VERSION ""

NS_ :

BS_:

BU_: AIL CAB C_ECU C_ECU_GW

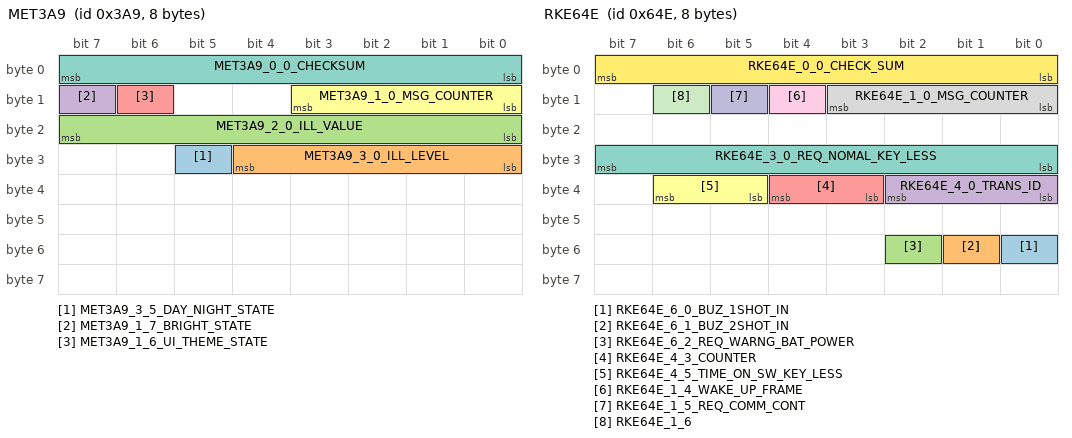
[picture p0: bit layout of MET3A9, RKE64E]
BO_ 937 MET3A9: 8 C_ECU_GW
 SG_ MET3A9_3_5_DAY_NIGHT_STATE : 29|1@1+ (1,0) [0|1] ""  AIL,CAB
 SG_ MET3A9_3_0_ILL_LEVEL : 24|5@1+ (1,0) [0|21] ""  AIL
 SG_ MET3A9_2_0_ILL_VALUE : 16|8@1+ (0.4,0) [0|100] "%"  AIL,CAB
 SG_ MET3A9_1_7_BRIGHT_STATE : 15|1@1+ (1,0) [0|1] ""  AIL,CAB
 SG_ MET3A9_1_6_UI_THEME_STATE : 14|1@1+ (1,0) [0|1] "" Vector__XXX
 SG_ MET3A9_1_0_MSG_COUNTER : 8|4@1+ (1,0) [0|15] ""  AIL,CAB
 SG_ MET3A9_0_0_CHECKSUM : 0|8@1+ (1,0) [0|255] ""  AIL,CAB

BO_ 1614 RKE64E: 8 C_ECU_GW
 SG_ RKE64E_6_0_BUZ_1SHOT_IN : 48|1@1+ (1,0) [0|1] "" Vector__XXX
 SG_ RKE64E_6_1_BUZ_2SHOT_IN : 49|1@1+ (1,0) [0|1] "" Vector__XXX
 SG_ RKE64E_6_2_REQ_WARNG_BAT_POWER : 50|1@1+ (1,0) [0|1] ""  AIL
 SG_ RKE64E_4_0_TRANS_ID : 32|3@1+ (1,0) [0|4] "" Vector__XXX
 SG_ RKE64E_4_3_COUNTER : 35|2@1+ (1,0) [0|3] "" Vector__XXX
 SG_ RKE64E_4_5_TIME_ON_SW_KEY_LESS : 37|2@1+ (1,0) [0|3] "" Vector__XXX
 SG_ RKE64E_3_0_REQ_NOMAL_KEY_LESS : 24|8@1+ (1,0) [0|8] "" Vector__XXX
 SG_ RKE64E_1_0_MSG_COUNTER : 8|4@1+ (1,0) [0|15] ""  AIL
 SG_ RKE64E_1_4_WAKE_UP_FRAME : 12|1@1+ (1,0) [0|1] "" Vector__XXX
 SG_ RKE64E_1_5_REQ_COMM_CONT : 13|1@1+ (1,0) [0|1] "" Vector__XXX
 SG_ RKE64E_1_6 : 14|1@1+ (1,0) [0|1] "" Vector__XXX
 SG_ RKE64E_0_0_CHECK_SUM : 0|8@1+ (1,0) [0|255] ""  AIL

BO_ 826 ABG33A: 8 C_ECU_GW
 SG_ ABG33A_7_0_VELOCITYCHANGE_VX_MAX : 56|8@1+ (1,0) [-101|101] "km/h" Vector__XXX
 SG_ ABG33A_6_0_VELOCITYCHANGE_VX_MAX : 48|8@1+ (1,0) [-101|101] "km/h" Vector__XXX
 SG_ ABG33A_5_0_P_SIDE_ABG_DEPLOY : 40|1@1+ (1,0) [0|1] "" Vector__XXX
 SG_ ABG33A_5_1_D_SIDE_ABG_DEPLOY : 41|1@1+ (1,0) [0|1] "" Vector__XXX
 SG_ ABG33A_5_2_FRONT_FAR_ABG_DEPLOY : 42|1@1+ (1,0) [0|1] "" Vector__XXX
 SG_ ABG33A_5_3_REAR_FAR_ABG_DEPLOY : 43|1@1+ (1,0) [0|1] "" Vector__XXX
 SG_ ABG33A_5_4_REAR_RH_ABG_DEPLOY : 44|1@1+ (1,0) [0|1] "" Vector__XXX
 SG_ ABG33A_5_5_REAR_LH_ABG_DEPLOY : 45|1@1+ (1,0) [0|1] "" Vector__XXX
 SG_ ABG33A_5_6_P_CURTAIN_ABG_DEPLOY : 46|1@1+ (1,0) [0|1] "" Vector__XXX
 SG_ ABG33A_5_7_D_CURTAIN_ABG_DEPLOY : 47|1@1+ (1,0) [0|1] "" Vector__XXX
 SG_ ABG33A_4_0_D_FRONT_ABG_DEPLOY : 32|1@1+ (1,0) [0|1] "" Vector__XXX
 SG_ ABG33A_4_1_P_FRONT_ABG_DEPLOY : 33|1@1+ (1,0) [0|1] "" Vector__XXX
 SG_ ABG33A_4_2_P_ABG_DEPLOY : 34|1@1+ (1,0) [0|1] "" Vector__XXX
 SG_ ABG33A_4_3_D_ABG_DEPLOY : 35|1@1+ (1,0) [0|1] "" Vector__XXX
 SG_ ABG33A_4_4_P_BELT_PRETENTION : 36|1@1+ (1,0) [0|1] "" Vector__XXX
 SG_ ABG33A_4_5_D_BELT_PRETENTION : 37|1@1+ (1,0) [0|1] "" Vector__XXX
 SG_ ABG33A_4_6_D_KNEE_ABG_DEPLOY : 38|1@1+ (1,0) [0|1] "" Vector__XXX
 SG_ ABG33A_4_7_P_KNEE_ABG_DEPLOY : 39|1@1+ (1,0) [0|1] "" Vector__XXX
 SG_ ABG33A_3_0_BELT_WRNING_PASS : 24|2@1+ (1,0) [0|3] "" Vector__XXX
 SG_ ABG33A_3_2_BUCKLESW_DRVR : 26|2@1+ (1,0) [0|3] "" Vector__XXX
 SG_ ABG33A_3_4_OCCUPATION_PASS : 28|2@1+ (1,0) [0|3] ""  CAB
 SG_ ABG33A_3_6_IND_ACT_ABG_PASS : 30|2@1+ (1,0) [0|3] "" Vector__XXX
 SG_ ABG33A_2_0_IND_WARN_ABG : 16|2@1+ (1,0) [0|3] "" Vector__XXX
 SG_ ABG33A_2_2_DETECT_CRUSH : 18|3@1+ (1,0) [0|7] "" Vector__XXX
 SG_ ABG33A_2_5_STATUS_CRUSH_ECALL : 21|3@1+ (1,0) [0|7] "" Vector__XXX
 SG_ ABG33A_1_0_MSG_COUNTER : 8|4@1+ (1,0) [0|15] ""  CAB
 SG_ ABG33A_1_4_FLG_ABGIND_CTRL : 12|1@1+ (1,0) [0|1] "" Vector__XXX
 SG_ ABG33A_1_5_REQ_COMM_CONT : 13|1@1+ (1,0) [0|1] "" Vector__XXX
 SG_ ABG33A_1_6_COLLISION_COUNTER : 14|2@1+ (1,0) [0|3] "" Vector__XXX
 SG_ ABG33A_0_0_CHECK_SUM : 0|8@1+ (1,0) [0|255] ""  CAB

BO_ 961 DMS3C1: 8 C_ECU_GW
 SG_ DMS3C1_7_4_SHORT_DIST_DETECT : 60|1@1+ (1,0) [0|1] "" Vector__XXX
 SG_ DMS3C1_7_5_PRESENCE_DETECT : 61|1@1+ (1,0) [0|1] ""  CAB
 SG_ DMS3C1_7_6_RADER_EQUIP : 62|1@1+ (1,0) [0|1] "" Vector__XXX
 SG_ DMS3C1_7_7_LOSING_POSTURE_DETECT : 63|1@1+ (1,0) [0|1] "" Vector__XXX
 SG_ DMS3C1_6_0_ID_RECOG_CANCEL : 48|1@1+ (1,0) [0|1] "" Vector__XXX
 SG_ DMS3C1_6_1_ID_ENABLE_FLAG : 49|1@1+ (1,0) [0|1] "" Vector__XXX
 SG_ DMS3C1_6_2_PERMIT_AVN_FLAG : 50|1@1+ (1,0) [0|1] "" Vector__XXX
 SG_ DMS3C1_6_4_DISTRACTION_STATUS : 52|1@1+ (1,0) [0|1] ""  AIL,CAB
 SG_ DMS3C1_6_5_DROWSINESS_STATUS : 53|1@1+ (1,0) [0|1] "" Vector__XXX
 SG_ DMS3C1_6_6_DROWSINESS_LV2_STATUS : 54|1@1+ (1,0) [0|1] "" Vector__XXX
 SG_ DMS3C1_6_7_NOT_DETECTED_STATUS : 55|1@1+ (1,0) [0|1] "" Vector__XXX
 SG_ DMS3C1_5_0_ID_LIST : 40|5@1+ (1,0) [0|31] "" Vector__XXX
 SG_ DMS3C1_5_5_ID_EDIT_FLAG : 45|3@1+ (1,0) [0|6] "" Vector__XXX
 SG_ DMS3C1_4_0_DMS_IND_REQ_FLAG : 32|3@1+ (1,0) [0|7] "" Vector__XXX
 SG_ DMS3C1_4_3_DMS_RECOG_STATUS : 35|1@1+ (1,0) [0|1] "" Vector__XXX
 SG_ DMS3C1_4_4_DRIVER_STATUS : 36|4@1+ (1,0) [0|3] "" Vector__XXX
 SG_ DMS3C1_3_0_DRIVER_REGIST_ID : 24|4@1+ (1,0) [0|15] ""  AIL,CAB
 SG_ DMS3C1_3_4_CUST_EDIT_FLAG : 28|2@1+ (1,0) [0|3] "" Vector__XXX
 SG_ DMS3C1_3_6_ID_RECOG_FLAG : 30|1@1+ (1,0) [0|1] "" Vector__XXX
 SG_ DMS3C1_2_0_LEVEL_DROWS : 16|3@1+ (1,0) [0|2] "" Vector__XXX
 SG_ DMS3C1_2_3_DROWS_DETECT_FLAG : 19|1@1+ (1,0) [0|1] "" Vector__XXX
 SG_ DMS3C1_2_7_DIST_DETECT_FLAG : 23|1@1+ (1,0) [0|1] ""  AIL,CAB
 SG_ DMS3C1_1_0_MSG_COUNTER : 8|4@1+ (1,0) [0|15] ""  AIL
 SG_ DMS3C1_1_4_WAKE_UP_FRAME : 12|1@1+ (1,0) [0|1] "" Vector__XXX
 SG_ DMS3C1_1_5_REQ_COMM_CONT : 13|1@1+ (1,0) [0|1] "" Vector__XXX
 SG_ DMS3C1_1_7_EYE_DIST_FLAG : 15|1@1+ (1,0) [0|1] "" Vector__XXX
 SG_ DMS3C1_0_0_CHKSUM : 0|8@1+ (1,0) [0|255] ""  AIL

BO_ 1651 ACN673: 8 C_ECU_GW
 SG_ ACN673_7_2_REQ_STRG_H : 58|2@1+ (1,0) [0|3] "" Vector__XXX
 SG_ ACN673_7_1_SEAT_H_L_AUTOIND : 57|1@1+ (1,0) [0|1] "" Vector__XXX
 SG_ ACN673_7_0_SEAT_H_R_AUTOIND : 56|1@1+ (1,0) [0|1] "" Vector__XXX
 SG_ ACN673_6_0_RR_FAN_SYMBOL : 48|1@1+ (1,0) [0|1] "" Vector__XXX
 SG_ ACN673_6_2_SEAT_H_R : 50|3@1+ (1,0) [0|7] "" Vector__XXX
 SG_ ACN673_6_5_SEAT_H_L : 53|3@1+ (1,0) [0|7] "" Vector__XXX
 SG_ ACN673_5_0_DR_ONLY : 40|2@1+ (1,0) [0|3] "" Vector__XXX
 SG_ ACN673_5_2_STRG_H : 42|2@1+ (1,0) [0|3] "" Vector__XXX
 SG_ ACN673_5_4_AC_SI_DS_SET : 44|2@1+ (1,0) [0|3] "" Vector__XXX
 SG_ ACN673_5_6_STRG_H_AUTOIND : 46|1@1+ (1,0) [0|1] "" Vector__XXX
 SG_ ACN673_5_7_AC_SI_DS_FLG : 47|1@1+ (1,0) [0|1] "" Vector__XXX
 SG_ ACN673_4_0_SEAT_HEATER_DR : 32|2@1+ (1,0) [0|3] ""  CAB
 SG_ ACN673_4_2_SEAT_HEATER_PA : 34|2@1+ (1,0) [0|3] ""  CAB
 SG_ ACN673_4_4_SEAT_HEATER : 36|1@1+ (1,0) [0|1] ""  CAB
 SG_ ACN673_4_5_TEMP_SET_TYPE : 37|2@1+ (1,0) [0|3] "" Vector__XXX
 SG_ ACN673_4_7_VENTI_SEAT_EX_HI : 39|1@1+ (1,0) [0|1] "" Vector__XXX
 SG_ ACN673_1_0_MSG_COUNTER : 8|4@1+ (1,0) [0|15] ""  CAB
 SG_ ACN673_1_6_SYNC_RR : 14|1@1+ (1,0) [0|1] "" Vector__XXX
 SG_ ACN673_1_7_RR_LOCK : 15|1@1+ (1,0) [0|1] "" Vector__XXX
 SG_ ACN673_0_0_CHECK_SUM : 0|8@1+ (1,0) [0|255] ""  CAB

BO_ 1650 ACN672: 8 C_ECU_GW
 SG_ ACN672_7_0_INFO_AUTO3MODE : 56|2@1+ (1,0) [0|3] "" Vector__XXX
 SG_ ACN672_7_2_INFO_REAR_TEMP : 58|6@1+ (1,0) [0|44] "" Vector__XXX
 SG_ ACN672_6_0_DEF : 48|1@1+ (1,0) [0|1] "" Vector__XXX
 SG_ ACN672_6_1_FAN_SYMBOL : 49|1@1+ (1,0) [0|1] "" Vector__XXX
 SG_ ACN672_6_2_REAR_MODE : 50|2@1+ (1,0) [0|3] "" Vector__XXX
 SG_ ACN672_6_4_UNIT_TEMP : 52|1@1+ (1,0) [0|1] "" Vector__XXX
 SG_ ACN672_6_5_SPEC_AC_UNIT : 53|2@1+ (1,0) [0|3] "" Vector__XXX
 SG_ ACN672_6_7_REAR_AC : 55|1@1+ (1,0) [0|1] "" Vector__XXX
 SG_ ACN672_5_0_AC_VR_MODE : 40|2@1+ (1,0) [0|3] "" Vector__XXX
 SG_ ACN672_5_2_INFO_TEMP_PASS : 42|6@1+ (1,0) [0|63] ""  AIL
 SG_ ACN672_4_0_AC_INTERRUPT_DISPLAY : 32|1@1+ (1,0) [0|1] "" Vector__XXX
 SG_ ACN672_4_1_AC_VR_ACTION : 33|1@1+ (1,0) [0|1] "" Vector__XXX
 SG_ ACN672_4_2_INFO_TEMP_DRVR : 34|6@1+ (1,0) [0|63] ""  AIL
 SG_ ACN672_3_0_MAX_AC : 24|1@1+ (1,0) [0|1] ""  CAB
 SG_ ACN672_3_1_INFO_SYNC_OR_SING : 25|1@1+ (1,0) [0|1] "" Vector__XXX
 SG_ ACN672_3_2_INFO_FULL_OR_AUTO : 26|2@1+ (1,0) [0|3] ""  CAB
 SG_ ACN672_3_4_INFO_AC_ON : 28|1@1+ (1,0) [0|1] ""  CAB
 SG_ ACN672_3_5_INFO_RDEF : 29|1@1+ (1,0) [0|1] "" Vector__XXX
 SG_ ACN672_3_6_INFO_CIRCULATION : 30|2@1+ (1,0) [0|3] "" Vector__XXX
 SG_ ACN672_2_0_INFO_MODE_VENT : 16|4@1+ (1,0) [0|15] "" Vector__XXX
 SG_ ACN672_2_4_INFO_FANONLY : 20|1@1+ (1,0) [0|1] "" Vector__XXX
 SG_ ACN672_2_5_INFO_LEV_BLOWERFAN : 21|3@1+ (1,0) [0|7] "" Vector__XXX
 SG_ ACN672_1_0_MSG_COUNTER : 8|4@1+ (1,0) [0|15] ""  AIL,CAB
 SG_ ACN672_1_4_LVL_BLOWERFAN_RR : 12|3@1+ (1,0) [0|7] "" Vector__XXX
 SG_ ACN672_1_7_REAR_AUTO : 15|1@1+ (1,0) [0|1] "" Vector__XXX
 SG_ ACN672_0_0_CHECK_SUM : 0|8@1+ (1,0) [0|255] ""  AIL,CAB

BO_ 722 ACN2D2: 8 C_ECU_GW
 SG_ ACN2D2_7_0_PD_PRESSURE : 56|8@1+ (0.0146866,0) [0|3.74509] "Mpa" Vector__XXX
 SG_ ACN2D2_6_0_TRQ_COMP_ESTM : 48|8@1+ (0.3921568627451,0) [0|100] "Nm" Vector__XXX
 SG_ ACN2D2_5_0_REQ_ENG_RPM : 40|3@1+ (1,0) [0|6] "" Vector__XXX
 SG_ ACN2D2_5_3_REQ_IDLE_COMP_RPM : 43|5@1+ (25,650) [650|1425] "rpm" Vector__XXX
 SG_ ACN2D2_4_0_LVL_PTC : 32|2@1+ (1,0) [0|3] "" Vector__XXX
 SG_ ACN2D2_4_2_MARGIN_OF_AC : 34|3@1+ (1,0) [0|7] "" Vector__XXX
 SG_ ACN2D2_4_5_LVL_BLOWER_FAN : 37|3@1+ (1,0) [0|7] "" Vector__XXX
 SG_ ACN2D2_3_0_PERMIT_ISS : 24|2@1+ (1,0) [0|3] "" Vector__XXX
 SG_ ACN2D2_3_2_TRQ_PAT_COMP_ESTM : 26|3@1+ (1,0) [0|6] "" Vector__XXX
 SG_ ACN2D2_3_5_IND_ROOM_TEMP : 29|3@1+ (1,0) [0|4] "" Vector__XXX
 SG_ ACN2D2_2_0_FAIL_TRQ_COMP_ESTM : 16|1@1+ (1,0) [0|1] "" Vector__XXX
 SG_ ACN2D2_2_1_FAIL_AC : 17|1@1+ (1,0) [0|1] "" Vector__XXX
 SG_ ACN2D2_2_2_REQ_INHIBIT_LOCKUP : 18|1@1+ (1,0) [0|1] "" Vector__XXX
 SG_ ACN2D2_2_3_AC_ON : 19|1@1+ (1,0) [0|1] "" Vector__XXX
 SG_ ACN2D2_2_4_RDEFOGSW : 20|1@1+ (1,0) [0|1] "" Vector__XXX
 SG_ ACN2D2_2_5_WARM_UP : 21|1@1+ (1,0) [0|1] "" Vector__XXX
 SG_ ACN2D2_2_6_AC_AUTO_MANUAL : 22|1@1+ (1,0) [0|1] "" Vector__XXX
 SG_ ACN2D2_2_7_COMP_TYPE : 23|1@1+ (1,0) [0|1] "" Vector__XXX
 SG_ ACN2D2_1_0_MSG_COUNTER : 8|4@1+ (1,0) [0|15] "" Vector__XXX
 SG_ ACN2D2_1_4 : 12|1@1+ (1,0) [0|1] "" Vector__XXX
 SG_ ACN2D2_1_5 : 13|1@1+ (1,0) [0|1] "" Vector__XXX
 SG_ ACN2D2_1_6 : 14|1@1+ (1,0) [0|1] "" Vector__XXX
 SG_ ACN2D2_1_7_WARM_POWER_CONT : 15|1@1+ (1,0) [0|1] "" Vector__XXX
 SG_ ACN2D2_0_0_CHECK_SUM : 0|8@1+ (1,0) [0|255] "" Vector__XXX

BO_ 1722 AVN6BA: 8 C_ECU_GW
 SG_ AVN6BA_7_0_GUIDE_LINE_REAR : 56|1@1+ (1,0) [0|1] "" Vector__XXX
 SG_ AVN6BA_7_1_GUIDE_LINE_SIDE : 57|1@1+ (1,0) [0|1] "" Vector__XXX
 SG_ AVN6BA_7_2_GUIDE_LINE_FRONT : 58|1@1+ (1,0) [0|1] "" Vector__XXX
 SG_ AVN6BA_7_3_STEER_ANGLE_INTERLOCK : 59|1@1+ (1,0) [0|1] "" Vector__XXX
 SG_ AVN6BA_7_4_BACK_CAMERA_DELAY : 60|1@1+ (1,0) [0|1] "" Vector__XXX
 SG_ AVN6BA_7_5_REQ_STOP_CAMERA_OUT : 61|1@1+ (1,0) [0|1] "" Vector__XXX
 SG_ AVN6BA_7_6_VIEW_CHANGE_SW : 62|2@1+ (1,0) [0|3] "" Vector__XXX
 SG_ AVN6BA_6_0_CLIMAITE_PA_TEMP : 48|6@1- (0.5,13) [1|44] "℃/?" Vector__XXX
 SG_ AVN6BA_6_6_CLIMATE_SYNC : 54|1@1+ (1,0) [0|1] "" Vector__XXX
 SG_ AVN6BA_6_7_CLIMATE_F_DEF : 55|1@1+ (1,0) [0|1] "" Vector__XXX
 SG_ AVN6BA_5_0_CLIMAITE_DR_TEMP : 40|6@1- (0.5,13) [1|44] "℃/?" Vector__XXX
 SG_ AVN6BA_5_6_CLIMAITE_AUTO : 46|1@1+ (1,0) [0|1] "" Vector__XXX
 SG_ AVN6BA_5_7_CLIMAITE_MAX_AC : 47|1@1+ (1,0) [0|1] "" Vector__XXX
 SG_ AVN6BA_4_0_CLIMAITE_VR : 32|3@1+ (1,0) [0|4] "" Vector__XXX
 SG_ AVN6BA_4_3_CLIMATE_AC : 35|1@1+ (1,0) [0|1] "" Vector__XXX
 SG_ AVN6BA_4_4_CLIMAITE_FAN : 36|4@1+ (1,0) [0|15] "" Vector__XXX
 SG_ AVN6BA_3_0_PERSONAL_IC_SH : 24|3@1+ (1,0) [0|7] "" Vector__XXX
 SG_ AVN6BA_3_4_CSTM_SONNER : 28|1@1+ (1,0) [0|1] "" Vector__XXX
 SG_ AVN6BA_3_5_CSTM_RAB : 29|1@1+ (1,0) [0|1] "" Vector__XXX
 SG_ AVN6BA_3_6_REQ_CHG_CSTM_RAB : 30|1@1+ (1,0) [0|1] "" Vector__XXX
 SG_ AVN6BA_3_7_CLIMATE_R_DEF : 31|1@1+ (1,0) [0|1] "" Vector__XXX
 SG_ AVN6BA_2_0_CLIMATE_PTC : 16|1@1+ (1,0) [0|1] "" Vector__XXX
 SG_ AVN6BA_2_1_CLIMATE_MODE : 17|1@1+ (1,0) [0|1] "" Vector__XXX
 SG_ AVN6BA_2_2_CLIMATE_SEAT_C_L : 18|1@1+ (1,0) [0|1] "" Vector__XXX
 SG_ AVN6BA_2_3_CLIMATE_SEAT_C_R : 19|1@1+ (1,0) [0|1] "" Vector__XXX
 SG_ AVN6BA_2_4_CLIMATE_SEAT_H_L : 20|1@1+ (1,0) [0|1] "" Vector__XXX
 SG_ AVN6BA_2_5_CLIMATE_SEAT_H_R : 21|1@1+ (1,0) [0|1] "" Vector__XXX
 SG_ AVN6BA_2_6_CLIMATE_INNER_AIR : 22|1@1+ (1,0) [0|1] "" Vector__XXX
 SG_ AVN6BA_2_7_CLIMATE_ON_OFF : 23|1@1+ (1,0) [0|1] "" Vector__XXX
 SG_ AVN6BA_1_0_MSG_COUNTER : 8|4@1+ (1,0) [0|15] "" Vector__XXX
 SG_ AVN6BA_1_4_CLIMAITE_STATUS : 12|3@1+ (1,0) [0|7] ""  CAB
 SG_ AVN6BA_1_7_CLIMAITE_ON_OFF : 15|1@1+ (1,0) [0|1] "" Vector__XXX
 SG_ AVN6BA_0_0_CHECK_SUM : 0|8@1+ (1,0) [0|255] "" Vector__XXX

BO_ 1019 AVN3FB: 8 C_ECU_GW
 SG_ AVN3FB_7_0_SMT_TIM_RESET_REQ : 56|1@1+ (1,0) [0|1] "" Vector__XXX
 SG_ AVN3FB_7_1_SMT_EG_CSTM_REQ : 57|1@1+ (1,0) [0|1] "" Vector__XXX
 SG_ AVN3FB_7_2_EYE_YEILD_CSTM : 58|1@1+ (1,0) [0|1] "" Vector__XXX
 SG_ AVN3FB_7_3_EYE_STOP_CSTM : 59|1@1+ (1,0) [0|1] "" Vector__XXX
 SG_ AVN3FB_7_4_EYE_NO_ENTRY_CSTM : 60|1@1+ (1,0) [0|1] "" Vector__XXX
 SG_ AVN3FB_7_5_MVS_CAMERA_SELECT_SW : 61|1@1+ (1,0) [0|1] "" Vector__XXX
 SG_ AVN3FB_7_7_ACPANEL_DR_ONLY : 63|1@1+ (1,0) [0|1] "" Vector__XXX
 SG_ AVN3FB_6_0_ACPANEL_PA_TEMP : 48|6@1+ (0.5,13) [1|44] "℃/?"  AIL,CAB
 SG_ AVN3FB_6_6_ACPANEL_MODE_DOWN : 54|1@1+ (1,0) [0|1] "" Vector__XXX
 SG_ AVN3FB_6_7_ACPANEL_MODE_UP : 55|1@1+ (1,0) [0|1] "" Vector__XXX
 SG_ AVN3FB_5_0_ACPANEL_DR_TEMP : 40|6@1+ (0.5,13) [1|44] "℃/?"  AIL,CAB
 SG_ AVN3FB_5_6_ACPANEL_FAN_DOWN : 46|1@1+ (1,0) [0|1] "" Vector__XXX
 SG_ AVN3FB_5_7_ACPANEL_FAN_UP : 47|1@1+ (1,0) [0|1] "" Vector__XXX
 SG_ AVN3FB_4_0_ACPANEL_FAN_LEVEL : 32|4@1+ (1,0) [0|15] "" Vector__XXX
 SG_ AVN3FB_4_4_ACPANEL_MODE_VENT : 36|4@1+ (1,0) [0|15] "" Vector__XXX
 SG_ AVN3FB_3_0_ACPANEL_PA_TEMP_DOWN : 24|1@1+ (1,0) [0|1] ""  AIL,CAB
 SG_ AVN3FB_3_1_ACPANEL_PA_TEMP_UP : 25|1@1+ (1,0) [0|1] ""  AIL,CAB
 SG_ AVN3FB_3_2_ACPANEL_DR_TEMP_DOWN : 26|1@1+ (1,0) [0|1] ""  AIL,CAB
 SG_ AVN3FB_3_3_ACPANEL_DR_TEMP_UP : 27|1@1+ (1,0) [0|1] ""  AIL,CAB
 SG_ AVN3FB_3_4_ACPANEL_SYNC : 28|1@1+ (1,0) [0|1] "" Vector__XXX
 SG_ AVN3FB_3_5_ACPANEL_AC : 29|1@1+ (1,0) [0|1] "" Vector__XXX
 SG_ AVN3FB_3_6_F_DEF_SW : 30|1@1+ (1,0) [0|1] "" Vector__XXX
 SG_ AVN3FB_3_7_R_DEF_SW : 31|1@1+ (1,0) [0|1] "" Vector__XXX
 SG_ AVN3FB_2_0_ACPANEL_AUTO : 16|1@1+ (1,0) [0|1] "" Vector__XXX
 SG_ AVN3FB_2_1_ACPANEL_MAX_AC : 17|1@1+ (1,0) [0|1] "" Vector__XXX
 SG_ AVN3FB_2_2_ACPANEL_SEAT_C_P : 18|1@1+ (1,0) [0|1] "" Vector__XXX
 SG_ AVN3FB_2_3_ACPANEL_SEAT_C_D : 19|1@1+ (1,0) [0|1] "" Vector__XXX
 SG_ AVN3FB_2_4_ACPANEL_SEAT_H_P : 20|1@1+ (1,0) [0|1] "" Vector__XXX
 SG_ AVN3FB_2_5_ACPANEL_SEAT_H_D : 21|1@1+ (1,0) [0|1] "" Vector__XXX
 SG_ AVN3FB_2_6_ACPANEL_INNER_AIR : 22|1@1+ (1,0) [0|1] "" Vector__XXX
 SG_ AVN3FB_2_7_ACPANEL_AC_ON_OFF : 23|1@1+ (1,0) [0|1] "" Vector__XXX
 SG_ AVN3FB_1_0_MSG_COUNTER : 8|4@1+ (1,0) [0|15] ""  AIL
 SG_ AVN3FB_1_4_EYE_CSTM_REQ_3FB : 12|1@1+ (1,0) [0|1] "" Vector__XXX
 SG_ AVN3FB_1_5_DDAW_WARNING_CSTM : 13|1@1+ (1,0) [0|1] "" Vector__XXX
 SG_ AVN3FB_1_6_SIGN_SWITCH_SND : 14|1@1+ (1,0) [0|1] "" Vector__XXX
 SG_ AVN3FB_1_7_SLWF_CSTM : 15|1@1+ (1,0) [0|1] "" Vector__XXX
 SG_ AVN3FB_0_0_CHECK_SUM : 0|8@1+ (1,0) [0|255] ""  AIL

BO_ 1366 CAB556: 8 CAB
 SG_ CAB556_0_0_NETWORK_STATUS : 0|64@1+ (1,0) [0|0] ""  C_ECU

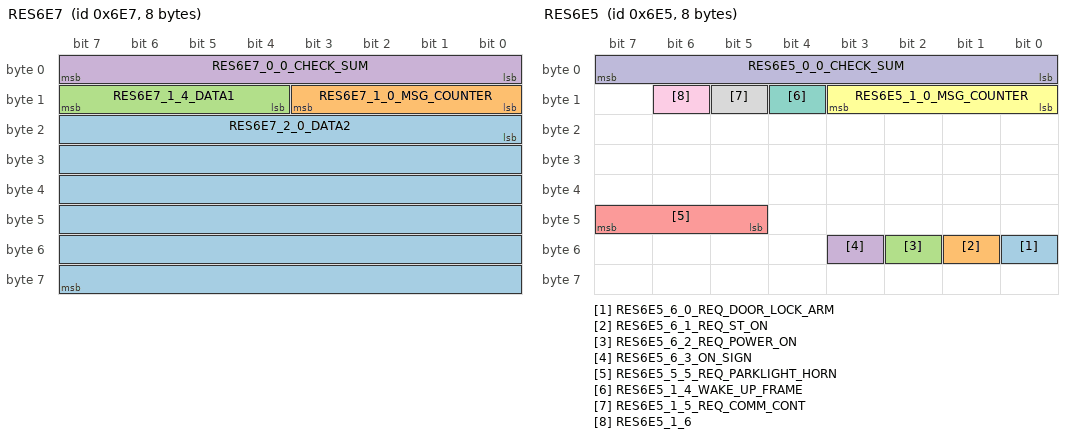
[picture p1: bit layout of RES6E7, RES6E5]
BO_ 1767 RES6E7: 8 Vector__XXX
 SG_ RES6E7_2_0_DATA2 : 16|48@1+ (1,0) [0|281474976700000] ""  C_ECU_GW
 SG_ RES6E7_1_0_MSG_COUNTER : 8|4@1+ (1,0) [0|15] ""  C_ECU_GW
 SG_ RES6E7_1_4_DATA1 : 12|4@1+ (1,0) [0|15] ""  C_ECU_GW
 SG_ RES6E7_0_0_CHECK_SUM : 0|8@1+ (1,0) [0|255] ""  C_ECU_GW

BO_ 1765 RES6E5: 8 Vector__XXX
 SG_ RES6E5_6_0_REQ_DOOR_LOCK_ARM : 48|1@1+ (1,0) [0|1] ""  C_ECU_GW
 SG_ RES6E5_6_1_REQ_ST_ON : 49|1@1+ (1,0) [0|1] ""  C_ECU_GW
 SG_ RES6E5_6_2_REQ_POWER_ON : 50|1@1+ (1,0) [0|1] ""  C_ECU_GW
 SG_ RES6E5_6_3_ON_SIGN : 51|1@1+ (1,0) [0|1] ""  C_ECU_GW
 SG_ RES6E5_5_5_REQ_PARKLIGHT_HORN : 45|3@1+ (1,0) [0|4] ""  C_ECU_GW
 SG_ RES6E5_1_0_MSG_COUNTER : 8|4@1+ (1,0) [0|15] ""  C_ECU_GW
 SG_ RES6E5_1_4_WAKE_UP_FRAME : 12|1@1+ (1,0) [0|1] ""  C_ECU_GW
 SG_ RES6E5_1_5_REQ_COMM_CONT : 13|1@1+ (1,0) [0|1] ""  C_ECU_GW
 SG_ RES6E5_1_6 : 14|1@1+ (1,0) [0|1] ""  C_ECU_GW
 SG_ RES6E5_0_0_CHECK_SUM : 0|8@1+ (1,0) [0|255] ""  C_ECU_GW

BO_ 1696 AIL6A0: 8 AIL
 SG_ AIL6A0_7_0_AIL_RENDER_STA : 56|3@1+ (1,0) [0|7] ""  C_ECU_GW
 SG_ AIL6A0_7_3_AIL_RENDER_PAT_A_DIS : 59|1@1+ (1,0) [0|1] ""  C_ECU_GW
 SG_ AIL6A0_7_4_AIL_RENDER_PAT_B_DIS : 60|1@1+ (1,0) [0|1] ""  C_ECU_GW
 SG_ AIL6A0_7_5_AIL_RENDER_PAT_C_DIS : 61|1@1+ (1,0) [0|1] ""  C_ECU_GW
 SG_ AIL6A0_7_6_AIL_RENDER_PAT_D_DIS : 62|1@1+ (1,0) [0|1] ""  C_ECU_GW
 SG_ AIL6A0_7_7_AIL_RENDER_DR_MD_DIS : 63|1@1+ (1,0) [0|1] ""  C_ECU_GW
 SG_ AIL6A0_6_0_AIL_FIRST_BRIGHT_STA : 48|4@1+ (1,0) [0|9] ""  C_ECU_GW
 SG_ AIL6A0_6_4_AIL_SECOND_BRIGHT_STA : 52|4@1+ (1,0) [0|15] ""  C_ECU_GW
 SG_ AIL6A0_5_0_AIL_SECOND_COLOR_STA : 40|6@1+ (1,0) [0|63] ""  C_ECU_GW
 SG_ AIL6A0_5_6_AIL_CSTM_PRS_DIS_REQ : 46|1@1+ (1,0) [0|1] ""  C_ECU_GW
 SG_ AIL6A0_5_7_AIL_RENDER_CSTM_DIS : 47|1@1+ (1,0) [0|1] ""  C_ECU_GW
 SG_ AIL6A0_4_0_AIL_FIRST_COLOR_STA : 32|6@1+ (1,0) [0|63] ""  C_ECU_GW
 SG_ AIL6A0_4_6_AIL_SECOND_COLOR_DIS : 38|1@1+ (1,0) [0|1] ""  C_ECU_GW
 SG_ AIL6A0_4_7_AIL_SECOND_BRIGHT_DIS : 39|1@1+ (1,0) [0|1] ""  C_ECU_GW
 SG_ AIL6A0_3_0_AIL_ADAS_VEH_DIS_STA : 24|1@1+ (1,0) [0|1] ""  C_ECU_GW
 SG_ AIL6A0_3_1_AIL_ADAS_VEH_DIS__DIS : 25|1@1+ (1,0) [0|1] ""  C_ECU_GW
 SG_ AIL6A0_3_2_AIL_ADAS_LANE_DEV_STA : 26|1@1+ (1,0) [0|1] ""  C_ECU_GW
 SG_ AIL6A0_3_3_AIL_ADAS_LANE_DEV_DIS : 27|1@1+ (1,0) [0|1] ""  C_ECU_GW
 SG_ AIL6A0_3_4_AIL_ADAS_FT_CROSS_STA : 28|1@1+ (1,0) [0|1] ""  C_ECU_GW
 SG_ AIL6A0_3_5_AIL_ADAS_FT_CROSS_DIS : 29|1@1+ (1,0) [0|1] ""  C_ECU_GW
 SG_ AIL6A0_3_6_AIL_ADAS_HANDS_FR_STA : 30|1@1+ (1,0) [0|1] ""  C_ECU_GW
 SG_ AIL6A0_3_7_AIL_ADAS_HANDS_FR_DIS : 31|1@1+ (1,0) [0|1] ""  C_ECU_GW
 SG_ AIL6A0_2_0_AIL_ADAS_EXP_STA : 16|1@1+ (1,0) [0|1] ""  C_ECU_GW
 SG_ AIL6A0_2_1_AIL_ADAS_EXP_DIS : 17|1@1+ (1,0) [0|1] ""  C_ECU_GW
 SG_ AIL6A0_2_2_AIL_NOTIFI_EXP_STA : 18|1@1+ (1,0) [0|1] ""  C_ECU_GW
 SG_ AIL6A0_2_3_AIL_NOTIFI_EXP_DIS : 19|1@1+ (1,0) [0|1] ""  C_ECU_GW
 SG_ AIL6A0_2_4_AIL_AIR_CON_EXP_STA : 20|1@1+ (1,0) [0|1] ""  C_ECU_GW
 SG_ AIL6A0_2_5_AIL_AIR_CON_EXP_DIS : 21|1@1+ (1,0) [0|1] ""  C_ECU_GW
 SG_ AIL6A0_1_0_MSG_COUNTER : 8|4@1+ (1,0) [0|15] ""  C_ECU_GW
 SG_ AIL6A0_1_4_AIL_ON_OFF_STA : 12|1@1+ (1,0) [0|1] ""  C_ECU_GW
 SG_ AIL6A0_1_6_AIL_WEL_FOL_STA : 14|1@1+ (1,0) [0|1] ""  C_ECU_GW
 SG_ AIL6A0_1_7_AIL_WEL_FOL_DIS : 15|1@1+ (1,0) [0|1] ""  C_ECU_GW
 SG_ AIL6A0_0_0_CHECK_SUM : 0|8@1+ (1,0) [0|255] ""  C_ECU_GW

BO_ 1314 AIL522: 8 AIL
 SG_ AIL522_1_4_ActiveWakeUpBit : 12|1@1+ (1,0) [0|1] ""  C_ECU
 SG_ AIL522_0_0_SourceNodeID : 0|8@1+ (1,0) [0|255] ""  C_ECU

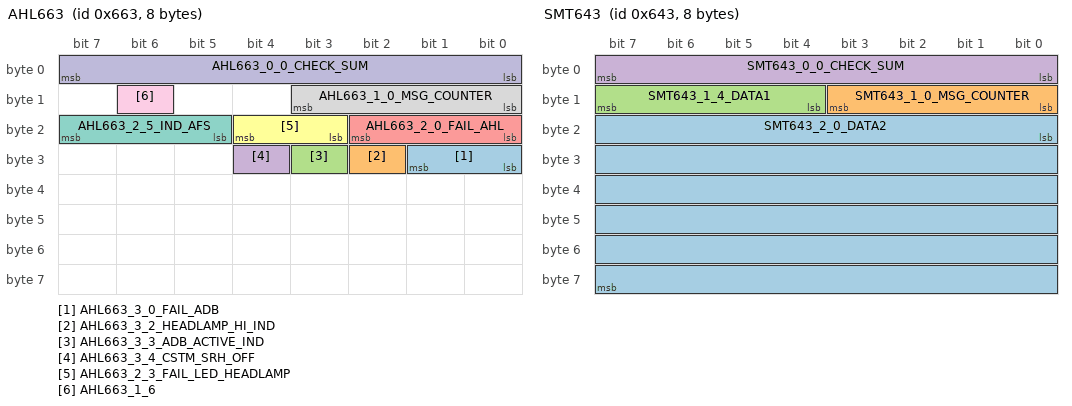
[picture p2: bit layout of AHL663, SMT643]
BO_ 1635 AHL663: 8 C_ECU_GW
 SG_ AHL663_3_0_FAIL_ADB : 24|2@1+ (1,0) [0|3] "" Vector__XXX
 SG_ AHL663_3_2_HEADLAMP_HI_IND : 26|1@1+ (1,0) [0|1] ""  CAB
 SG_ AHL663_3_3_ADB_ACTIVE_IND : 27|1@1+ (1,0) [0|1] "" Vector__XXX
 SG_ AHL663_3_4_CSTM_SRH_OFF : 28|1@1+ (1,0) [0|1] "" Vector__XXX
 SG_ AHL663_2_0_FAIL_AHL : 16|3@1+ (1,0) [0|7] "" Vector__XXX
 SG_ AHL663_2_3_FAIL_LED_HEADLAMP : 19|2@1+ (1,0) [0|3] "" Vector__XXX
 SG_ AHL663_2_5_IND_AFS : 21|3@1+ (1,0) [0|7] "" Vector__XXX
 SG_ AHL663_1_0_MSG_COUNTER : 8|4@1+ (1,0) [0|15] ""  CAB
 SG_ AHL663_1_6 : 14|1@1+ (1,0) [0|1] "" Vector__XXX
 SG_ AHL663_0_0_CHECK_SUM : 0|8@1+ (1,0) [0|255] ""  CAB

BO_ 818 PMN332: 8 C_ECU_GW
 SG_ PMN332_7_0_RES_CONTROL_STATUS : 56|2@1+ (1,0) [0|3] "" Vector__XXX
 SG_ PMN332_7_2_REQ_RES_P_LOCK : 58|1@1+ (1,0) [0|1] "" Vector__XXX
 SG_ PMN332_7_5_IGB_RELAY_REQ : 61|1@1+ (1,0) [0|1] "" Vector__XXX
 SG_ PMN332_7_6_IGA_RELAY_REQ : 62|1@1+ (1,0) [0|1] "" Vector__XXX
 SG_ PMN332_7_7_REQ_STOP_RES : 63|1@1+ (1,0) [0|1] "" Vector__XXX
 SG_ PMN332_6_0_RES_IDLE_TIME : 48|7@1+ (10,0) [0|1270] "sec" Vector__XXX
 SG_ PMN332_6_7_CUST : 55|1@1+ (1,0) [0|1] "" Vector__XXX
 SG_ PMN332_5_0_PUSHSTART_SW : 40|1@1+ (1,0) [0|1] "" Vector__XXX
 SG_ PMN332_5_1_SIG_KEY_PUSHSTART : 41|1@1+ (1,0) [0|1] "" Vector__XXX
 SG_ PMN332_5_2_STATE_MODE_POWER : 42|2@1+ (1,0) [0|2] "" Vector__XXX
 SG_ PMN332_5_4_BUZ_2SHOT_IN : 44|1@1+ (1,0) [0|1] "" Vector__XXX
 SG_ PMN332_5_5_BUZ_INTERMIT1_IN : 45|1@1+ (1,0) [0|1] "" Vector__XXX
 SG_ PMN332_5_6_BUZ_INTERMIT2_IN : 46|1@1+ (1,0) [0|1] "" Vector__XXX
 SG_ PMN332_5_7_BUZ_CONTINUE_IN : 47|1@1+ (1,0) [0|1] "" Vector__XXX
 SG_ PMN332_2_0_WARN_SSP_SIG1 : 16|1@1+ (1,0) [0|1] "" Vector__XXX
 SG_ PMN332_2_1_WARN_SSP_SIG2 : 17|3@1+ (1,0) [0|4] "" Vector__XXX
 SG_ PMN332_2_4_SMT_PWR_SIG : 20|2@1+ (1,0) [0|2] "" Vector__XXX
 SG_ PMN332_2_7_BUZ_1SHOT_IN : 23|1@1+ (1,0) [0|1] "" Vector__XXX
 SG_ PMN332_1_0_MSG_COUNTER : 8|4@1+ (1,0) [0|15] "" Vector__XXX
 SG_ PMN332_0_0_CHECK_SUM : 0|8@1+ (1,0) [0|255] "" Vector__XXX

BO_ 1603 SMT643: 8 C_ECU_GW
 SG_ SMT643_2_0_DATA2 : 16|48@1+ (1,0) [0|281474976700000] "" Vector__XXX
 SG_ SMT643_1_0_MSG_COUNTER : 8|4@1+ (1,0) [0|15] "" Vector__XXX
 SG_ SMT643_1_4_DATA1 : 12|4@1+ (1,0) [0|15] "" Vector__XXX
 SG_ SMT643_0_0_CHECK_SUM : 0|8@1+ (1,0) [0|255] "" Vector__XXX

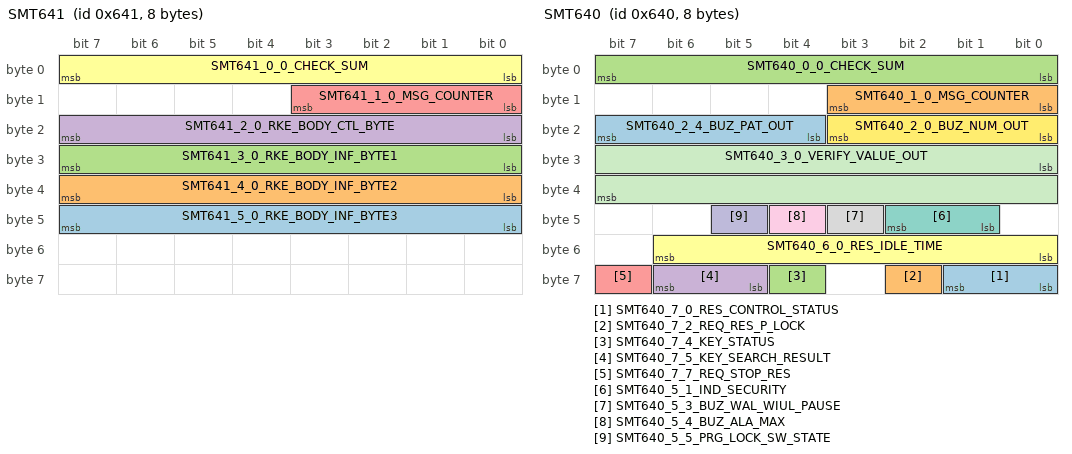
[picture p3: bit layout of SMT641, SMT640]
BO_ 1601 SMT641: 8 C_ECU_GW
 SG_ SMT641_5_0_RKE_BODY_INF_BYTE3 : 40|8@1+ (1,0) [0|255] ""  AIL
 SG_ SMT641_4_0_RKE_BODY_INF_BYTE2 : 32|8@1+ (1,0) [0|255] ""  AIL
 SG_ SMT641_3_0_RKE_BODY_INF_BYTE1 : 24|8@1+ (1,0) [0|255] ""  AIL
 SG_ SMT641_2_0_RKE_BODY_CTL_BYTE : 16|8@1+ (1,0) [0|255] ""  AIL
 SG_ SMT641_1_0_MSG_COUNTER : 8|4@1+ (1,0) [0|15] ""  AIL
 SG_ SMT641_0_0_CHECK_SUM : 0|8@1+ (1,0) [0|255] ""  AIL

BO_ 1600 SMT640: 8 C_ECU_GW
 SG_ SMT640_7_0_RES_CONTROL_STATUS : 56|2@1+ (1,0) [0|3] "" Vector__XXX
 SG_ SMT640_7_2_REQ_RES_P_LOCK : 58|1@1+ (1,0) [0|1] "" Vector__XXX
 SG_ SMT640_7_4_KEY_STATUS : 60|1@1+ (1,0) [0|1] "" Vector__XXX
 SG_ SMT640_7_5_KEY_SEARCH_RESULT : 61|2@1+ (1,0) [0|3] "" Vector__XXX
 SG_ SMT640_7_7_REQ_STOP_RES : 63|1@1+ (1,0) [0|1] "" Vector__XXX
 SG_ SMT640_6_0_RES_IDLE_TIME : 48|7@1+ (1,0) [0|1200] "sec" Vector__XXX
 SG_ SMT640_5_1_IND_SECURITY : 41|2@1+ (1,0) [0|3] "" Vector__XXX
 SG_ SMT640_5_3_BUZ_WAL_WIUL_PAUSE : 43|1@1+ (1,0) [0|1] "" Vector__XXX
 SG_ SMT640_5_4_BUZ_ALA_MAX : 44|1@1+ (1,0) [0|1] "" Vector__XXX
 SG_ SMT640_5_5_PRG_LOCK_SW_STATE : 45|1@1+ (1,0) [0|1] "" Vector__XXX
 SG_ SMT640_3_0_VERIFY_VALUE_OUT : 24|16@1+ (1,0) [0|65535] ""  AIL,CAB
 SG_ SMT640_2_0_BUZ_NUM_OUT : 16|4@1+ (1,0) [0|15] "" Vector__XXX
 SG_ SMT640_2_4_BUZ_PAT_OUT : 20|4@1+ (1,0) [0|15] "" Vector__XXX
 SG_ SMT640_1_0_MSG_COUNTER : 8|4@1+ (1,0) [0|15] ""  AIL
 SG_ SMT640_0_0_CHECK_SUM : 0|8@1+ (1,0) [0|255] ""  AIL

BO_ 816 SMT330: 8 C_ECU_GW
 SG_ SMT330_7_0 : 56|1@1+ (1,0) [0|1] "" Vector__XXX
 SG_ SMT330_7_1 : 57|1@1+ (1,0) [0|1] "" Vector__XXX
 SG_ SMT330_7_3_HF_CAPA_ERR_ST : 59|1@1+ (1,0) [0|1] "" Vector__XXX
 SG_ SMT330_7_6_HF_RESP_ERR_ST : 62|1@1+ (1,0) [0|1] "" Vector__XXX
 SG_ SMT330_6_0_REQ_MESS_PUSHSTART : 48|4@1+ (1,0) [0|8] "" Vector__XXX
 SG_ SMT330_6_4_WARN_SSP_SIG1 : 52|4@1+ (1,0) [0|14] "" Vector__XXX
 SG_ SMT330_5_1_WIUL_CUST : 41|1@1+ (1,0) [0|1] "" Vector__XXX
 SG_ SMT330_5_2_WAL_CUST : 42|1@1+ (1,0) [0|1] "" Vector__XXX
 SG_ SMT330_5_3_WARN_SSP_SIG2 : 43|2@1+ (1,0) [0|2] "" Vector__XXX
 SG_ SMT330_5_5_WARN_SSP_SIG3 : 45|3@1+ (1,0) [0|4] "" Vector__XXX
 SG_ SMT330_4_0_PUSHSTART_SW : 32|1@1+ (1,0) [0|1] "" Vector__XXX
 SG_ SMT330_4_1_SIG_KEY_PUSHSTART : 33|1@1+ (1,0) [0|1] "" Vector__XXX
 SG_ SMT330_4_2_HF_TOUCH_STATUS : 34|3@1+ (1,0) [0|7] "" Vector__XXX
 SG_ SMT330_4_5_HF_KICK_STATUS : 37|2@1+ (1,0) [0|17] "" Vector__XXX
 SG_ SMT330_3_0_BUZ_1SHOT_IN : 24|1@1+ (1,0) [0|1] "" Vector__XXX
 SG_ SMT330_3_1_BUZ_2SHOT_IN : 25|1@1+ (1,0) [0|1] "" Vector__XXX
 SG_ SMT330_3_2_BUZ_INTERMIT1_IN : 26|1@1+ (1,0) [0|1] "" Vector__XXX
 SG_ SMT330_3_3_BUZ_INTERMIT2_IN : 27|1@1+ (1,0) [0|1] "" Vector__XXX
 SG_ SMT330_3_4_BUZ_CONTINUE_IN : 28|1@1+ (1,0) [0|1] "" Vector__XXX
 SG_ SMT330_3_5_BUZ_TRPON_OK_IN : 29|1@1+ (1,0) [0|1] "" Vector__XXX
 SG_ SMT330_3_6_STATE_MODE_POWER : 30|2@1+ (1,0) [0|2] "" Vector__XXX
 SG_ SMT330_1_0_MSG_COUNTER : 8|4@1+ (1,0) [0|15] "" Vector__XXX
 SG_ SMT330_1_4_WAKE_UP_FRAME : 12|1@1+ (1,0) [0|1] "" Vector__XXX
 SG_ SMT330_1_5_REQ_COMM_CONT : 13|1@1+ (1,0) [0|1] "" Vector__XXX
 SG_ SMT330_1_6 : 14|1@1+ (1,0) [0|1] "" Vector__XXX
 SG_ SMT330_0_0_CHECK_SUM : 0|8@1+ (1,0) [0|255] "" Vector__XXX

BO_ 1622 BIU656: 8 C_ECU_GW
 SG_ BIU656_6_0_KICK_OPEN_REQ_PRG : 48|1@1+ (1,0) [0|1] "" Vector__XXX
 SG_ BIU656_6_1_KICK_CLOSE_REQ_PRG : 49|1@1+ (1,0) [0|1] "" Vector__XXX
 SG_ BIU656_6_6_CARGO_LAMP_OUT : 54|1@1+ (1,0) [0|1] "" Vector__XXX
 SG_ BIU656_6_7_PERMITT_KEY_RG_UNL : 55|1@1+ (1,0) [0|1] "" Vector__XXX
 SG_ BIU656_5_0_PRG_DRVR_OPENERSW : 40|1@1+ (1,0) [0|1] "" Vector__XXX
 SG_ BIU656_5_1_HF_PRG_OFF_SW : 41|1@1+ (1,0) [0|1] "" Vector__XXX
 SG_ BIU656_5_2_PERMIT_OPEN_RG : 42|1@1+ (1,0) [0|1] "" Vector__XXX
 SG_ BIU656_5_3_BUZ_ON_OFF : 43|1@1+ (1,0) [0|1] "" Vector__XXX
 SG_ BIU656_5_4_PRG_DRVR_SW_PERMIT : 44|1@1+ (1,0) [0|1] "" Vector__XXX
 SG_ BIU656_5_5_CSTM_HF_PRG_LOCK : 45|1@1+ (1,0) [0|1] "" Vector__XXX
 SG_ BIU656_5_6_CSTM_KICK_SENSOR : 46|1@1+ (1,0) [0|1] "" Vector__XXX
 SG_ BIU656_5_7_KICK_REQ_PRG : 47|1@1+ (1,0) [0|1] "" Vector__XXX
 SG_ BIU656_4_0_NOT_SMT_KEY_RG_SW : 32|2@1+ (1,0) [0|3] "" Vector__XXX
 SG_ BIU656_4_2_SMT_KEY_RG_SW : 34|2@1+ (1,0) [0|3] "" Vector__XXX
 SG_ BIU656_4_4_OPEN_RG_OPENER_SW : 36|2@1+ (1,0) [0|3] "" Vector__XXX
 SG_ BIU656_3_4_CHECKED_KEYNO : 28|3@1+ (1,0) [0|7] "" Vector__XXX
 SG_ BIU656_3_7_LOCKSTATUS_DRVR : 31|1@1+ (1,0) [0|1] ""  CAB
 SG_ BIU656_2_0_TRIG_LOCK_UNLOCK : 16|12@1+ (1,0) [0|4095] "" Vector__XXX
 SG_ BIU656_1_0_MSG_COUNTER : 8|4@1+ (1,0) [0|15] "" Vector__XXX
 SG_ BIU656_0_0_CHECK_SUM : 0|8@1+ (1,0) [0|255] "" Vector__XXX

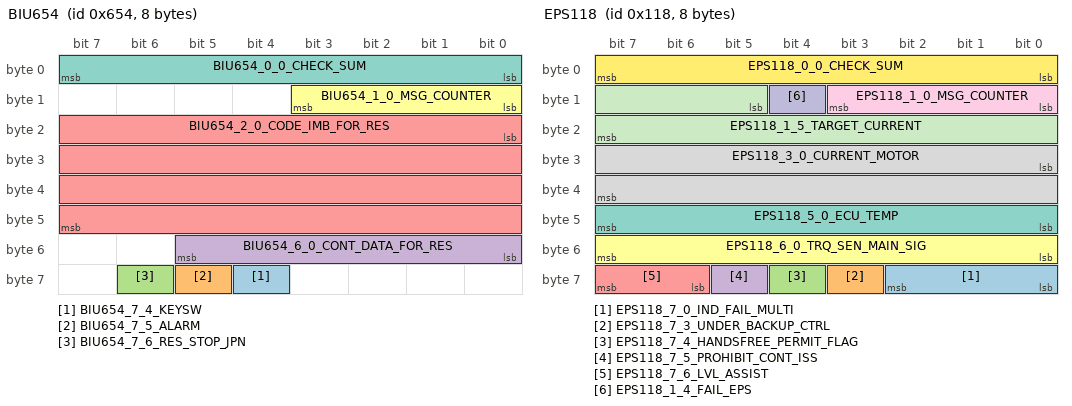
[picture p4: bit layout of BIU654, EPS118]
BO_ 1620 BIU654: 8 C_ECU_GW
 SG_ BIU654_7_4_KEYSW : 60|1@1+ (1,0) [0|1] "" Vector__XXX
 SG_ BIU654_7_5_ALARM : 61|1@1+ (1,0) [0|1] ""  AIL,CAB
 SG_ BIU654_7_6_RES_STOP_JPN : 62|1@1+ (1,0) [0|1] "" Vector__XXX
 SG_ BIU654_6_0_CONT_DATA_FOR_RES : 48|6@1+ (1,0) [0|63] "" Vector__XXX
 SG_ BIU654_2_0_CODE_IMB_FOR_RES : 16|32@1+ (1,0) [0|4294967295] "" Vector__XXX
 SG_ BIU654_1_0_MSG_COUNTER : 8|4@1+ (1,0) [0|15] ""  AIL
 SG_ BIU654_0_0_CHECK_SUM : 0|8@1+ (1,0) [0|255] ""  AIL

BO_ 1618 BIU652: 8 C_ECU_GW
 SG_ BIU652_7_0_IND_SECURITY_IMB : 56|8@1+ (1,0) [0|240] ""  AIL
 SG_ BIU652_6_0_OCCUPATION_3RDRH : 48|1@1+ (1,0) [0|1] ""  CAB
 SG_ BIU652_6_1_OCCUPATION_3RDCTR : 49|1@1+ (1,0) [0|1] ""  CAB
 SG_ BIU652_6_2_OCCUPATION_3RDLH : 50|1@1+ (1,0) [0|1] ""  CAB
 SG_ BIU652_6_3_OCCUPATION_RRRH : 51|1@1+ (1,0) [0|1] ""  CAB
 SG_ BIU652_6_4_OCCUPATION_RRCTR : 52|1@1+ (1,0) [0|1] ""  CAB
 SG_ BIU652_6_5_OCCUPATION_RRLH : 53|1@1+ (1,0) [0|1] ""  CAB
 SG_ BIU652_6_6_HORNHAZARD_RES_SIG : 54|1@1+ (1,0) [0|1] "" Vector__XXX
 SG_ BIU652_6_7_OCCUPATION_DRVR : 55|1@1+ (1,0) [0|1] ""  CAB
 SG_ BIU652_5_0_STATUS_ROOMLAMP : 40|3@1+ (1,0) [0|7] "" Vector__XXX
 SG_ BIU652_5_3_HEADLAMP_SMALL : 43|1@1+ (1,0) [0|1] "" Vector__XXX
 SG_ BIU652_5_4_ALL_UNLOCK_STATE : 44|1@1+ (1,0) [0|1] "" Vector__XXX
 SG_ BIU652_5_5_DRVR_UNLOCK_STATE : 45|1@1+ (1,0) [0|1] "" Vector__XXX
 SG_ BIU652_5_6_ALL_LOCK_STATE : 46|1@1+ (1,0) [0|1] "" Vector__XXX
 SG_ BIU652_4_0_TRIG_LOCK_UNLOCK : 32|8@1+ (1,0) [0|255] "" Vector__XXX
 SG_ BIU652_3_0_DOOR_DRVR : 24|1@1+ (1,0) [0|1] ""  AIL,CAB
 SG_ BIU652_3_1_DOOR_PASS : 25|1@1+ (1,0) [0|1] ""  AIL,CAB
 SG_ BIU652_3_2_DOOR_RRRH : 26|1@1+ (1,0) [0|1] ""  AIL,CAB
 SG_ BIU652_3_3_DOOR_RRLH : 27|1@1+ (1,0) [0|1] ""  AIL,CAB
 SG_ BIU652_3_4_DOOR_RG : 28|1@1+ (1,0) [0|1] ""  AIL,CAB
 SG_ BIU652_3_5_DOOR_TR : 29|1@1+ (1,0) [0|1] "" Vector__XXX
 SG_ BIU652_3_7_OPENSW_RG : 31|1@1+ (1,0) [0|1] "" Vector__XXX
 SG_ BIU652_2_0_LOCKSTATUS_DRVR : 16|1@1+ (1,0) [0|1] ""  AIL,CAB
 SG_ BIU652_2_1_LOCKSTATUS_PASS : 17|1@1+ (1,0) [0|1] ""  AIL,CAB
 SG_ BIU652_2_2_LOCKSTATUS_RRRH : 18|1@1+ (1,0) [0|1] ""  AIL,CAB
 SG_ BIU652_2_3_LOCKSTATUS_RRLH : 19|1@1+ (1,0) [0|1] ""  AIL,CAB
 SG_ BIU652_2_4_LOCKSTATUS_RG : 20|1@1+ (1,0) [0|1] ""  AIL,CAB
 SG_ BIU652_2_6_UNLOCK_DOORKEYSW : 22|1@1+ (1,0) [0|1] "" Vector__XXX
 SG_ BIU652_2_7_LOCK_DOORKEYSW : 23|1@1+ (1,0) [0|1] "" Vector__XXX
 SG_ BIU652_1_0_MSG_COUNTER : 8|4@1+ (1,0) [0|15] ""  AIL
 SG_ BIU652_0_0_CHECK_SUM : 0|8@1+ (1,0) [0|255] "" Vector__XXX

BO_ 1617 BIU651: 8 C_ECU_GW
 SG_ BIU651_7_0_PWPOS_RL : 56|2@1+ (1,0) [0|3] "" Vector__XXX
 SG_ BIU651_7_2_PWPOS_RR : 58|2@1+ (1,0) [0|3] "" Vector__XXX
 SG_ BIU651_7_4_PWPOS_PASS : 60|2@1+ (1,0) [0|3] "" Vector__XXX
 SG_ BIU651_7_6_PWPOS_DRVR : 62|2@1+ (1,0) [0|3] "" Vector__XXX
 SG_ BIU651_6_0_IND_ACTIVE_HBA : 48|2@1+ (1,0) [0|3] "" Vector__XXX
 SG_ BIU651_6_2_ADB_ACTIVE : 50|1@1+ (1,0) [0|1] "" Vector__XXX
 SG_ BIU651_6_3_JUDGE_ILL : 51|1@1+ (1,0) [0|1] "" Vector__XXX
 SG_ BIU651_6_4_TYPE_LO_BEAM : 52|2@1+ (1,0) [0|3] "" Vector__XXX
 SG_ BIU651_6_6_TYPE_HI_BEAM : 54|2@1+ (1,0) [0|3] "" Vector__XXX
 SG_ BIU651_5_0_SRF_ACTIVE : 40|1@1+ (1,0) [0|1] "" Vector__XXX
 SG_ BIU651_5_1_SRF_IND : 41|2@1+ (1,0) [0|3] "" Vector__XXX
 SG_ BIU651_5_3_SRF_LAMP_LIGHT : 43|1@1+ (1,0) [0|1] "" Vector__XXX
 SG_ BIU651_5_4_SRF_LAMP_LEFT : 44|1@1+ (1,0) [0|1] "" Vector__XXX
 SG_ BIU651_5_5_MSG_STATUS_HBA : 45|2@1+ (1,0) [0|3] "" Vector__XXX
 SG_ BIU651_5_7_IND_FAIL_HBA : 47|1@1+ (1,0) [0|1] "" Vector__XXX
 SG_ BIU651_4_0_BUZ_PATTERN : 32|4@1+ (1,0) [0|8] "" Vector__XXX
 SG_ BIU651_4_4_CSTM_OPE_ALARM : 36|2@1+ (1,0) [0|3] "" Vector__XXX
 SG_ BIU651_4_6_CSTM_HBA : 38|2@1+ (1,0) [0|3] "" Vector__XXX
 SG_ BIU651_3_0_HEADLAMP_PASS_SW : 24|1@1+ (1,0) [0|1] "" Vector__XXX
 SG_ BIU651_3_1_HEADLAMP_AUTO_SW : 25|1@1+ (1,0) [0|1] "" Vector__XXX
 SG_ BIU651_3_2_JUDGE_DOOR_LOCK : 26|1@1+ (1,0) [0|1] "" Vector__XXX
 SG_ BIU651_3_3_JUDGE_DOOR_UNLOCK : 27|1@1+ (1,0) [0|1] ""  CAB
 SG_ BIU651_3_4_HEADLAMP_Lo_SW : 28|1@1+ (1,0) [0|1] "" Vector__XXX
 SG_ BIU651_3_5_HEADLAMP_HI_SW : 29|1@1+ (1,0) [0|1] "" Vector__XXX
 SG_ BIU651_3_6_WIPER_AUTO_SW : 30|1@1+ (1,0) [0|1] "" Vector__XXX
 SG_ BIU651_3_7_PRG_LIN_MEMORY_ON_OFF : 31|1@1+ (1,0) [0|1] "" Vector__XXX
 SG_ BIU651_2_0_CSTM_ILLUMI_SSR : 16|1@1+ (1,0) [0|1] "" Vector__XXX
 SG_ BIU651_2_1_HANDLE : 17|1@1+ (1,0) [0|1] "" Vector__XXX
 SG_ BIU651_2_2_CSTM_SMT : 18|1@1+ (1,0) [0|1] "" Vector__XXX
 SG_ BIU651_2_3_AJARDOOR_STATUS : 19|1@1+ (1,0) [0|1] "" Vector__XXX
 SG_ BIU651_2_4_ONETOUCH_LAMP_OUT : 20|1@1+ (1,0) [0|1] "" Vector__XXX
 SG_ BIU651_2_5_PRG_FAIL_FLAG : 21|1@1+ (1,0) [0|1] "" Vector__XXX
 SG_ BIU651_2_6_CSTM_PSMECU : 22|1@1+ (1,0) [0|1] "" Vector__XXX
 SG_ BIU651_2_7_STATE_REGIST_DEL : 23|1@1+ (1,0) [0|1] "" Vector__XXX
 SG_ BIU651_1_0_MSG_COUNTER : 8|4@1+ (1,0) [0|15] "" Vector__XXX
 SG_ BIU651_1_4_SRPOS : 12|3@1+ (1,0) [0|7] "" Vector__XXX
 SG_ BIU651_1_7_WIPER_INT_STATUS : 15|1@1+ (1,0) [0|1] "" Vector__XXX
 SG_ BIU651_0_0_CHECK_SUM : 0|8@1+ (1,0) [0|255] "" Vector__XXX

BO_ 940 BIU3AC: 8 C_ECU_GW
 SG_ BIU3AC_7_0_HEADLAMP_SMALL : 56|1@1+ (1,0) [0|1] ""  CAB
 SG_ BIU3AC_7_1_HEADLAMP_LO_REQ : 57|1@1+ (1,0) [0|1] "" Vector__XXX
 SG_ BIU3AC_7_2_HEADLAMP_HI_REQ : 58|1@1+ (1,0) [0|1] "" Vector__XXX
 SG_ BIU3AC_7_3_FT_FOG_RELAY_REQ : 59|1@1+ (1,0) [0|1] "" Vector__XXX
 SG_ BIU3AC_7_4_FOGLAMP_RR : 60|1@1+ (1,0) [0|1] "" Vector__XXX
 SG_ BIU3AC_7_5_DRL : 61|1@1+ (1,0) [0|1] "" Vector__XXX
 SG_ BIU3AC_7_6_WIPER_FRONT : 62|1@1+ (1,0) [0|1] ""  CAB
 SG_ BIU3AC_7_7_RDEF_RELAY_REQ : 63|1@1+ (1,0) [0|1] "" Vector__XXX
 SG_ BIU3AC_6_0_RDEFOGSW : 48|1@1+ (1,0) [0|1] "" Vector__XXX
 SG_ BIU3AC_6_1_CSTM_PRG : 49|1@1+ (1,0) [0|1] "" Vector__XXX
 SG_ BIU3AC_6_2_FAIL_SHIFTLOCKSOL : 50|1@1+ (1,0) [0|1] "" Vector__XXX
 SG_ BIU3AC_6_3_REQ_CANCEL_ISS : 51|1@1+ (1,0) [0|1] "" Vector__XXX
 SG_ BIU3AC_6_4_REVERSE_MT : 52|1@1+ (1,0) [0|1] ""  AIL,CAB
 SG_ BIU3AC_6_5_HANDBRAKE : 53|1@1+ (1,0) [0|1] ""  AIL,CAB
 SG_ BIU3AC_6_6_BRAKELAMPSW : 54|1@1+ (1,0) [0|1] ""  AIL,CAB
 SG_ BIU3AC_6_7_TOWING_SW : 55|1@1+ (1,0) [0|1] "" Vector__XXX
 SG_ BIU3AC_5_0_LANE_OFF_SW : 40|2@1+ (1,0) [0|3] "" Vector__XXX
 SG_ BIU3AC_5_2_PCR_OFF_SW : 42|2@1+ (1,0) [0|3] "" Vector__XXX
 SG_ BIU3AC_5_4_DIMMER_CANCEL : 44|1@1+ (1,0) [0|1] ""  AIL,CAB
 SG_ BIU3AC_5_5_KEYSW : 45|1@1+ (1,0) [0|1] "" Vector__XXX
 SG_ BIU3AC_5_6_IND_ND_SHIFTLOCK : 46|1@1+ (1,0) [0|1] "" Vector__XXX
 SG_ BIU3AC_4_0_DOOR_DRVR : 32|1@1+ (1,0) [0|1] ""  AIL,CAB
 SG_ BIU3AC_4_1_DOOR_PASS : 33|1@1+ (1,0) [0|1] ""  AIL,CAB
 SG_ BIU3AC_4_2_DOOR_RRRH : 34|1@1+ (1,0) [0|1] ""  AIL,CAB
 SG_ BIU3AC_4_3_DOOR_RRLH : 35|1@1+ (1,0) [0|1] ""  AIL,CAB
 SG_ BIU3AC_4_4_DOOR_RG : 36|1@1+ (1,0) [0|1] ""  AIL,CAB
 SG_ BIU3AC_4_5_DOOR_TR : 37|1@1+ (1,0) [0|1] ""  AIL,CAB
 SG_ BIU3AC_4_6_HOOD_CLOSE : 38|1@1+ (1,0) [0|1] ""  CAB
 SG_ BIU3AC_4_7_HOOD_OPEN : 39|1@1+ (1,0) [0|1] ""  CAB
 SG_ BIU3AC_3_0_GW_STSW_RES : 24|1@1+ (1,0) [0|1] "" Vector__XXX
 SG_ BIU3AC_3_1_GW_POWER_RES : 25|2@1+ (1,0) [0|2] "" Vector__XXX
 SG_ BIU3AC_3_3_ST1 : 27|1@1+ (1,0) [0|1] "" Vector__XXX
 SG_ BIU3AC_3_4_ST2 : 28|1@1+ (1,0) [0|1] "" Vector__XXX
 SG_ BIU3AC_3_5_ACC : 29|1@1+ (1,0) [0|1] ""  CAB
 SG_ BIU3AC_3_6_IGA : 30|1@1+ (1,0) [0|1] ""  AIL,CAB
 SG_ BIU3AC_3_7_BAT_BACKUP : 31|1@1+ (1,0) [0|1] ""  AIL,CAB
 SG_ BIU3AC_2_0_CSTM_AC : 16|1@1+ (1,0) [0|1] "" Vector__XXX
 SG_ BIU3AC_2_1_IMB_SMT : 17|2@1+ (1,0) [0|3] "" Vector__XXX
 SG_ BIU3AC_2_3_CSTM_WGN_SDN : 19|1@1+ (1,0) [0|1] ""  CAB
 SG_ BIU3AC_2_4_VAL_SEAT_BACK_CTSM : 20|1@1+ (1,0) [0|1] "" Vector__XXX
 SG_ BIU3AC_2_5_VAL_MIR_AFOLD_CTSM : 21|1@1+ (1,0) [0|1] "" Vector__XXX
 SG_ BIU3AC_2_6_VAL_MIR_RTILT_CTSM : 22|1@1+ (1,0) [0|1] "" Vector__XXX
 SG_ BIU3AC_2_7_WIPER_REAR : 23|1@1+ (1,0) [0|1] "" Vector__XXX
 SG_ BIU3AC_1_0_MSG_COUNTER : 8|4@1+ (1,0) [0|15] ""  AIL,CAB
 SG_ BIU3AC_1_4_PADDLESHIFT_DOWN_SW : 12|1@1+ (1,0) [0|1] "" Vector__XXX
 SG_ BIU3AC_1_5_PADDLESHIFT_UP_SW : 13|1@1+ (1,0) [0|1] "" Vector__XXX
 SG_ BIU3AC_1_6_MANUALMODE_SW : 14|1@1+ (1,0) [0|1] "" Vector__XXX
 SG_ BIU3AC_0_0_CHECK_SUM : 0|8@1+ (1,0) [0|255] ""  AIL,CAB

BO_ 1616 BIU650: 8 C_ECU_GW
 SG_ BIU650_7_0_Reserved : 56|1@1+ (1,0) [0|1] "" Vector__XXX
 SG_ BIU650_7_1_Reserved : 57|1@1+ (1,0) [0|1] "" Vector__XXX
 SG_ BIU650_7_2_Reserved : 58|1@1+ (1,0) [0|1] "" Vector__XXX
 SG_ BIU650_7_3_DOOR_LINK_SW_STS : 59|1@1+ (1,0) [0|1] "" Vector__XXX
 SG_ BIU650_7_4_Reserved : 60|1@1+ (1,0) [0|1] "" Vector__XXX
 SG_ BIU650_6_0_Reserved : 48|3@1+ (1,0) [0|7] "" Vector__XXX
 SG_ BIU650_6_3_RR_WIPER_STATUS : 51|2@1+ (1,0) [0|3] "" Vector__XXX
 SG_ BIU650_6_5_WIPER_SENSITIVITY_CTM : 53|2@1+ (1,0) [0|3] "" Vector__XXX
 SG_ BIU650_5_0_Reserved : 40|1@1+ (1,0) [0|1] ""  AIL,CAB
 SG_ BIU650_5_1_Reserved : 41|1@1+ (1,0) [0|1] "" Vector__XXX
 SG_ BIU650_5_2_FMH_DOOR_LOCK : 42|2@1+ (1,0) [0|3] ""  AIL,CAB
 SG_ BIU650_5_4_LMH_DOOR_LOCK : 44|2@1+ (1,0) [0|3] "" Vector__XXX
 SG_ BIU650_4_0_REQ_OPE_AUTOLIGHT : 32|2@1+ (1,0) [0|3] "" Vector__XXX
 SG_ BIU650_4_2_STATE_SHINSSR : 34|2@1+ (1,0) [0|3] "" Vector__XXX
 SG_ BIU650_4_4_STATE_RLS_FAIL : 36|2@1+ (1,0) [0|3] "" Vector__XXX
 SG_ BIU650_3_0_REQ_FWASHER_ITLOCK : 24|1@1+ (1,0) [0|1] "" Vector__XXX
 SG_ BIU650_3_1_FWIPER_RTN : 25|1@1+ (1,0) [0|1] "" Vector__XXX
 SG_ BIU650_3_2_TURN_LAMP_STATE_LEFT : 26|1@1+ (1,0) [0|1] "" Vector__XXX
 SG_ BIU650_3_3_TURN_LAMP_STATE_RIGHT : 27|1@1+ (1,0) [0|1] "" Vector__XXX
 SG_ BIU650_3_4_Reserved : 28|1@1+ (1,0) [0|1] "" Vector__XXX
 SG_ BIU650_2_0_HEADLAMP_SMALL_SW : 16|1@1+ (1,0) [0|1] "" Vector__XXX
 SG_ BIU650_2_1_HEADLAMP_LO_SW : 17|1@1+ (1,0) [0|1] "" Vector__XXX
 SG_ BIU650_2_2_HEADLAMP_OFF_SW : 18|1@1+ (1,0) [0|1] "" Vector__XXX
 SG_ BIU650_2_3_HEADLAMP_Hi_SW : 19|1@1+ (1,0) [0|1] "" Vector__XXX
 SG_ BIU650_2_4_HEAD_LAMP_PASS_SW : 20|1@1+ (1,0) [0|1] "" Vector__XXX
 SG_ BIU650_2_5_FFOG_SW : 21|1@1+ (1,0) [0|1] "" Vector__XXX
 SG_ BIU650_2_6_RFOG_SW : 22|1@1+ (1,0) [0|1] "" Vector__XXX
 SG_ BIU650_1_0_MSG_COUNTER : 8|4@1+ (1,0) [0|15] ""  AIL
 SG_ BIU650_0_0_CHECK_SUM : 0|8@1+ (1,0) [0|255] ""  AIL

BO_ 280 EPS118: 8 C_ECU_GW
 SG_ EPS118_7_0_IND_FAIL_MULTI : 56|3@1+ (1,0) [0|6] "" Vector__XXX
 SG_ EPS118_7_3_UNDER_BACKUP_CTRL : 59|1@1+ (1,0) [0|1] "" Vector__XXX
 SG_ EPS118_7_4_HANDSFREE_PERMIT_FLAG : 60|1@1+ (1,0) [0|1] ""  CAB
 SG_ EPS118_7_5_PROHIBIT_CONT_ISS : 61|1@1+ (1,0) [0|1] "" Vector__XXX
 SG_ EPS118_7_6_LVL_ASSIST : 62|2@1+ (1,0) [0|2] "" Vector__XXX
 SG_ EPS118_6_0_TRQ_SEN_MAIN_SIG : 48|8@1- (0.0732,0) [-9.3696|9.2964] "Nm" Vector__XXX
 SG_ EPS118_5_0_ECU_TEMP : 40|8@1+ (1,-40) [-40|215] "℃" Vector__XXX
 SG_ EPS118_3_0_CURRENT_MOTOR : 24|16@1+ (0.1,0) [0|6553.5] "A" Vector__XXX
 SG_ EPS118_1_0_MSG_COUNTER : 8|4@1+ (1,0) [0|15] "" Vector__XXX
 SG_ EPS118_1_4_FAIL_EPS : 12|1@1+ (1,0) [0|1] "" Vector__XXX
 SG_ EPS118_1_5_TARGET_CURRENT : 13|11@1- (0.1,0) [-102.4|102.3] "Arms" Vector__XXX
 SG_ EPS118_0_0_CHECK_SUM : 0|8@1+ (1,0) [0|255] "" Vector__XXX

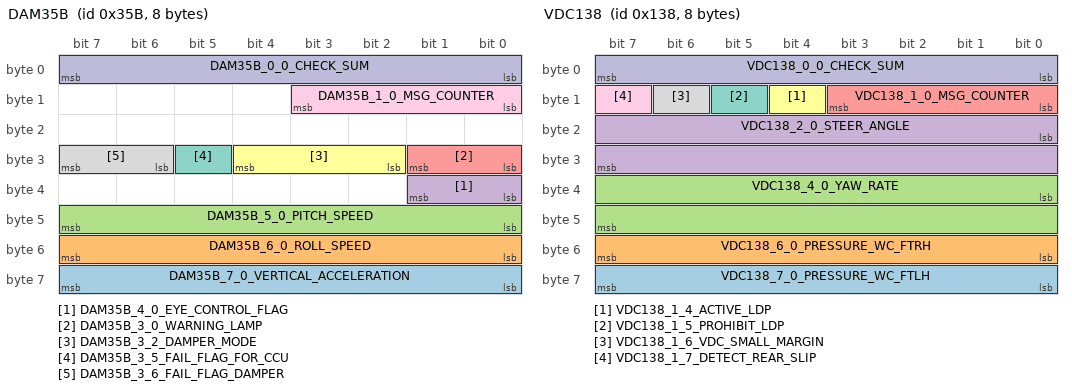
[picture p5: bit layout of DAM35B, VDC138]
BO_ 859 DAM35B: 8 C_ECU_GW
 SG_ DAM35B_7_0_VERTICAL_ACCELERATION : 56|8@1- (0.05,0) [-6.4|6.35] "m/s2" Vector__XXX
 SG_ DAM35B_6_0_ROLL_SPEED : 48|8@1- (0.15,0) [-19.2|19.05] "deg/s" Vector__XXX
 SG_ DAM35B_5_0_PITCH_SPEED : 40|8@1- (0.3,0) [-38.4|38.1] "deg/s" Vector__XXX
 SG_ DAM35B_4_0_EYE_CONTROL_FLAG : 32|2@1+ (1,0) [0|3] "" Vector__XXX
 SG_ DAM35B_3_0_WARNING_LAMP : 24|2@1+ (1,0) [0|3] "" Vector__XXX
 SG_ DAM35B_3_2_DAMPER_MODE : 26|3@1+ (1,0) [0|7] ""  CAB
 SG_ DAM35B_3_5_FAIL_FLAG_FOR_CCU : 29|1@1+ (1,0) [0|1] "" Vector__XXX
 SG_ DAM35B_3_6_FAIL_FLAG_DAMPER : 30|2@1+ (1,0) [0|3] "" Vector__XXX
 SG_ DAM35B_1_0_MSG_COUNTER : 8|4@1+ (1,0) [0|15] "" Vector__XXX
 SG_ DAM35B_0_0_CHECK_SUM : 0|8@1+ (1,0) [0|255] "" Vector__XXX

BO_ 811 EPB32B: 8 C_ECU_GW
 SG_ EPB32B_7_0_AVH_TARGET_PRESS : 56|8@1+ (0.0235,0) [0|255] "MPa" Vector__XXX
 SG_ EPB32B_6_0_VEHICLE_RUN_STOP_FLG : 48|2@1+ (1,0) [0|3] "" Vector__XXX
 SG_ EPB32B_6_2_REQ_HILL_P_CAUTION : 50|1@1+ (1,0) [0|1] "" Vector__XXX
 SG_ EPB32B_5_0_FLG_AVH_OILPRES_EPB : 40|1@1+ (1,0) [0|1] "" Vector__XXX
 SG_ EPB32B_5_1_FLG_AVH : 41|1@1+ (1,0) [0|1] "" Vector__XXX
 SG_ EPB32B_5_2_AVH_INTENSIFY_PRES : 42|1@1+ (1,0) [0|1] "" Vector__XXX
 SG_ EPB32B_5_3_BREAK_IND : 43|2@1+ (1,0) [0|3] "" Vector__XXX
 SG_ EPB32B_5_5_AVH_ON_LAMP : 45|1@1+ (1,0) [0|1] "" Vector__XXX
 SG_ EPB32B_5_6_AVH_FUNC_ON_LUMP : 46|1@1+ (1,0) [0|1] "" Vector__XXX
 SG_ EPB32B_5_7_AVH_ACTIVE : 47|1@1+ (1,0) [0|1] "" Vector__XXX
 SG_ EPB32B_4_0_BUZZER : 32|2@1+ (1,0) [0|3] "" Vector__XXX
 SG_ EPB32B_4_2_HILL_HOLD_ON_LAMP : 34|1@1+ (1,0) [0|1] "" Vector__XXX
 SG_ EPB32B_4_3_CLAMP_LAMP : 35|2@1+ (1,0) [0|3] "" Vector__XXX
 SG_ EPB32B_4_5_WARN_LAMP : 37|2@1+ (1,0) [0|3] "" Vector__XXX
 SG_ EPB32B_4_7_WARN_EPB_MET_LCD : 39|1@1+ (1,0) [0|1] "" Vector__XXX
 SG_ EPB32B_3_0_STATUS_EPB : 24|3@1+ (1,0) [0|7] ""  AIL,CAB
 SG_ EPB32B_3_3_DYNAMIC_PARKING : 27|1@1+ (1,0) [0|1] "" Vector__XXX
 SG_ EPB32B_3_4_HILL_HOLD_RUN_FLG : 28|1@1+ (1,0) [0|1] "" Vector__XXX
 SG_ EPB32B_3_5_INHIBIT_ISS_DELAY : 29|1@1+ (1,0) [0|1] "" Vector__XXX
 SG_ EPB32B_3_6_INHIBIT_ISS : 30|1@1+ (1,0) [0|1] "" Vector__XXX
 SG_ EPB32B_3_7_AVH_PERMIT_CONT_ACC : 31|1@1+ (1,0) [0|1] "" Vector__XXX
 SG_ EPB32B_2_0_ERR_INFO : 16|2@1+ (1,0) [0|3] "" Vector__XXX
 SG_ EPB32B_2_2_EPB_FAIL_FLG1 : 18|1@1+ (1,0) [0|1] "" Vector__XXX
 SG_ EPB32B_2_3_EPB_FAIL_FLG2 : 19|1@1+ (1,0) [0|1] "" Vector__XXX
 SG_ EPB32B_2_4_EPB_FAIL_FLG3 : 20|1@1+ (1,0) [0|1] "" Vector__XXX
 SG_ EPB32B_1_0_MSG_COUNTER : 8|4@1+ (1,0) [0|15] ""  AIL,CAB
 SG_ EPB32B_1_4_WAKE_UP_FRAME : 12|1@1+ (1,0) [0|1] "" Vector__XXX
 SG_ EPB32B_1_5_REQ_COMM_CONT : 13|1@1+ (1,0) [0|1] "" Vector__XXX
 SG_ EPB32B_1_6 : 14|1@1+ (1,0) [0|1] "" Vector__XXX
 SG_ EPB32B_0_0_CHECK_SUM : 0|8@1+ (1,0) [0|255] ""  AIL,CAB

BO_ 313 VDC139: 8 C_ECU_GW
 SG_ VDC139_7_4_FAIL_PRESSURE_SSR : 60|1@1+ (1,0) [0|1] "" Vector__XXX
 SG_ VDC139_7_5_STATUS_EPB : 61|3@1+ (1,0) [0|7] "" Vector__XXX
 SG_ VDC139_6_0_SSR_N_PRESS : 48|12@1+ (1,0) [193|3896] "" Vector__XXX
 SG_ VDC139_5_0_PRESSURE_BRAKE : 40|8@1+ (0.13058823529412,0) [0|25] "MPa"  CAB
 SG_ VDC139_4_0_HDC_STATUS : 32|2@1+ (1,0) [0|3] "" Vector__XXX
 SG_ VDC139_4_2_BRAKELAMPSW : 34|1@1+ (1,0) [0|1] "" Vector__XXX
 SG_ VDC139_4_3_FAIL_BRAKELAMPSW : 35|1@1+ (1,0) [0|1] "" Vector__XXX
 SG_ VDC139_4_4_ACTIVATE_ABS : 36|1@1+ (1,0) [0|1] ""  CAB
 SG_ VDC139_4_5_ACTIVATE_TCS : 37|1@1+ (1,0) [0|1] ""  CAB
 SG_ VDC139_4_6_CONT_OVER_STR : 38|1@1+ (1,0) [0|1] "" Vector__XXX
 SG_ VDC139_4_7_CONT_UNDER_STR : 39|1@1+ (1,0) [0|1] "" Vector__XXX
 SG_ VDC139_3_5_FAIL_VDC_SSR : 29|1@1+ (1,0) [0|1] "" Vector__XXX
 SG_ VDC139_3_6_FAIL_SPD_SSR_FHI : 30|1@1+ (1,0) [0|1] "" Vector__XXX
 SG_ VDC139_3_7_FAIL_ABS_SYS : 31|1@1+ (1,0) [0|1] "" Vector__XXX
 SG_ VDC139_2_0_SPD_WHEEL_AVE : 16|13@1+ (0.05625,0) [0|299.98125] "km/h"  AIL,CAB
 SG_ VDC139_1_0_MSG_COUNTER : 8|4@1+ (1,0) [0|15] ""  AIL,CAB
 SG_ VDC139_1_4_FAIL_HDC_SYS : 12|1@1+ (1,0) [0|1] "" Vector__XXX
 SG_ VDC139_1_5_VEHICLE_HIGHT : 13|2@1+ (1,0) [0|2] "" Vector__XXX
 SG_ VDC139_1_7_REPROGRAMING : 15|1@1+ (1,0) [0|1] ""  CAB
 SG_ VDC139_0_0_CHECK_SUM : 0|8@1+ (1,0) [0|255] ""  AIL,CAB

BO_ 312 VDC138: 8 C_ECU_GW
 SG_ VDC138_7_0_PRESSURE_WC_FTLH : 56|8@1+ (0.08,0) [0|20.4] "MPa" Vector__XXX
 SG_ VDC138_6_0_PRESSURE_WC_FTRH : 48|8@1+ (0.08,0) [0|20.4] "MPa" Vector__XXX
 SG_ VDC138_4_0_YAW_RATE : 32|16@1- (0.0047358121330724,0) [-1.571|1.571] "rad/s"  CAB
 SG_ VDC138_2_0_STEER_ANGLE : 16|16@1- (0.1,0) [-719.9|719.9] "deg"  CAB
 SG_ VDC138_1_0_MSG_COUNTER : 8|4@1+ (1,0) [0|15] ""  CAB
 SG_ VDC138_1_4_ACTIVE_LDP : 12|1@1+ (1,0) [0|1] "" Vector__XXX
 SG_ VDC138_1_5_PROHIBIT_LDP : 13|1@1+ (1,0) [0|1] "" Vector__XXX
 SG_ VDC138_1_6_VDC_SMALL_MARGIN : 14|1@1+ (1,0) [0|1] "" Vector__XXX
 SG_ VDC138_1_7_DETECT_REAR_SLIP : 15|1@1+ (1,0) [0|1] "" Vector__XXX
 SG_ VDC138_0_0_CHECK_SUM : 0|8@1+ (1,0) [0|255] ""  CAB

BO_ 1712 CCU6B0: 8 C_ECU_GW
 SG_ CCU6B0_7_0_AIL_CSTM_PRS_REQ : 56|1@1+ (1,0) [0|1] ""  AIL
 SG_ CCU6B0_7_1_AIL_RENDER_REQ : 57|3@1+ (1,0) [0|5] ""  AIL
 SG_ CCU6B0_6_0_AIL_FIRST_BRIGHT_REQ : 48|4@1+ (1,0) [0|9] ""  AIL
 SG_ CCU6B0_6_4_AIL_SECOND_BRIGHT_REQ : 52|4@1+ (1,0) [0|15] ""  AIL
 SG_ CCU6B0_5_0_AIL_SECOND_COLOR_REQ : 40|6@1+ (1,0) [0|63] ""  AIL
 SG_ CCU6B0_4_0_AIL_FIRST_COLOR_REQ : 32|6@1+ (1,0) [0|63] ""  AIL
 SG_ CCU6B0_3_0_AIL_ADAS_VEH_DIS_REQ : 24|1@1+ (1,0) [0|1] ""  AIL
 SG_ CCU6B0_3_1_AIL_ADAS_LANE_DEV_REQ : 25|1@1+ (1,0) [0|1] ""  AIL
 SG_ CCU6B0_3_2_AIL_ADAS_FT_CROSS_REQ : 26|1@1+ (1,0) [0|1] ""  AIL
 SG_ CCU6B0_3_3_AIL_ADAS_HANDS_FR_REQ : 27|1@1+ (1,0) [0|1] ""  AIL
 SG_ CCU6B0_2_0_AIL_WEL_FOL_REQ : 16|1@1+ (1,0) [0|1] ""  AIL
 SG_ CCU6B0_2_1_AIL_ADAS_EXP_REQ : 17|1@1+ (1,0) [0|1] ""  AIL
 SG_ CCU6B0_2_2_AIL_NOTIFI_EXP_REQ : 18|1@1+ (1,0) [0|1] ""  AIL
 SG_ CCU6B0_2_3_AIL_AIR_CON_EXP_REQ : 19|1@1+ (1,0) [0|1] ""  AIL
 SG_ CCU6B0_1_0_MSG_COUNTER : 8|4@1+ (1,0) [0|15] ""  AIL
 SG_ CCU6B0_1_4_AIL_CUSTOM_REQ : 12|1@1+ (1,0) [0|1] ""  AIL
 SG_ CCU6B0_1_5_AIL_CUSTOM_RESET_REQ : 13|1@1+ (1,0) [0|1] ""  AIL
 SG_ CCU6B0_1_6_AIL_ON_OFF_REQ : 14|1@1+ (1,0) [0|1] ""  AIL
 SG_ CCU6B0_0_0_CHECK_SUM : 0|8@1+ (1,0) [0|255] ""  AIL

BO_ 1665 CECU681: 8 C_ECU
 SG_ CECU681_6_7_DP_CHANGE_SET_REQ : 55|1@1+ (1,0) [0|1] "" Vector__XXX
 SG_ CECU681_6_4_SMT_LINK : 52|1@1+ (1,0) [0|1] "" Vector__XXX
 SG_ CECU681_6_3_IPMS_LINK : 51|1@1+ (1,0) [0|1] "" Vector__XXX
 SG_ CECU681_5_6_DP_DKYMEM_LIST_NO15 : 46|1@1+ (1,0) [0|1] "" Vector__XXX
 SG_ CECU681_5_5_DP_DKYMEM_LIST_NO14 : 45|1@1+ (1,0) [0|1] "" Vector__XXX
 SG_ CECU681_5_4_DP_DKYMEM_LIST_NO13 : 44|1@1+ (1,0) [0|1] "" Vector__XXX
 SG_ CECU681_5_3_DP_DKYMEM_LIST_NO12 : 43|1@1+ (1,0) [0|1] "" Vector__XXX
 SG_ CECU681_5_2_DP_DKYMEM_LIST_NO11 : 42|1@1+ (1,0) [0|1] "" Vector__XXX
 SG_ CECU681_5_1_DP_DKYMEM_LIST_NO10 : 41|1@1+ (1,0) [0|1] "" Vector__XXX
 SG_ CECU681_5_0_DP_DKYMEM_LIST_NO9 : 40|1@1+ (1,0) [0|1] "" Vector__XXX
 SG_ CECU681_4_7_DP_DKYMEM_LIST_NO8 : 39|1@1+ (1,0) [0|1] "" Vector__XXX
 SG_ CECU681_4_6_DP_DKYMEM_LIST_NO7 : 38|1@1+ (1,0) [0|1] "" Vector__XXX
 SG_ CECU681_4_5_DP_DKYMEM_LIST_NO6 : 37|1@1+ (1,0) [0|1] "" Vector__XXX
 SG_ CECU681_4_4_DP_DKYMEM_LIST_NO5 : 36|1@1+ (1,0) [0|1] "" Vector__XXX
 SG_ CECU681_4_3_DP_DKYMEM_LIST_NO4 : 35|1@1+ (1,0) [0|1] "" Vector__XXX
 SG_ CECU681_4_2_DP_DKYMEM_LIST_NO3 : 34|1@1+ (1,0) [0|1] "" Vector__XXX
 SG_ CECU681_4_1_DP_DKYMEM_LIST_NO2 : 33|1@1+ (1,0) [0|1] "" Vector__XXX
 SG_ CECU681_4_0_DP_DKYMEM_LIST_NO1 : 32|1@1+ (1,0) [0|1] "" Vector__XXX
 SG_ CECU681_3_5_RECOG_FACTOR : 29|3@1+ (1,0) [0|7] ""  AIL
 SG_ CECU681_3_4_RECOG_USER_VALIDFRAG : 28|1@1+ (1,0) [0|1] ""  AIL
 SG_ CECU681_3_0_RESULT_NOTICE_REQ : 24|4@1+ (1,0) [0|15] "" Vector__XXX
 SG_ CECU681_2_4_RECOG_USER_NO : 20|4@1+ (1,0) [0|15] ""  AIL
 SG_ CECU681_2_0_POPUP_NOTICE_NO : 16|4@1+ (1,0) [0|15] "" Vector__XXX
 SG_ CECU681_1_7_DP_FAILE_FRAG : 15|1@1+ (1,0) [0|1] "" Vector__XXX
 SG_ CECU681_1_5_DP_PROCESS_RESULT : 13|2@1+ (1,0) [0|3] "" Vector__XXX
 SG_ CECU681_1_4_POPUP_NOTICE_REQ : 12|1@1+ (1,0) [0|1] "" Vector__XXX
 SG_ CECU681_1_0_MSG_COUNTER : 8|4@1+ (1,0) [0|15] "" Vector__XXX
 SG_ CECU681_0_0_CHECK_SUM : 0|8@1+ (1,0) [0|255] "" Vector__XXX

CM_ SG_ 937 MET3A9_3_5_DAY_NIGHT_STATE "昼夜状態
";
CM_ SG_ 937 MET3A9_3_0_ILL_LEVEL "ｲﾙﾐ段数
";
CM_ SG_ 937 MET3A9_2_0_ILL_VALUE "ｲﾙﾐ輝度値
";
CM_ SG_ 937 MET3A9_1_7_BRIGHT_STATE "ﾌﾞﾗｲﾄ状態
";
CM_ SG_ 937 MET3A9_1_6_UI_THEME_STATE "UI Theme状態
";
CM_ SG_ 937 MET3A9_1_0_MSG_COUNTER "ﾒｯｾｰｼﾞｶｳﾝﾀ
";
CM_ SG_ 937 MET3A9_0_0_CHECKSUM "ﾁｪｯｸｻﾑ
";
CM_ SG_ 1614 RKE64E_6_0_BUZ_1SHOT_IN "室内ﾌﾞｻﾞｰ　単発1回吹鳴要求
";
CM_ SG_ 1614 RKE64E_6_1_BUZ_2SHOT_IN "室内ﾌﾞｻﾞｰ　単発2回吹鳴要求
";
CM_ SG_ 1614 RKE64E_6_2_REQ_WARNG_BAT_POWER "電池残量警告表示要求
";
CM_ SG_ 1614 RKE64E_4_0_TRANS_ID "送信機ID
";
CM_ SG_ 1614 RKE64E_4_3_COUNTER "ｶｳﾝﾀ値
";
CM_ SG_ 1614 RKE64E_4_5_TIME_ON_SW_KEY_LESS "SW ON時間
";
CM_ SG_ 1614 RKE64E_3_0_REQ_NOMAL_KEY_LESS "ﾉｰﾏﾙｷｰﾚｽ要求
";
CM_ SG_ 1614 RKE64E_1_0_MSG_COUNTER "ﾒｯｾｰｼﾞｶｳﾝﾀ
";
CM_ SG_ 1614 RKE64E_1_4_WAKE_UP_FRAME "ｳｪｲｸｱｯﾌﾟﾌﾚｰﾑ識別ﾌﾗｸﾞ
";
CM_ SG_ 1614 RKE64E_1_5_REQ_COMM_CONT "通信継続要求ﾌﾗｸﾞ
";
CM_ SG_ 1614 RKE64E_1_6 "予約:通信継続要求ﾌﾗｸﾞ(拡張)
";
CM_ SG_ 1614 RKE64E_0_0_CHECK_SUM "ﾁｪｯｸｻﾑ
";
CM_ SG_ 826 ABG33A_7_0_VELOCITYCHANGE_VX_MAX "衝突時ΔVx MAX
";
CM_ SG_ 826 ABG33A_6_0_VELOCITYCHANGE_VX_MAX "衝突時ΔVx MAX
";
CM_ SG_ 826 ABG33A_5_0_P_SIDE_ABG_DEPLOY "P席ｻｲﾄﾞｴｱﾊﾞｯｸﾞ展開判定
";
CM_ SG_ 826 ABG33A_5_1_D_SIDE_ABG_DEPLOY "D席ｻｲﾄﾞｴｱﾊﾞｯｸﾞ展開判定
";
CM_ SG_ 826 ABG33A_5_2_FRONT_FAR_ABG_DEPLOY "前席ﾌｧｰｻｲﾄﾞｴｱﾊﾞｯｸﾞ展開判定
";
CM_ SG_ 826 ABG33A_5_3_REAR_FAR_ABG_DEPLOY "後席ﾌｧｰｻｲﾄﾞｴｱﾊﾞｯｸﾞ展開判定
";
CM_ SG_ 826 ABG33A_5_4_REAR_RH_ABG_DEPLOY "後席ｻｲﾄﾞｴｱﾊﾞｯｸﾞRH展開判定
";
CM_ SG_ 826 ABG33A_5_5_REAR_LH_ABG_DEPLOY "後席ｻｲﾄﾞｴｱﾊﾞｯｸﾞLH展開判定
";
CM_ SG_ 826 ABG33A_5_6_P_CURTAIN_ABG_DEPLOY "P席ｶｰﾃﾝｴｱﾊﾞｯｸﾞ展開判定
";
CM_ SG_ 826 ABG33A_5_7_D_CURTAIN_ABG_DEPLOY "D席ｶｰﾃﾝｴｱﾊﾞｯｸﾞ展開判定
";
CM_ SG_ 826 ABG33A_4_0_D_FRONT_ABG_DEPLOY "D席ﾌﾛﾝﾄｴｱﾊﾞｯｸﾞ展開判定
";
CM_ SG_ 826 ABG33A_4_1_P_FRONT_ABG_DEPLOY "P席ﾌﾛﾝﾄｴｱﾊﾞｯｸﾞ展開判定
";
CM_ SG_ 826 ABG33A_4_2_P_ABG_DEPLOY "P席ｼｰﾄｸｯｼｮﾝｴｱﾊﾞｯｸﾞ展開判定
";
CM_ SG_ 826 ABG33A_4_3_D_ABG_DEPLOY "D席ｼｰﾄｸｯｼｮﾝｴｱﾊﾞｯｸﾞ展開判定
";
CM_ SG_ 826 ABG33A_4_4_P_BELT_PRETENTION "P席ｼｰﾄﾍﾞﾙﾄﾌﾟﾘﾃﾝｼｮﾅ展開判定
";
CM_ SG_ 826 ABG33A_4_5_D_BELT_PRETENTION "D席ｼｰﾄﾍﾞﾙﾄﾌﾟﾘﾃﾝｼｮﾅ展開判定
";
CM_ SG_ 826 ABG33A_4_6_D_KNEE_ABG_DEPLOY "D席ﾆｰｴｱﾊﾞｯｸﾞ展開判定
";
CM_ SG_ 826 ABG33A_4_7_P_KNEE_ABG_DEPLOY "P席ﾆｰｴｱﾊﾞｯｸﾞ展開判定
";
CM_ SG_ 826 ABG33A_3_0_BELT_WRNING_PASS "P席ﾍﾞﾙﾄ状態(ｳｫｰﾆﾝｸﾞ出力用)
";
CM_ SG_ 826 ABG33A_3_2_BUCKLESW_DRVR "D席ﾊﾞｯｸﾙｽｲｯﾁ
";
CM_ SG_ 826 ABG33A_3_4_OCCUPATION_PASS "P席乗員有無信号
";
CM_ SG_ 826 ABG33A_3_6_IND_ACT_ABG_PASS "P席A/B作動ﾓｰﾄﾞｲﾝｼﾞｹｰﾀ
";
CM_ SG_ 826 ABG33A_2_0_IND_WARN_ABG "ｴｱﾊﾞｯｸﾞｳｫｰﾆﾝｸﾞﾗﾝﾌﾟ点灯・点滅要求
";
CM_ SG_ 826 ABG33A_2_2_DETECT_CRUSH "衝突検知信号
";
CM_ SG_ 826 ABG33A_2_5_STATUS_CRUSH_ECALL "衝突形態
";
CM_ SG_ 826 ABG33A_1_0_MSG_COUNTER "ﾒｯｾｰｼﾞｶｳﾝﾀ
";
CM_ SG_ 826 ABG33A_1_4_FLG_ABGIND_CTRL "P席 A/B ON/OFFｲﾝｼﾞｹｰﾀ点灯要求有無ﾌﾗｸﾞ
";
CM_ SG_ 826 ABG33A_1_5_REQ_COMM_CONT "通信継続要求
";
CM_ SG_ 826 ABG33A_1_6_COLLISION_COUNTER "衝突判定回数
";
CM_ SG_ 826 ABG33A_0_0_CHECK_SUM "ﾁｪｯｸｻﾑ
";
CM_ SG_ 961 DMS3C1_7_4_SHORT_DIST_DETECT "ショートディストラクション判定フラグ
";
CM_ SG_ 961 DMS3C1_7_5_PRESENCE_DETECT "後席乗員検知情報
";
CM_ SG_ 961 DMS3C1_7_6_RADER_EQUIP "ミリ波搭載情報
";
CM_ SG_ 961 DMS3C1_7_7_LOSING_POSTURE_DETECT "異常姿勢検知フラグ
";
CM_ SG_ 961 DMS3C1_6_0_ID_RECOG_CANCEL "ID認識中断フラグ
";
CM_ SG_ 961 DMS3C1_6_1_ID_ENABLE_FLAG "ID有効フラグ
";
CM_ SG_ 961 DMS3C1_6_2_PERMIT_AVN_FLAG "AVN操作許可フラグ
";
CM_ SG_ 961 DMS3C1_6_4_DISTRACTION_STATUS "脇見状態フラグ
";
CM_ SG_ 961 DMS3C1_6_5_DROWSINESS_STATUS "閉眼状態フラグ
";
CM_ SG_ 961 DMS3C1_6_6_DROWSINESS_LV2_STATUS "強い眠気状態フラグ
";
CM_ SG_ 961 DMS3C1_6_7_NOT_DETECTED_STATUS "顔未検出状態フラグ
";
CM_ SG_ 961 DMS3C1_5_0_ID_LIST "ID登録リスト
";
CM_ SG_ 961 DMS3C1_5_5_ID_EDIT_FLAG "ID設定フラグ
";
CM_ SG_ 961 DMS3C1_4_0_DMS_IND_REQ_FLAG "インジゲータ点灯フラグ
";
CM_ SG_ 961 DMS3C1_4_3_DMS_RECOG_STATUS "個人認識ON/OFF状態
";
CM_ SG_ 961 DMS3C1_4_4_DRIVER_STATUS "D席乗員状態
";
CM_ SG_ 961 DMS3C1_3_0_DRIVER_REGIST_ID "個人ID
";
CM_ SG_ 961 DMS3C1_3_4_CUST_EDIT_FLAG "カスタマイズ操作フラグ
";
CM_ SG_ 961 DMS3C1_3_6_ID_RECOG_FLAG "ID識別フラグ
";
CM_ SG_ 961 DMS3C1_2_0_LEVEL_DROWS "居眠り深度
";
CM_ SG_ 961 DMS3C1_2_3_DROWS_DETECT_FLAG "居眠り判定フラグ
";
CM_ SG_ 961 DMS3C1_2_7_DIST_DETECT_FLAG "脇見判定フラグ
";
CM_ SG_ 961 DMS3C1_1_0_MSG_COUNTER "メッセージカウンタ
";
CM_ SG_ 961 DMS3C1_1_4_WAKE_UP_FRAME "ｳｪｲｸｱｯﾌﾟﾌﾚｰﾑ識別ﾌﾗｸﾞ
";
CM_ SG_ 961 DMS3C1_1_5_REQ_COMM_CONT "通信継続要求ﾌﾗｸﾞ
";
CM_ SG_ 961 DMS3C1_1_7_EYE_DIST_FLAG "早鳴りフラグ
";
CM_ SG_ 961 DMS3C1_0_0_CHKSUM "ﾁｪｯｸｻﾑ
";
CM_ SG_ 1651 ACN673_7_2_REQ_STRG_H "ステアリングヒータ動作要求
";
CM_ SG_ 1651 ACN673_7_1_SEAT_H_L_AUTOIND "シートヒータ空調（左側） AUTOIND点灯
";
CM_ SG_ 1651 ACN673_7_0_SEAT_H_R_AUTOIND "シートヒータ空調（右側） AUTOIND点灯
";
CM_ SG_ 1651 ACN673_6_0_RR_FAN_SYMBOL "RR FAN SYMBOL
";
CM_ SG_ 1651 ACN673_6_2_SEAT_H_R "シートヒータ空調（右側）
";
CM_ SG_ 1651 ACN673_6_5_SEAT_H_L "シートヒータ空調（左側）
";
CM_ SG_ 1651 ACN673_5_0_DR_ONLY "一席集中状態
";
CM_ SG_ 1651 ACN673_5_2_STRG_H "ステアリングヒータ状態
";
CM_ SG_ 1651 ACN673_5_4_AC_SI_DS_SET "SI-DS空調設定
";
CM_ SG_ 1651 ACN673_5_6_STRG_H_AUTOIND "ステアリングヒータ AUTO IND点灯
";
CM_ SG_ 1651 ACN673_5_7_AC_SI_DS_FLG "SI-DS空調有無フラグ
";
CM_ SG_ 1651 ACN673_4_0_SEAT_HEATER_DR "Dr席　シートヒーター作動状態
";
CM_ SG_ 1651 ACN673_4_2_SEAT_HEATER_PA "Pa席　シートヒーター作動状態
";
CM_ SG_ 1651 ACN673_4_4_SEAT_HEATER "シートヒーター有無
";
CM_ SG_ 1651 ACN673_4_5_TEMP_SET_TYPE "設定温度タイプ
";
CM_ SG_ 1651 ACN673_4_7_VENTI_SEAT_EX_HI "シート空調EX-HI
";
CM_ SG_ 1651 ACN673_1_0_MSG_COUNTER "ﾒｯｾｰｼﾞｶｳﾝﾀ
";
CM_ SG_ 1651 ACN673_1_6_SYNC_RR "SYNC_RR
";
CM_ SG_ 1651 ACN673_1_7_RR_LOCK "RR_LOCK
";
CM_ SG_ 1651 ACN673_0_0_CHECK_SUM "ﾁｪｯｸｻﾑ
";
CM_ SG_ 1650 ACN672_7_0_INFO_AUTO3MODE "AUTO3モード
";
CM_ SG_ 1650 ACN672_7_2_INFO_REAR_TEMP "Rr設定温度
";
CM_ SG_ 1650 ACN672_6_0_DEF "DEF
";
CM_ SG_ 1650 ACN672_6_1_FAN_SYMBOL "FAN SYMBOL
";
CM_ SG_ 1650 ACN672_6_2_REAR_MODE "Rr吹き出し口ﾓｰﾄﾞ
";
CM_ SG_ 1650 ACN672_6_4_UNIT_TEMP "温度仕様
";
CM_ SG_ 1650 ACN672_6_5_SPEC_AC_UNIT "空調仕様
";
CM_ SG_ 1650 ACN672_6_7_REAR_AC "ﾘｱ空調有無
";
CM_ SG_ 1650 ACN672_5_0_AC_VR_MODE "ｴｱｺﾝ音声認識ﾓｰﾄﾞ
";
CM_ SG_ 1650 ACN672_5_2_INFO_TEMP_PASS "Pa設定温度
";
CM_ SG_ 1650 ACN672_4_0_AC_INTERRUPT_DISPLAY "ｴｱｺﾝ割り込み画面表示
";
CM_ SG_ 1650 ACN672_4_1_AC_VR_ACTION "ｴｱｺﾝ音声認識ｺﾏﾝﾄﾞ実行
";
CM_ SG_ 1650 ACN672_4_2_INFO_TEMP_DRVR "Dr設定温度
";
CM_ SG_ 1650 ACN672_3_0_MAX_AC "MAX A/C
";
CM_ SG_ 1650 ACN672_3_1_INFO_SYNC_OR_SING "SYNC
";
CM_ SG_ 1650 ACN672_3_2_INFO_FULL_OR_AUTO "FULL及びAUTO
";
CM_ SG_ 1650 ACN672_3_4_INFO_AC_ON "A/C
";
CM_ SG_ 1650 ACN672_3_5_INFO_RDEF "Rrﾃﾞﾌ
";
CM_ SG_ 1650 ACN672_3_6_INFO_CIRCULATION "内外気
";
CM_ SG_ 1650 ACN672_2_0_INFO_MODE_VENT "吹き出し口ﾓｰﾄﾞ
";
CM_ SG_ 1650 ACN672_2_4_INFO_FANONLY "送風モード
";
CM_ SG_ 1650 ACN672_2_5_INFO_LEV_BLOWERFAN "ﾌｧﾝ段数
";
CM_ SG_ 1650 ACN672_1_0_MSG_COUNTER "ﾒｯｾｰｼﾞｶｳﾝﾀ
";
CM_ SG_ 1650 ACN672_1_4_LVL_BLOWERFAN_RR "Rrﾌｧﾝ段数
";
CM_ SG_ 1650 ACN672_1_7_REAR_AUTO "Rr AUTO
";
CM_ SG_ 1650 ACN672_0_0_CHECK_SUM "ﾁｪｯｸｻﾑ
";
CM_ SG_ 722 ACN2D2_7_0_PD_PRESSURE "A/C PD圧力値
";
CM_ SG_ 722 ACN2D2_6_0_TRQ_COMP_ESTM "ｺﾝﾌﾟﾚｯｻﾄﾙｸ推定値
";
CM_ SG_ 722 ACN2D2_5_0_REQ_ENG_RPM "ｴｱｺﾝ要求ｴﾝｼﾞﾝ回転数
";
CM_ SG_ 722 ACN2D2_5_3_REQ_IDLE_COMP_RPM "ｱｲﾄﾞﾙ時要求ｺﾝﾌﾟﾚｯｻ回転数
";
CM_ SG_ 722 ACN2D2_4_0_LVL_PTC "PTC段数 電気負荷情報
";
CM_ SG_ 722 ACN2D2_4_2_MARGIN_OF_AC "ｴｱｺﾝ余裕度
";
CM_ SG_ 722 ACN2D2_4_5_LVL_BLOWER_FAN "ﾌﾞﾛｱﾌｧﾝSW（電気負荷情報）
";
CM_ SG_ 722 ACN2D2_3_0_PERMIT_ISS "ISS作動許可
";
CM_ SG_ 722 ACN2D2_3_2_TRQ_PAT_COMP_ESTM "A/C見込みﾄﾙｸﾊﾟﾀｰﾝ
";
CM_ SG_ 722 ACN2D2_3_5_IND_ROOM_TEMP "室温表示
";
CM_ SG_ 722 ACN2D2_2_0_FAIL_TRQ_COMP_ESTM "ｺﾝﾌﾟﾚｯｻﾄﾙｸ推定値ﾌｪｰﾙ
";
CM_ SG_ 722 ACN2D2_2_1_FAIL_AC "A/Cﾌｪｰﾙ
";
CM_ SG_ 722 ACN2D2_2_2_REQ_INHIBIT_LOCKUP "L/U禁止要求
";
CM_ SG_ 722 ACN2D2_2_3_AC_ON "A/C信号
";
CM_ SG_ 722 ACN2D2_2_4_RDEFOGSW "RﾃﾞﾌｫｯｶﾞSW
";
CM_ SG_ 722 ACN2D2_2_5_WARM_UP "ｳｫｰﾑｱｯﾌﾟ信号
";
CM_ SG_ 722 ACN2D2_2_6_AC_AUTO_MANUAL "ｵｰﾄｴｱｺﾝ・ﾏﾆｭｱﾙｴｱｺﾝ判別信号
";
CM_ SG_ 722 ACN2D2_2_7_COMP_TYPE "ｺﾝﾌﾟﾚｯｻﾀｲﾌﾟ
";
CM_ SG_ 722 ACN2D2_1_0_MSG_COUNTER "ﾒｯｾｰｼﾞｶｳﾝﾀ
";
CM_ SG_ 722 ACN2D2_1_4 "ｳｪｲｸｱｯﾌﾟﾌﾚｰﾑ識別ﾌﾗｸﾞ
";
CM_ SG_ 722 ACN2D2_1_5 "通信継続要求ﾌﾗｸﾞ
";
CM_ SG_ 722 ACN2D2_1_6 "予約:通信継続要求ﾌﾗｸﾞ(拡張)
";
CM_ SG_ 722 ACN2D2_1_7_WARM_POWER_CONT "暖房促進制御信号
";
CM_ SG_ 722 ACN2D2_0_0_CHECK_SUM "ﾁｪｯｸｻﾑ
";
CM_ SG_ 1722 AVN6BA_7_0_GUIDE_LINE_REAR "Rカメラガイド線表示設定(ON/OFF)
";
CM_ SG_ 1722 AVN6BA_7_1_GUIDE_LINE_SIDE "Sカメラガイド線表示設定(ON/OFF)
";
CM_ SG_ 1722 AVN6BA_7_2_GUIDE_LINE_FRONT "Fカメラガイド線表示設定(ON/OFF)
";
CM_ SG_ 1722 AVN6BA_7_3_STEER_ANGLE_INTERLOCK "Rカメラガイド線舵角連動設定(連動/固定)
";
CM_ SG_ 1722 AVN6BA_7_4_BACK_CAMERA_DELAY "Rカメラ9秒Delay表示設定(ON/OFF)
";
CM_ SG_ 1722 AVN6BA_7_5_REQ_STOP_CAMERA_OUT "カメラ映像出力停止要求フラグ
";
CM_ SG_ 1722 AVN6BA_7_6_VIEW_CHANGE_SW "カメラ切替SW信号
";
CM_ SG_ 1722 AVN6BA_6_0_CLIMAITE_PA_TEMP "音声認識ｴｱｺﾝ Pa_TEMP
";
CM_ SG_ 1722 AVN6BA_6_6_CLIMATE_SYNC "ｴｱｺﾝﾊﾟﾈﾙ SYNC SW
";
CM_ SG_ 1722 AVN6BA_6_7_CLIMATE_F_DEF "Front DEF SW
";
CM_ SG_ 1722 AVN6BA_5_0_CLIMAITE_DR_TEMP "音声認識ｴｱｺﾝ Dr_TEMP
";
CM_ SG_ 1722 AVN6BA_5_6_CLIMAITE_AUTO "音声認識ｴｱｺﾝ AUTO SW
";
CM_ SG_ 1722 AVN6BA_5_7_CLIMAITE_MAX_AC "音声認識ｴｱｺﾝ MAX A/C SW
";
CM_ SG_ 1722 AVN6BA_4_0_CLIMAITE_VR "音声認識ｴｱｺﾝ操作ﾌﾗｸﾞ
";
CM_ SG_ 1722 AVN6BA_4_3_CLIMATE_AC "ｴｱｺﾝﾊﾟﾈﾙ A/C SW
";
CM_ SG_ 1722 AVN6BA_4_4_CLIMAITE_FAN "音声認識ｴｱｺﾝ FAN
";
CM_ SG_ 1722 AVN6BA_3_0_PERSONAL_IC_SH "ﾊﾟｰｿﾅﾗｲｽﾞ：H/Unit（ｽﾏｰﾄﾌｫﾝ無し時）による個人識別ｺｰﾄﾞ
";
CM_ SG_ 1722 AVN6BA_3_4_CSTM_SONNER "ｿﾅｰｶｽﾀﾏｲｽﾞ変更設定(ｿﾅｰ ON/OFF)
";
CM_ SG_ 1722 AVN6BA_3_5_CSTM_RAB "ｿﾅｰｶｽﾀﾏｲｽﾞ変更設定(RAB　ON/OFF)
";
CM_ SG_ 1722 AVN6BA_3_6_REQ_CHG_CSTM_RAB "RABｿﾅｰｶｽﾀﾏｲｽﾞ要求変更
";
CM_ SG_ 1722 AVN6BA_3_7_CLIMATE_R_DEF "Rear DEF SW
";
CM_ SG_ 1722 AVN6BA_2_0_CLIMATE_PTC "ｴｱｺﾝﾊﾟﾈﾙ PTC 強制ON SW
";
CM_ SG_ 1722 AVN6BA_2_1_CLIMATE_MODE "ｴｱｺﾝﾊﾟﾈﾙ MODE SW
";
CM_ SG_ 1722 AVN6BA_2_2_CLIMATE_SEAT_C_L "ｴｱｺﾝﾊﾟﾈﾙ ﾍﾞﾝﾁﾚｰｼｮﾝｼｰﾄ左 SW
";
CM_ SG_ 1722 AVN6BA_2_3_CLIMATE_SEAT_C_R "ｴｱｺﾝﾊﾟﾈﾙ ﾍﾞﾝﾁﾚｰｼｮﾝｼｰﾄ右 SW
";
CM_ SG_ 1722 AVN6BA_2_4_CLIMATE_SEAT_H_L "ｴｱｺﾝﾊﾟﾈﾙ SEAT HEATER左 SW
";
CM_ SG_ 1722 AVN6BA_2_5_CLIMATE_SEAT_H_R "ｴｱｺﾝﾊﾟﾈﾙ SEAT HEATER右 SW
";
CM_ SG_ 1722 AVN6BA_2_6_CLIMATE_INNER_AIR "ｴｱｺﾝﾊﾟﾈﾙ 内外気 SW
";
CM_ SG_ 1722 AVN6BA_2_7_CLIMATE_ON_OFF "ｴｱｺﾝﾊﾟﾈﾙ 空調ON/OFF SW
";
CM_ SG_ 1722 AVN6BA_1_0_MSG_COUNTER "ﾒｯｾｰｼﾞｶｳﾝﾀ
";
CM_ SG_ 1722 AVN6BA_1_4_CLIMAITE_STATUS "音声認識状態表示
";
CM_ SG_ 1722 AVN6BA_1_7_CLIMAITE_ON_OFF "音声認識 ON/OFF
";
CM_ SG_ 1722 AVN6BA_0_0_CHECK_SUM "ﾁｪｯｸｻﾑ
";
CM_ SG_ 1019 AVN3FB_7_0_SMT_TIM_RESET_REQ "自動ｴﾝｼﾞﾝ停止ﾀｲﾏﾘｾｯﾄ要求
";
CM_ SG_ 1019 AVN3FB_7_1_SMT_EG_CSTM_REQ "自動ｴﾝｼﾞﾝ停止カスタマイズ変更要求
";
CM_ SG_ 1019 AVN3FB_7_2_EYE_YEILD_CSTM "特殊標識表示ON/OFF設定（前方優先道路）
";
CM_ SG_ 1019 AVN3FB_7_3_EYE_STOP_CSTM "特殊標識表示ON/OFF設定（一時停止）
";
CM_ SG_ 1019 AVN3FB_7_4_EYE_NO_ENTRY_CSTM "特殊標識表示ON/OFF設定（進入禁止）
";
CM_ SG_ 1019 AVN3FB_7_5_MVS_CAMERA_SELECT_SW "MVSｶﾒﾗ切替画面内ｽｲｯﾁ情報
";
CM_ SG_ 1019 AVN3FB_7_7_ACPANEL_DR_ONLY "ｴｱｺﾝﾊﾟﾈﾙ 一席集中 SW
";
CM_ SG_ 1019 AVN3FB_6_0_ACPANEL_PA_TEMP "ｴｱｺﾝﾊﾟﾈﾙ Ｐ席TEMP
";
CM_ SG_ 1019 AVN3FB_6_6_ACPANEL_MODE_DOWN "ｴｱｺﾝﾊﾟﾈﾙ 吹き出し口MODE- SW
";
CM_ SG_ 1019 AVN3FB_6_7_ACPANEL_MODE_UP "ｴｱｺﾝﾊﾟﾈﾙ 吹き出し口MODE+ SW
";
CM_ SG_ 1019 AVN3FB_5_0_ACPANEL_DR_TEMP "ｴｱｺﾝﾊﾟﾈﾙ D席TEMP
";
CM_ SG_ 1019 AVN3FB_5_6_ACPANEL_FAN_DOWN "ｴｱｺﾝﾊﾟﾈﾙ FAN DOWN SW
";
CM_ SG_ 1019 AVN3FB_5_7_ACPANEL_FAN_UP "ｴｱｺﾝﾊﾟﾈﾙ FAN UP SW
";
CM_ SG_ 1019 AVN3FB_4_0_ACPANEL_FAN_LEVEL "ｴｱｺﾝﾊﾟﾈﾙ FAN段数
";
CM_ SG_ 1019 AVN3FB_4_4_ACPANEL_MODE_VENT "ｴｱｺﾝﾊﾟﾈﾙ 吹き出し口MODE指定
";
CM_ SG_ 1019 AVN3FB_3_0_ACPANEL_PA_TEMP_DOWN "ｴｱｺﾝﾊﾟﾈﾙ P席TEMP設定DOWN SW
";
CM_ SG_ 1019 AVN3FB_3_1_ACPANEL_PA_TEMP_UP "ｴｱｺﾝﾊﾟﾈﾙ P席TEMP設定UP SW
";
CM_ SG_ 1019 AVN3FB_3_2_ACPANEL_DR_TEMP_DOWN "ｴｱｺﾝﾊﾟﾈﾙ D席TEMP設定DOWN SW
";
CM_ SG_ 1019 AVN3FB_3_3_ACPANEL_DR_TEMP_UP "ｴｱｺﾝﾊﾟﾈﾙ D席TEMP設定UP SW
";
CM_ SG_ 1019 AVN3FB_3_4_ACPANEL_SYNC "ｴｱｺﾝﾊﾟﾈﾙ SYNC SW
";
CM_ SG_ 1019 AVN3FB_3_5_ACPANEL_AC "ｴｱｺﾝﾊﾟﾈﾙ A/C SW
";
CM_ SG_ 1019 AVN3FB_3_6_F_DEF_SW "Front DEF SW
";
CM_ SG_ 1019 AVN3FB_3_7_R_DEF_SW "Rear DEF SW
";
CM_ SG_ 1019 AVN3FB_2_0_ACPANEL_AUTO "ｴｱｺﾝﾊﾟﾈﾙ AUTO SW
";
CM_ SG_ 1019 AVN3FB_2_1_ACPANEL_MAX_AC "ｴｱｺﾝﾊﾟﾈﾙ MAX A/C SW
";
CM_ SG_ 1019 AVN3FB_2_2_ACPANEL_SEAT_C_P "ｴｱｺﾝﾊﾟﾈﾙ ﾍﾞﾝﾁﾚｰｼｮﾝｼｰﾄ P席 SW
";
CM_ SG_ 1019 AVN3FB_2_3_ACPANEL_SEAT_C_D "ｴｱｺﾝﾊﾟﾈﾙ ﾍﾞﾝﾁﾚｰｼｮﾝｼｰﾄ D席 SW
";
CM_ SG_ 1019 AVN3FB_2_4_ACPANEL_SEAT_H_P "ｴｱｺﾝﾊﾟﾈﾙ SEAT HEATER P席 SW
";
CM_ SG_ 1019 AVN3FB_2_5_ACPANEL_SEAT_H_D "ｴｱｺﾝﾊﾟﾈﾙ SEAT HEATER D席 SW
";
CM_ SG_ 1019 AVN3FB_2_6_ACPANEL_INNER_AIR "ｴｱｺﾝﾊﾟﾈﾙ 内外気 SW
";
CM_ SG_ 1019 AVN3FB_2_7_ACPANEL_AC_ON_OFF "ｴｱｺﾝﾊﾟﾈﾙ 空調ON/OFF
";
CM_ SG_ 1019 AVN3FB_1_0_MSG_COUNTER "ﾒｯｾｰｼﾞｶｳﾝﾀ
";
CM_ SG_ 1019 AVN3FB_1_4_EYE_CSTM_REQ_3FB "EyeSightｶｽﾀﾏｲｽﾞ変更要求_3FB
";
CM_ SG_ 1019 AVN3FB_1_5_DDAW_WARNING_CSTM "DDAW ON/OFF設定
";
CM_ SG_ 1019 AVN3FB_1_6_SIGN_SWITCH_SND "標識切り替わり音 ON/OFF設定
";
CM_ SG_ 1019 AVN3FB_1_7_SLWF_CSTM "SLWF ON/OFF設定
";
CM_ SG_ 1019 AVN3FB_0_0_CHECK_SUM "ﾁｪｯｸｻﾑ
";
CM_ SG_ 1366 CAB556_0_0_NETWORK_STATUS "ﾈｯﾄﾜｰｸｽﾃｰﾀｽ
";
CM_ SG_ 1767 RES6E7_2_0_DATA2 "通信データ2
";
CM_ SG_ 1767 RES6E7_1_0_MSG_COUNTER "ﾒｯｾｰｼﾞｶｳﾝﾀ
";
CM_ SG_ 1767 RES6E7_1_4_DATA1 "通信データ1
";
CM_ SG_ 1767 RES6E7_0_0_CHECK_SUM "ﾁｪｯｸｻﾑ
";
CM_ SG_ 1765 RES6E5_6_0_REQ_DOOR_LOCK_ARM "再ARM用ﾄﾞｱﾛｯｸ要求
";
CM_ SG_ 1765 RES6E5_6_1_REQ_ST_ON "ST ON要求
";
CM_ SG_ 1765 RES6E5_6_2_REQ_POWER_ON "電源ON要求
";
CM_ SG_ 1765 RES6E5_6_3_ON_SIGN "ﾘﾓｽﾀON信号
";
CM_ SG_ 1765 RES6E5_5_5_REQ_PARKLIGHT_HORN "ﾊﾟｰｸﾗｲﾄ＆ﾎｰﾝ要求
";
CM_ SG_ 1765 RES6E5_1_0_MSG_COUNTER "ﾒｯｾｰｼﾞｶｳﾝﾀ
";
CM_ SG_ 1765 RES6E5_1_4_WAKE_UP_FRAME "ｳｪｲｸｱｯﾌﾟﾌﾚｰﾑ識別ﾌﾗｸﾞ
";
CM_ SG_ 1765 RES6E5_1_5_REQ_COMM_CONT "通信継続要求ﾌﾗｸﾞ
";
CM_ SG_ 1765 RES6E5_1_6 "予約:通信継続要求ﾌﾗｸﾞ(拡張)
";
CM_ SG_ 1765 RES6E5_0_0_CHECK_SUM "ﾁｪｯｸｻﾑ
";
CM_ SG_ 1696 AIL6A0_7_0_AIL_RENDER_STA "AIL 演出
";
CM_ SG_ 1696 AIL6A0_7_3_AIL_RENDER_PAT_A_DIS "AIL演出_パターンA表示有無
";
CM_ SG_ 1696 AIL6A0_7_4_AIL_RENDER_PAT_B_DIS "AIL演出_パターンB表示有無
";
CM_ SG_ 1696 AIL6A0_7_5_AIL_RENDER_PAT_C_DIS "AIL演出_パターンC表示有無
";
CM_ SG_ 1696 AIL6A0_7_6_AIL_RENDER_PAT_D_DIS "AIL 演出_パターンD表示有無
";
CM_ SG_ 1696 AIL6A0_7_7_AIL_RENDER_DR_MD_DIS "AIL 演出_走行モード連動表示有無
";
CM_ SG_ 1696 AIL6A0_6_0_AIL_FIRST_BRIGHT_STA "AIL 第1照明_輝度状態
";
CM_ SG_ 1696 AIL6A0_6_4_AIL_SECOND_BRIGHT_STA "AIL 第2照明_輝度状態
";
CM_ SG_ 1696 AIL6A0_5_0_AIL_SECOND_COLOR_STA "AIL第2照明_カラー状態
";
CM_ SG_ 1696 AIL6A0_5_6_AIL_CSTM_PRS_DIS_REQ "AIL CUSTOMプリセット表示要求
";
CM_ SG_ 1696 AIL6A0_5_7_AIL_RENDER_CSTM_DIS "AIL 演出_CUSTOM・CUSTOMプリセット表示有無
";
CM_ SG_ 1696 AIL6A0_4_0_AIL_FIRST_COLOR_STA "AIL 第1照明_カラー状態
";
CM_ SG_ 1696 AIL6A0_4_6_AIL_SECOND_COLOR_DIS "AIL 第2照明_カラー表示有無
";
CM_ SG_ 1696 AIL6A0_4_7_AIL_SECOND_BRIGHT_DIS "AIL第2照明_輝度表示有無
";
CM_ SG_ 1696 AIL6A0_3_0_AIL_ADAS_VEH_DIS_STA "AIL ADAS_車間距離連動変更要求
";
CM_ SG_ 1696 AIL6A0_3_1_AIL_ADAS_VEH_DIS__DIS "AIL ADAS_車間距離連動表示有無
";
CM_ SG_ 1696 AIL6A0_3_2_AIL_ADAS_LANE_DEV_STA "AIL ADAS_車線逸脱連動状態
";
CM_ SG_ 1696 AIL6A0_3_3_AIL_ADAS_LANE_DEV_DIS "AIL ADAS_車線逸脱連動表示有無
";
CM_ SG_ 1696 AIL6A0_3_4_AIL_ADAS_FT_CROSS_STA "AIL ADAS_前側方飛び出し連動状態
";
CM_ SG_ 1696 AIL6A0_3_5_AIL_ADAS_FT_CROSS_DIS "AIL ADAS_前側方飛び出し連動表示有無
";
CM_ SG_ 1696 AIL6A0_3_6_AIL_ADAS_HANDS_FR_STA "AIL ADAS_ハンズフリー切り替え連動状態
";
CM_ SG_ 1696 AIL6A0_3_7_AIL_ADAS_HANDS_FR_DIS "AIL ADAS_ハンズフリー切り替え連動表示有無
";
CM_ SG_ 1696 AIL6A0_2_0_AIL_ADAS_EXP_STA "AIL ADAS連動状態
";
CM_ SG_ 1696 AIL6A0_2_1_AIL_ADAS_EXP_DIS "AIL ADAS連動表示有無
";
CM_ SG_ 1696 AIL6A0_2_2_AIL_NOTIFI_EXP_STA "AIL おしらせ連動状態
";
CM_ SG_ 1696 AIL6A0_2_3_AIL_NOTIFI_EXP_DIS "AIL おしらせ連動表示有無
";
CM_ SG_ 1696 AIL6A0_2_4_AIL_AIR_CON_EXP_STA "AIL 空調連動状態
";
CM_ SG_ 1696 AIL6A0_2_5_AIL_AIR_CON_EXP_DIS "AIL 空調連動表示有無
";
CM_ SG_ 1696 AIL6A0_1_0_MSG_COUNTER "メッセージカウンタ
";
CM_ SG_ 1696 AIL6A0_1_4_AIL_ON_OFF_STA "AIL ON/OFF状態
";
CM_ SG_ 1696 AIL6A0_1_6_AIL_WEL_FOL_STA "AIL ｳｴﾙｶﾑﾌｫﾛｰﾐｰ連動状態
";
CM_ SG_ 1696 AIL6A0_1_7_AIL_WEL_FOL_DIS "AIL ｳｴﾙｶﾑﾌｫﾛｰﾐｰ連動表示有無
";
CM_ SG_ 1696 AIL6A0_0_0_CHECK_SUM "チェックサム
";
CM_ SG_ 1314 AIL522_1_4_ActiveWakeUpBit "Active Wakeup ﾌﾗｸﾞ
";
CM_ SG_ 1314 AIL522_0_0_SourceNodeID "送信元ID
";
CM_ SG_ 1635 AHL663_3_0_FAIL_ADB "ADB故障警告灯
";
CM_ SG_ 1635 AHL663_3_2_HEADLAMP_HI_IND "ﾍｯﾄﾞﾗﾝﾌﾟ Hiﾋﾞｰﾑｲﾝｼﾞｹｰﾀ
";
CM_ SG_ 1635 AHL663_3_3_ADB_ACTIVE_IND "ADB作動ｲﾝｼﾞｹｰﾀ
";
CM_ SG_ 1635 AHL663_3_4_CSTM_SRH_OFF "SRH OFF 機能ｶｽﾀﾏｲｽﾞ設定
";
CM_ SG_ 1635 AHL663_2_0_FAIL_AHL "ｵｰﾄﾍｯﾄﾞﾗﾝﾌﾟﾚﾍﾞﾗ異常
";
CM_ SG_ 1635 AHL663_2_3_FAIL_LED_HEADLAMP "LEDﾍｯﾄﾞﾗﾝﾌﾟ異常
";
CM_ SG_ 1635 AHL663_2_5_IND_AFS "AFSｲﾝｼﾞｹｰﾀ信号
";
CM_ SG_ 1635 AHL663_1_0_MSG_COUNTER "ﾒｯｾｰｼﾞｶｳﾝﾀ
";
CM_ SG_ 1635 AHL663_1_6 "予約:通信継続要求ﾌﾗｸﾞ(拡張)
";
CM_ SG_ 1635 AHL663_0_0_CHECK_SUM "ﾁｪｯｸｻﾑ
";
CM_ SG_ 818 PMN332_7_0_RES_CONTROL_STATUS "リモスタ制御状態
";
CM_ SG_ 818 PMN332_7_2_REQ_RES_P_LOCK "ﾘﾓｽﾀ制御ｼﾌﾄPﾛｯｸ要求
";
CM_ SG_ 818 PMN332_7_5_IGB_RELAY_REQ "IGbリレー指示値
";
CM_ SG_ 818 PMN332_7_6_IGA_RELAY_REQ "IGaリレー指示値
";
CM_ SG_ 818 PMN332_7_7_REQ_STOP_RES "ﾘﾓｽﾀ停止要求
";
CM_ SG_ 818 PMN332_6_0_RES_IDLE_TIME "ﾘﾓｽﾀ累積ｴﾝｼﾞﾝON時間
";
CM_ SG_ 818 PMN332_6_7_CUST "自動E/G停止カスタマイズ設定値
";
CM_ SG_ 818 PMN332_5_0_PUSHSTART_SW "ﾌﾟｯｼｭｽﾀｰﾄSW信号
";
CM_ SG_ 818 PMN332_5_1_SIG_KEY_PUSHSTART "ﾌﾟｯｼｭｽﾀｰﾄ用ｷｰ信号
";
CM_ SG_ 818 PMN332_5_2_STATE_MODE_POWER "電源ﾓｰﾄﾞ状態信号
";
CM_ SG_ 818 PMN332_5_4_BUZ_2SHOT_IN "室内ﾌﾞｻﾞｰ　単発2回吹鳴要求
";
CM_ SG_ 818 PMN332_5_5_BUZ_INTERMIT1_IN "室内ﾌﾞｻﾞｰ　断続吹鳴1要求
";
CM_ SG_ 818 PMN332_5_6_BUZ_INTERMIT2_IN "室内ﾌﾞｻﾞｰ　断続吹鳴2要求(0.7s周期)
";
CM_ SG_ 818 PMN332_5_7_BUZ_CONTINUE_IN "室内ﾌﾞｻﾞｰ　連続吹鳴要求
";
CM_ SG_ 818 PMN332_2_0_WARN_SSP_SIG1 "ｽﾏｰﾄｼｽﾃﾑ警報信号(電源)1
";
CM_ SG_ 818 PMN332_2_1_WARN_SSP_SIG2 "ｽﾏｰﾄｼｽﾃﾑ警報信号(電源)2
";
CM_ SG_ 818 PMN332_2_4_SMT_PWR_SIG "ｽﾏｰﾄｼｽﾃﾑ電源状態信号
";
CM_ SG_ 818 PMN332_2_7_BUZ_1SHOT_IN "室内ﾌﾞｻﾞｰ　単発1回吹鳴
";
CM_ SG_ 818 PMN332_1_0_MSG_COUNTER "ﾒｯｾｰｼﾞｶｳﾝﾀ
";
CM_ SG_ 818 PMN332_0_0_CHECK_SUM "ﾁｪｯｸｻﾑ
";
CM_ SG_ 1603 SMT643_2_0_DATA2 "通信データ2
";
CM_ SG_ 1603 SMT643_1_0_MSG_COUNTER "ﾒｯｾｰｼﾞｶｳﾝﾀ
";
CM_ SG_ 1603 SMT643_1_4_DATA1 "通信データ1
";
CM_ SG_ 1603 SMT643_0_0_CHECK_SUM "ﾁｪｯｸｻﾑ
";
CM_ SG_ 1601 SMT641_5_0_RKE_BODY_INF_BYTE3 "RKE-BODY間通信INF-Byte3
";
CM_ SG_ 1601 SMT641_4_0_RKE_BODY_INF_BYTE2 "RKE-BODY間通信INF-Byte2
";
CM_ SG_ 1601 SMT641_3_0_RKE_BODY_INF_BYTE1 "RKE-BODY間通信INF-Byte1
";
CM_ SG_ 1601 SMT641_2_0_RKE_BODY_CTL_BYTE "RKE-BODY間通信CTL-Byte
";
CM_ SG_ 1601 SMT641_1_0_MSG_COUNTER "ﾒｯｾｰｼﾞｶｳﾝﾀ
";
CM_ SG_ 1601 SMT641_0_0_CHECK_SUM "ﾁｪｯｸｻﾑ
";
CM_ SG_ 1600 SMT640_7_0_RES_CONTROL_STATUS "リモスタ制御状態
";
CM_ SG_ 1600 SMT640_7_2_REQ_RES_P_LOCK "ﾘﾓｽﾀ制御ｼﾌﾄPﾛｯｸ要求
";
CM_ SG_ 1600 SMT640_7_4_KEY_STATUS "キー状態
";
CM_ SG_ 1600 SMT640_7_5_KEY_SEARCH_RESULT "車室内ｱｸｾｽｷｰ判定結果
";
CM_ SG_ 1600 SMT640_7_7_REQ_STOP_RES "ﾘﾓｽﾀ停止要求
";
CM_ SG_ 1600 SMT640_6_0_RES_IDLE_TIME "ﾘﾓｽﾀ累積ｴﾝｼﾞﾝON時間
";
CM_ SG_ 1600 SMT640_5_1_IND_SECURITY "ｾｷｭﾘﾃｨｲﾝｼﾞｹｰﾀ駆動
";
CM_ SG_ 1600 SMT640_5_3_BUZ_WAL_WIUL_PAUSE "WAL/WIUL一時停止モード設定ブザー吹鳴要求
";
CM_ SG_ 1600 SMT640_5_4_BUZ_ALA_MAX "室外ブザー警笛MAX音量
";
CM_ SG_ 1600 SMT640_5_5_PRG_LOCK_SW_STATE "PRGロックSW状態信号
";
CM_ SG_ 1600 SMT640_3_0_VERIFY_VALUE_OUT "車室外照合結果信号
";
CM_ SG_ 1600 SMT640_2_0_BUZ_NUM_OUT "室外ﾌﾞｻﾞｰ吹鳴回数
";
CM_ SG_ 1600 SMT640_2_4_BUZ_PAT_OUT "室外ﾌﾞｻﾞｰ吹鳴ﾊﾟﾀｰﾝ
";
CM_ SG_ 1600 SMT640_1_0_MSG_COUNTER "ﾒｯｾｰｼﾞｶｳﾝﾀ
";
CM_ SG_ 1600 SMT640_0_0_CHECK_SUM "ﾁｪｯｸｻﾑ
";
CM_ SG_ 816 SMT330_7_0 "プッシュSW故障
";
CM_ SG_ 816 SMT330_7_1 "IG OFF予告
";
CM_ SG_ 816 SMT330_7_3_HF_CAPA_ERR_ST "HFｾﾝｻｰ静電容量異常状態
";
CM_ SG_ 816 SMT330_7_6_HF_RESP_ERR_ST "HFｾﾝｻｰﾚｽﾎﾟﾝｽｴﾗｰ
";
CM_ SG_ 816 SMT330_6_0_REQ_MESS_PUSHSTART "ﾌﾟｯｼｭｽﾀｰﾄﾒｯｾｰｼﾞ要求
";
CM_ SG_ 816 SMT330_6_4_WARN_SSP_SIG1 "ｽﾏｰﾄｼｽﾃﾑ警報信号1
";
CM_ SG_ 816 SMT330_5_1_WIUL_CUST "WIUL機能ｶｽﾀﾏｲｽﾞ
";
CM_ SG_ 816 SMT330_5_2_WAL_CUST "WAL機能ｶｽﾀﾏｲｽﾞ
";
CM_ SG_ 816 SMT330_5_3_WARN_SSP_SIG2 "ｽﾏｰﾄｼｽﾃﾑ警報信号2
";
CM_ SG_ 816 SMT330_5_5_WARN_SSP_SIG3 "ｽﾏｰﾄｼｽﾃﾑ警報信号3
";
CM_ SG_ 816 SMT330_4_0_PUSHSTART_SW "ﾌﾟｯｼｭｽﾀｰﾄSW信号
";
CM_ SG_ 816 SMT330_4_1_SIG_KEY_PUSHSTART "ﾌﾟｯｼｭｽﾀｰﾄ用ｷｰ信号
";
CM_ SG_ 816 SMT330_4_2_HF_TOUCH_STATUS "HFｾﾝｻｰ検出状態
";
CM_ SG_ 816 SMT330_4_5_HF_KICK_STATUS "ｷｯｸｾﾝｻｰ検出状態
";
CM_ SG_ 816 SMT330_3_0_BUZ_1SHOT_IN "室内ﾌﾞｻﾞｰ　単発1回吹鳴要求
";
CM_ SG_ 816 SMT330_3_1_BUZ_2SHOT_IN "室内ﾌﾞｻﾞｰ　単発2回吹鳴要求
";
CM_ SG_ 816 SMT330_3_2_BUZ_INTERMIT1_IN "室内ﾌﾞｻﾞｰ　断続吹鳴1要求
";
CM_ SG_ 816 SMT330_3_3_BUZ_INTERMIT2_IN "室内ﾌﾞｻﾞｰ　断続吹鳴2要求（0.7s周期）
";
CM_ SG_ 816 SMT330_3_4_BUZ_CONTINUE_IN "室内ﾌﾞｻﾞｰ　連続吹鳴要求
";
CM_ SG_ 816 SMT330_3_5_BUZ_TRPON_OK_IN "室内ﾌﾞｻﾞｰ　ﾄﾗﾎﾟﾝ照合完了通知要求
";
CM_ SG_ 816 SMT330_3_6_STATE_MODE_POWER "電源ﾓｰﾄﾞ状態信号
";
CM_ SG_ 816 SMT330_1_0_MSG_COUNTER "ﾒｯｾｰｼﾞｶｳﾝﾀ
";
CM_ SG_ 816 SMT330_1_4_WAKE_UP_FRAME "ｳｪｲｸｱｯﾌﾟﾌﾚｰﾑ識別ﾌﾗｸﾞ
";
CM_ SG_ 816 SMT330_1_5_REQ_COMM_CONT "通信継続要求ﾌﾗｸﾞ
";
CM_ SG_ 816 SMT330_1_6 "予約:通信継続要求ﾌﾗｸﾞ(拡張)
";
CM_ SG_ 816 SMT330_0_0_CHECK_SUM "ﾁｪｯｸｻﾑ
";
CM_ SG_ 1622 BIU656_6_0_KICK_OPEN_REQ_PRG "ｷｯｸ要因PRGｵｰﾌﾟﾝ要求
";
CM_ SG_ 1622 BIU656_6_1_KICK_CLOSE_REQ_PRG "ｷｯｸ要因PRGｸﾛｰｽﾞ要求
";
CM_ SG_ 1622 BIU656_6_6_CARGO_LAMP_OUT "カーゴランプ出力情報
";
CM_ SG_ 1622 BIU656_6_7_PERMITT_KEY_RG_UNL "キーレス R/G SW RG解錠許可状態
";
CM_ SG_ 1622 BIU656_5_0_PRG_DRVR_OPENERSW "PRGD席ｵｰﾌﾟﾅSW
";
CM_ SG_ 1622 BIU656_5_1_HF_PRG_OFF_SW "ﾊﾝｽﾞﾌﾘｰPRG OFF SW
";
CM_ SG_ 1622 BIU656_5_2_PERMIT_OPEN_RG "R/Gｵｰﾌﾟﾝ許可状態
";
CM_ SG_ 1622 BIU656_5_3_BUZ_ON_OFF "ﾌﾞｻﾞｰ吹鳴ON/OFF
";
CM_ SG_ 1622 BIU656_5_4_PRG_DRVR_SW_PERMIT "PRG D席ｵｰﾌﾟﾅｰSW許可状態
";
CM_ SG_ 1622 BIU656_5_5_CSTM_HF_PRG_LOCK "ﾊﾝｽﾞﾌﾘｰPRGﾛｯｸ有無
";
CM_ SG_ 1622 BIU656_5_6_CSTM_KICK_SENSOR "ｷｯｸｾﾝｻ有無
";
CM_ SG_ 1622 BIU656_5_7_KICK_REQ_PRG "ｷｯｸ要因PRG駆動要求
";
CM_ SG_ 1622 BIU656_4_0_NOT_SMT_KEY_RG_SW "ｷｰﾚｽ R/G SW（ｽﾏｰﾄ無し車）
";
CM_ SG_ 1622 BIU656_4_2_SMT_KEY_RG_SW "ｷｰﾚｽ R/G SW（ｽﾏｰﾄ有り車）
";
CM_ SG_ 1622 BIU656_4_4_OPEN_RG_OPENER_SW "RｹﾞｰﾄｵｰﾌﾟﾅSW駆動処理
";
CM_ SG_ 1622 BIU656_3_4_CHECKED_KEYNO "照合ｷｰNo.
";
CM_ SG_ 1622 BIU656_3_7_LOCKSTATUS_DRVR "ﾄﾞｱﾛｯｸ状態信号（運席）
";
CM_ SG_ 1622 BIU656_2_0_TRIG_LOCK_UNLOCK "ﾄﾞｱﾛｯｸ/ｱﾝﾛｯｸ出力情報
";
CM_ SG_ 1622 BIU656_1_0_MSG_COUNTER "ﾒｯｾｰｼﾞｶｳﾝﾀ
";
CM_ SG_ 1622 BIU656_0_0_CHECK_SUM "ﾁｪｯｸｻﾑ
";
CM_ SG_ 1620 BIU654_7_4_KEYSW "ｷｰSW
";
CM_ SG_ 1620 BIU654_7_5_ALARM "ｱﾗｰﾑｼｽﾃﾑ情報
";
CM_ SG_ 1620 BIU654_7_6_RES_STOP_JPN "ｴﾝｽﾀ停止要求
";
CM_ SG_ 1620 BIU654_6_0_CONT_DATA_FOR_RES "RES用ｺﾏﾝﾄﾞ
";
CM_ SG_ 1620 BIU654_2_0_CODE_IMB_FOR_RES "Iﾃﾞｰﾀ
";
CM_ SG_ 1620 BIU654_1_0_MSG_COUNTER "ﾒｯｾｰｼﾞｶｳﾝﾀ
";
CM_ SG_ 1620 BIU654_0_0_CHECK_SUM "ﾁｪｯｸｻﾑ
";
CM_ SG_ 1618 BIU652_7_0_IND_SECURITY_IMB "ｾｷｭﾘﾃｨ(ｲﾓﾋﾞ)ｲﾝｼﾞｹｰﾀ表示
";
CM_ SG_ 1618 BIU652_6_0_OCCUPATION_3RDRH "3列目右乗員有無信号
";
CM_ SG_ 1618 BIU652_6_1_OCCUPATION_3RDCTR "3列目中央乗員有無信号
";
CM_ SG_ 1618 BIU652_6_2_OCCUPATION_3RDLH "3列目左乗員有無信号
";
CM_ SG_ 1618 BIU652_6_3_OCCUPATION_RRRH "後席右乗員有無信号
";
CM_ SG_ 1618 BIU652_6_4_OCCUPATION_RRCTR "後席中央乗員有無信号
";
CM_ SG_ 1618 BIU652_6_5_OCCUPATION_RRLH "後席左乗員有無信号
";
CM_ SG_ 1618 BIU652_6_6_HORNHAZARD_RES_SIG "ﾘﾓｰﾄﾎｰﾝ&ﾗｲﾄ応答信号
";
CM_ SG_ 1618 BIU652_6_7_OCCUPATION_DRVR "D席乗員有無信号
";
CM_ SG_ 1618 BIU652_5_0_STATUS_ROOMLAMP "ﾙｰﾑﾗﾝﾌﾟ状態
";
CM_ SG_ 1618 BIU652_5_3_HEADLAMP_SMALL "ﾍｯﾄﾞﾗﾝﾌﾟ　ｽﾓｰﾙ
";
CM_ SG_ 1618 BIU652_5_4_ALL_UNLOCK_STATE "全席ｱﾝﾛｯｸ出力状態
";
CM_ SG_ 1618 BIU652_5_5_DRVR_UNLOCK_STATE "運転席ｱﾝﾛｯｸ出力状態
";
CM_ SG_ 1618 BIU652_5_6_ALL_LOCK_STATE "全席ﾛｯｸ出力状態
";
CM_ SG_ 1618 BIU652_4_0_TRIG_LOCK_UNLOCK "ﾄﾞｱﾛｯｸ/ｱﾝﾛｯｸ出力要因信号
";
CM_ SG_ 1618 BIU652_3_0_DOOR_DRVR "ﾄﾞｱSW　D席
";
CM_ SG_ 1618 BIU652_3_1_DOOR_PASS "ﾄﾞｱSW　P席
";
CM_ SG_ 1618 BIU652_3_2_DOOR_RRRH "ﾄﾞｱSW　後席右
";
CM_ SG_ 1618 BIU652_3_3_DOOR_RRLH "ﾄﾞｱSW　後席左
";
CM_ SG_ 1618 BIU652_3_4_DOOR_RG "ﾄﾞｱSW　Rｹﾞｰﾄ
";
CM_ SG_ 1618 BIU652_3_5_DOOR_TR "ﾄﾞｱSW　ﾄﾗﾝｸ
";
CM_ SG_ 1618 BIU652_3_7_OPENSW_RG "ﾘﾔｹﾞｰﾄｵｰﾌﾟﾅSW信号
";
CM_ SG_ 1618 BIU652_2_0_LOCKSTATUS_DRVR "ﾄﾞｱﾛｯｸ状態信号（運席）
";
CM_ SG_ 1618 BIU652_2_1_LOCKSTATUS_PASS "ﾄﾞｱﾛｯｸ状態信号（助手席）
";
CM_ SG_ 1618 BIU652_2_2_LOCKSTATUS_RRRH "ﾄﾞｱﾛｯｸ状態信号（後席右）
";
CM_ SG_ 1618 BIU652_2_3_LOCKSTATUS_RRLH "ﾄﾞｱﾛｯｸ状態信号（後席左）
";
CM_ SG_ 1618 BIU652_2_4_LOCKSTATUS_RG "ﾄﾞｱﾛｯｸ状態信号（Rｹﾞｰﾄ）
";
CM_ SG_ 1618 BIU652_2_6_UNLOCK_DOORKEYSW "ﾄﾞｱｷｰSW　ｱﾝﾛｯｸ
";
CM_ SG_ 1618 BIU652_2_7_LOCK_DOORKEYSW "ﾄﾞｱｷｰSW ﾛｯｸ
";
CM_ SG_ 1618 BIU652_1_0_MSG_COUNTER "ﾒｯｾｰｼﾞｶｳﾝﾀ
";
CM_ SG_ 1618 BIU652_0_0_CHECK_SUM "ﾁｪｯｸｻﾑ
";
CM_ SG_ 1617 BIU651_7_0_PWPOS_RL "RL席窓位置
";
CM_ SG_ 1617 BIU651_7_2_PWPOS_RR "RR席窓位置
";
CM_ SG_ 1617 BIU651_7_4_PWPOS_PASS "P席窓位置
";
CM_ SG_ 1617 BIU651_7_6_PWPOS_DRVR "D席窓位置
";
CM_ SG_ 1617 BIU651_6_0_IND_ACTIVE_HBA "HBA作動灯
";
CM_ SG_ 1617 BIU651_6_2_ADB_ACTIVE "ADB有無ﾌﾗｸﾞ
";
CM_ SG_ 1617 BIU651_6_3_JUDGE_ILL "照度判定信号
";
CM_ SG_ 1617 BIU651_6_4_TYPE_LO_BEAM "Loﾋﾞｰﾑ光源種類
";
CM_ SG_ 1617 BIU651_6_6_TYPE_HI_BEAM "Hiﾋﾞｰﾑ光源種類
";
CM_ SG_ 1617 BIU651_5_0_SRF_ACTIVE "SRF有無ﾌﾗｸﾞ
";
CM_ SG_ 1617 BIU651_5_1_SRF_IND "SRF OFF ｲﾝｼﾞｹｰﾀ
";
CM_ SG_ 1617 BIU651_5_3_SRF_LAMP_LIGHT "SRF（右）点灯状態
";
CM_ SG_ 1617 BIU651_5_4_SRF_LAMP_LEFT "SRF（左）点灯状態
";
CM_ SG_ 1617 BIU651_5_5_MSG_STATUS_HBA "HBA文言表示
";
CM_ SG_ 1617 BIU651_5_7_IND_FAIL_HBA "HBAﾌｪｰﾙ灯
";
CM_ SG_ 1617 BIU651_4_0_BUZ_PATTERN "ﾌﾞｻﾞｰ吹鳴ﾊﾟﾀｰﾝ情報
";
CM_ SG_ 1617 BIU651_4_4_CSTM_OPE_ALARM "ｾｷｭﾘﾃｨｱﾗｰﾑ　ｶｽﾀﾏｲｽﾞ
";
CM_ SG_ 1617 BIU651_4_6_CSTM_HBA "HBA（ﾐﾗｰ/ｱｲｻｲﾄ）有無ﾌﾗｸﾞ
";
CM_ SG_ 1617 BIU651_3_0_HEADLAMP_PASS_SW "ﾍｯﾄﾞﾗﾝﾌﾟ　PASSｽｲｯﾁ
";
CM_ SG_ 1617 BIU651_3_1_HEADLAMP_AUTO_SW "ﾍｯﾄﾞﾗﾝﾌﾟ　AUTOｽｲｯﾁ
";
CM_ SG_ 1617 BIU651_3_2_JUDGE_DOOR_LOCK "室内照明制御用ﾄﾞｱﾛｯｸ判定ﾌﾗｸﾞ
";
CM_ SG_ 1617 BIU651_3_3_JUDGE_DOOR_UNLOCK "室内照明制御用ﾄﾞｱｱﾝﾛｯｸ判定
";
CM_ SG_ 1617 BIU651_3_4_HEADLAMP_Lo_SW "ﾍｯﾄﾞﾗﾝﾌﾟ　Loｽｲｯﾁ
";
CM_ SG_ 1617 BIU651_3_5_HEADLAMP_HI_SW "ﾍｯﾄﾞﾗﾝﾌﾟ　Hiｽｲｯﾁ
";
CM_ SG_ 1617 BIU651_3_6_WIPER_AUTO_SW "ﾜｲﾊﾟｰ AUTO SW
";
CM_ SG_ 1617 BIU651_3_7_PRG_LIN_MEMORY_ON_OFF "PRG LIN通信用 メモリ機能 ON/OFF状態
";
CM_ SG_ 1617 BIU651_2_0_CSTM_ILLUMI_SSR "照度ｾﾝｻ有無ﾌﾗｸﾞ
";
CM_ SG_ 1617 BIU651_2_1_HANDLE "ﾊﾝﾄﾞﾙ情報
";
CM_ SG_ 1617 BIU651_2_2_CSTM_SMT "ｽﾏｰﾄ有無
";
CM_ SG_ 1617 BIU651_2_3_AJARDOOR_STATUS "半ﾄﾞｱ判定結果
";
CM_ SG_ 1617 BIU651_2_4_ONETOUCH_LAMP_OUT "ﾜﾝﾀｯﾁ全照明出力
";
CM_ SG_ 1617 BIU651_2_5_PRG_FAIL_FLAG "PRG通信異常フラグ
";
CM_ SG_ 1617 BIU651_2_6_CSTM_PSMECU "ｼｰﾄﾒﾓﾘ有無ﾌﾗｸﾞ
";
CM_ SG_ 1617 BIU651_2_7_STATE_REGIST_DEL "ﾒﾓﾘ登録/消去状態ﾌﾗｸﾞ
";
CM_ SG_ 1617 BIU651_1_0_MSG_COUNTER "ﾒｯｾｰｼﾞｶｳﾝﾀ
";
CM_ SG_ 1617 BIU651_1_4_SRPOS "サンルーフガラス位置
";
CM_ SG_ 1617 BIU651_1_7_WIPER_INT_STATUS "Fﾜｲﾊﾟ間欠作動状態
";
CM_ SG_ 1617 BIU651_0_0_CHECK_SUM "ﾁｪｯｸｻﾑ
";
CM_ SG_ 940 BIU3AC_7_0_HEADLAMP_SMALL "ﾍｯﾄﾞﾗﾝﾌﾟ　ｽﾓｰﾙ
";
CM_ SG_ 940 BIU3AC_7_1_HEADLAMP_LO_REQ "ﾗｲﾃｨﾝｸﾞLo出力要求
";
CM_ SG_ 940 BIU3AC_7_2_HEADLAMP_HI_REQ "ﾗｲﾃｨﾝｸﾞHi出力要求
";
CM_ SG_ 940 BIU3AC_7_3_FT_FOG_RELAY_REQ "Fﾌｫｸﾞﾗﾝﾌﾟﾘﾚｰ出力要求
";
CM_ SG_ 940 BIU3AC_7_4_FOGLAMP_RR "ﾘｱﾌｫｸﾞﾗﾝﾌﾟ
";
CM_ SG_ 940 BIU3AC_7_5_DRL "DRL出力信号
";
CM_ SG_ 940 BIU3AC_7_6_WIPER_FRONT "FTﾜｲﾊﾟ(RTN)
";
CM_ SG_ 940 BIU3AC_7_7_RDEF_RELAY_REQ "ﾘｱﾃﾞﾌｫｯｶﾞ出力要求
";
CM_ SG_ 940 BIU3AC_6_0_RDEFOGSW "ﾘｱﾃﾞﾌｫｯｶﾞSW状態
";
CM_ SG_ 940 BIU3AC_6_1_CSTM_PRG "ﾊﾟﾜｰﾘｱｹﾞｰﾄ有無ﾌﾗｸﾞ
";
CM_ SG_ 940 BIU3AC_6_2_FAIL_SHIFTLOCKSOL "ｼﾌﾄﾛｯｸｿﾚﾉｲﾄﾞ異常
";
CM_ SG_ 940 BIU3AC_6_3_REQ_CANCEL_ISS "ISSｷｬﾝｾﾙ要求
";
CM_ SG_ 940 BIU3AC_6_4_REVERSE_MT "MTﾘﾊﾞｰｽSW
";
CM_ SG_ 940 BIU3AC_6_5_HANDBRAKE "ﾊﾟｰｷﾝｸﾞﾌﾞﾚｰｷSW
";
CM_ SG_ 940 BIU3AC_6_6_BRAKELAMPSW "ﾌﾞﾚｰｷﾗﾝﾌﾟSW
";
CM_ SG_ 940 BIU3AC_6_7_TOWING_SW "ﾄｰｲﾝｸﾞSW
";
CM_ SG_ 940 BIU3AC_5_0_LANE_OFF_SW "LANE OFFｽｲｯﾁ
";
CM_ SG_ 940 BIU3AC_5_2_PCR_OFF_SW "P-CR　OFFｽｲｯﾁ
";
CM_ SG_ 940 BIU3AC_5_4_DIMMER_CANCEL "ﾃﾞｨﾏｰｷｬﾝｾﾙ信号
";
CM_ SG_ 940 BIU3AC_5_5_KEYSW "ｷｰSW
";
CM_ SG_ 940 BIU3AC_5_6_IND_ND_SHIFTLOCK "N-Dｼﾌﾄﾛｯｸ用ﾌﾞﾚｰｷ押下表示有無
";
CM_ SG_ 940 BIU3AC_4_0_DOOR_DRVR "ﾄﾞｱSW　D席
";
CM_ SG_ 940 BIU3AC_4_1_DOOR_PASS "ﾄﾞｱSW　P席
";
CM_ SG_ 940 BIU3AC_4_2_DOOR_RRRH "ﾄﾞｱSW　後席右
";
CM_ SG_ 940 BIU3AC_4_3_DOOR_RRLH "ﾄﾞｱSW　後席左
";
CM_ SG_ 940 BIU3AC_4_4_DOOR_RG "ﾄﾞｱSW　Rｹﾞｰﾄ
";
CM_ SG_ 940 BIU3AC_4_5_DOOR_TR "ﾄﾞｱSW　ﾄﾗﾝｸ
";
CM_ SG_ 940 BIU3AC_4_6_HOOD_CLOSE "ﾌｰﾄﾞSW　閉側
";
CM_ SG_ 940 BIU3AC_4_7_HOOD_OPEN "ﾌｰﾄﾞＳＷ　開側
";
CM_ SG_ 940 BIU3AC_3_0_GW_STSW_RES "RESからのSTSWﾃﾞｰﾀ
";
CM_ SG_ 940 BIU3AC_3_1_GW_POWER_RES "SMTからのﾘﾓｽﾀ電源ONﾃﾞｰﾀ
";
CM_ SG_ 940 BIU3AC_3_3_ST1 "STﾌﾗｸﾞ1
";
CM_ SG_ 940 BIU3AC_3_4_ST2 "STﾌﾗｸﾞ2
";
CM_ SG_ 940 BIU3AC_3_5_ACC "ACC
";
CM_ SG_ 940 BIU3AC_3_6_IGA "IG-a
";
CM_ SG_ 940 BIU3AC_3_7_BAT_BACKUP "B/up
";
CM_ SG_ 940 BIU3AC_2_0_CSTM_AC "A/C　ＣＡＮ接続有無ﾌﾗｸﾞ
";
CM_ SG_ 940 BIU3AC_2_1_IMB_SMT "IM/SMT判別情報
";
CM_ SG_ 940 BIU3AC_2_3_CSTM_WGN_SDN "WGN/SDN判別ﾌﾗｸﾞ
";
CM_ SG_ 940 BIU3AC_2_4_VAL_SEAT_BACK_CTSM "ｼｰﾄ現在設定値
";
CM_ SG_ 940 BIU3AC_2_5_VAL_MIR_AFOLD_CTSM "ﾐﾗｰ電格設定値
";
CM_ SG_ 940 BIU3AC_2_6_VAL_MIR_RTILT_CTSM "R連動ﾐﾗｰ設定値
";
CM_ SG_ 940 BIU3AC_2_7_WIPER_REAR "RRﾜｲﾊﾟ(RTN)
";
CM_ SG_ 940 BIU3AC_1_0_MSG_COUNTER "ﾒｯｾｰｼﾞｶｳﾝﾀ
";
CM_ SG_ 940 BIU3AC_1_4_PADDLESHIFT_DOWN_SW "ﾊﾟﾄﾞﾙｼﾌﾄﾀﾞｳﾝSW
";
CM_ SG_ 940 BIU3AC_1_5_PADDLESHIFT_UP_SW "ﾊﾟﾄﾞﾙｼﾌﾄｱｯﾌﾟSW
";
CM_ SG_ 940 BIU3AC_1_6_MANUALMODE_SW "ﾏﾆｭｱﾙﾓｰﾄﾞSW
";
CM_ SG_ 940 BIU3AC_0_0_CHECK_SUM "ﾁｪｯｸｻﾑ
";
CM_ SG_ 1616 BIU650_7_0_Reserved "ワイパーサービスモードSW操作禁止フラグ
";
CM_ SG_ 1616 BIU650_7_1_Reserved "ワイパーサービスモード有無フラグ
";
CM_ SG_ 1616 BIU650_7_2_Reserved "ワイパーサービスモード状態
";
CM_ SG_ 1616 BIU650_7_3_DOOR_LINK_SW_STS "室内灯DOOR連動SW状態
";
CM_ SG_ 1616 BIU650_7_4_Reserved "ウィンドウロックSW信号
";
CM_ SG_ 1616 BIU650_6_0_Reserved "オートライト感度調整設定値
";
CM_ SG_ 1616 BIU650_6_3_RR_WIPER_STATUS "Ｒワイパ駆動状態
";
CM_ SG_ 1616 BIU650_6_5_WIPER_SENSITIVITY_CTM "ワイパ感度設定
";
CM_ SG_ 1616 BIU650_5_0_Reserved "ﾄﾞｱSW運転席信号
";
CM_ SG_ 1616 BIU650_5_1_Reserved "全ﾄﾞｱ開閉変化ｲﾍﾞﾝﾄ判定
";
CM_ SG_ 1616 BIU650_5_2_FMH_DOOR_LOCK "フォローミーホームドアロック判定
";
CM_ SG_ 1616 BIU650_5_4_LMH_DOOR_LOCK "リードミーホームドアロック判定
";
CM_ SG_ 1616 BIU650_4_0_REQ_OPE_AUTOLIGHT "オートライト点灯/消灯要求
";
CM_ SG_ 1616 BIU650_4_2_STATE_SHINSSR "ライトセンサステータス
";
CM_ SG_ 1616 BIU650_4_4_STATE_RLS_FAIL "RLS異常状態
";
CM_ SG_ 1616 BIU650_3_0_REQ_FWASHER_ITLOCK "F ウォッシャ連動要求
";
CM_ SG_ 1616 BIU650_3_1_FWIPER_RTN "F ワイパ（RTN)補正
";
CM_ SG_ 1616 BIU650_3_2_TURN_LAMP_STATE_LEFT "左ターンランプ状態
";
CM_ SG_ 1616 BIU650_3_3_TURN_LAMP_STATE_RIGHT "右ターンランプ状態
";
CM_ SG_ 1616 BIU650_3_4_Reserved "RES操作ﾗｲﾃｨﾝｸﾞ1出力要求
";
CM_ SG_ 1616 BIU650_2_0_HEADLAMP_SMALL_SW "ライティング1SW信号
";
CM_ SG_ 1616 BIU650_2_1_HEADLAMP_LO_SW "ライティング2SW信号
";
CM_ SG_ 1616 BIU650_2_2_HEADLAMP_OFF_SW "ライティングOFF SW信号
";
CM_ SG_ 1616 BIU650_2_3_HEADLAMP_Hi_SW "ディマーHi SW 信号
";
CM_ SG_ 1616 BIU650_2_4_HEAD_LAMP_PASS_SW "ディマーPass SW 信号
";
CM_ SG_ 1616 BIU650_2_5_FFOG_SW "FフォグランプSW信号
";
CM_ SG_ 1616 BIU650_2_6_RFOG_SW "RフォグランプSW信号
";
CM_ SG_ 1616 BIU650_1_0_MSG_COUNTER "メッセージカウンタ
";
CM_ SG_ 1616 BIU650_0_0_CHECK_SUM "チェックサム
";
CM_ SG_ 280 EPS118_7_0_IND_FAIL_MULTI "ﾌｪｰﾙﾗﾝﾌﾟ駆動(ﾏﾙﾁ用)
";
CM_ SG_ 280 EPS118_7_3_UNDER_BACKUP_CTRL "故障時バックアップ制御中フラグ
";
CM_ SG_ 280 EPS118_7_4_HANDSFREE_PERMIT_FLAG "ハンズフリー許可フラグ
";
CM_ SG_ 280 EPS118_7_5_PROHIBIT_CONT_ISS "ISS協調制御禁止ﾌﾗｸﾞ
";
CM_ SG_ 280 EPS118_7_6_LVL_ASSIST "ｱｼｽﾄ作動状態ﾌﾗｸﾞ
";
CM_ SG_ 280 EPS118_6_0_TRQ_SEN_MAIN_SIG "ﾄﾙｸｾﾝｻﾒｲﾝ信号
";
CM_ SG_ 280 EPS118_5_0_ECU_TEMP "ECU内部温度
";
CM_ SG_ 280 EPS118_3_0_CURRENT_MOTOR "ﾓｰﾀ作動電流
";
CM_ SG_ 280 EPS118_1_0_MSG_COUNTER "ﾒｯｾｰｼﾞｶｳﾝﾀ
";
CM_ SG_ 280 EPS118_1_4_FAIL_EPS "EPSｼｽﾃﾑﾌｪｰﾙ
";
CM_ SG_ 280 EPS118_1_5_TARGET_CURRENT "最終目標電流値
";
CM_ SG_ 280 EPS118_0_0_CHECK_SUM "ﾁｪｯｸｻﾑ
";
CM_ SG_ 859 DAM35B_7_0_VERTICAL_ACCELERATION "上下加速度
";
CM_ SG_ 859 DAM35B_6_0_ROLL_SPEED "ロール
";
CM_ SG_ 859 DAM35B_5_0_PITCH_SPEED "ピッチ
";
CM_ SG_ 859 DAM35B_4_0_EYE_CONTROL_FLAG "EYEコントロールフラグ
";
CM_ SG_ 859 DAM35B_3_0_WARNING_LAMP "警告灯
";
CM_ SG_ 859 DAM35B_3_2_DAMPER_MODE "ダンパーモード
";
CM_ SG_ 859 DAM35B_3_5_FAIL_FLAG_FOR_CCU "CCU向けフェールフラグ
";
CM_ SG_ 859 DAM35B_3_6_FAIL_FLAG_DAMPER "ダンパーフェールフラグ
";
CM_ SG_ 859 DAM35B_1_0_MSG_COUNTER "メッセージカウンタ
";
CM_ SG_ 859 DAM35B_0_0_CHECK_SUM "チェックサム
";
CM_ SG_ 811 EPB32B_7_0_AVH_TARGET_PRESS "AVH目標保持圧
";
CM_ SG_ 811 EPB32B_6_0_VEHICLE_RUN_STOP_FLG "車両走行停止判定ﾌﾗｸﾞ
";
CM_ SG_ 811 EPB32B_6_2_REQ_HILL_P_CAUTION "坂道駐車警告表示要求
";
CM_ SG_ 811 EPB32B_5_0_FLG_AVH_OILPRES_EPB "AVH制御ﾌﾗｸﾞ(液圧/EPB)
";
CM_ SG_ 811 EPB32B_5_1_FLG_AVH "AVH作動ﾌﾗｸﾞ
";
CM_ SG_ 811 EPB32B_5_2_AVH_INTENSIFY_PRES "ISS中AVH中増圧ﾌﾗｸﾞ
";
CM_ SG_ 811 EPB32B_5_3_BREAK_IND "ﾌﾞﾚｰｷ踏み指示
";
CM_ SG_ 811 EPB32B_5_5_AVH_ON_LAMP "AVH_ON灯
";
CM_ SG_ 811 EPB32B_5_6_AVH_FUNC_ON_LUMP "AVH 作動灯
";
CM_ SG_ 811 EPB32B_5_7_AVH_ACTIVE "AVH有無ﾌﾗｸﾞ
";
CM_ SG_ 811 EPB32B_4_0_BUZZER "ﾌﾞｻﾞｰ
";
CM_ SG_ 811 EPB32B_4_2_HILL_HOLD_ON_LAMP "ﾋﾙﾎｰﾙﾄﾞ機能ONﾗﾝﾌﾟ
";
CM_ SG_ 811 EPB32B_4_3_CLAMP_LAMP "EPB作動灯
";
CM_ SG_ 811 EPB32B_4_5_WARN_LAMP "EPB警告灯
";
CM_ SG_ 811 EPB32B_4_7_WARN_EPB_MET_LCD "ﾒｰﾀ内液晶用EPB警告灯
";
CM_ SG_ 811 EPB32B_3_0_STATUS_EPB "EPB作動状態
";
CM_ SG_ 811 EPB32B_3_3_DYNAMIC_PARKING "動的ﾊﾟｰｷﾝｸﾞﾌﾗｸﾞ
";
CM_ SG_ 811 EPB32B_3_4_HILL_HOLD_RUN_FLG "ﾋﾙﾎｰﾙﾄﾞ作動ﾌﾗｸﾞ
";
CM_ SG_ 811 EPB32B_3_5_INHIBIT_ISS_DELAY "ISS作動禁止要求ﾌﾗｸﾞ(判定ﾃﾞｨﾚｲ有り)
";
CM_ SG_ 811 EPB32B_3_6_INHIBIT_ISS "ISS作動禁止要求ﾌﾗｸﾞ(判定ﾃﾞｨﾚｲ無し)
";
CM_ SG_ 811 EPB32B_3_7_AVH_PERMIT_CONT_ACC "AVH-ACC協調許可フラグ
";
CM_ SG_ 811 EPB32B_2_0_ERR_INFO "EPBｴﾗｰ情報
";
CM_ SG_ 811 EPB32B_2_2_EPB_FAIL_FLG1 "EPBﾌｪｰﾙﾌﾗｸﾞ1
";
CM_ SG_ 811 EPB32B_2_3_EPB_FAIL_FLG2 "EPBﾌｪｰﾙﾌﾗｸﾞ2
";
CM_ SG_ 811 EPB32B_2_4_EPB_FAIL_FLG3 "EPBﾌｪｰﾙﾌﾗｸﾞ3
";
CM_ SG_ 811 EPB32B_1_0_MSG_COUNTER "ﾒｯｾｰｼﾞｶｳﾝﾀ
";
CM_ SG_ 811 EPB32B_1_4_WAKE_UP_FRAME "ｳｪｲｸｱｯﾌﾟﾌﾚｰﾑ識別ﾌﾗｸﾞ
";
CM_ SG_ 811 EPB32B_1_5_REQ_COMM_CONT "通信継続要求ﾌﾗｸﾞ
";
CM_ SG_ 811 EPB32B_1_6 "予約:通信継続要求ﾌﾗｸﾞ(拡張)
";
CM_ SG_ 811 EPB32B_0_0_CHECK_SUM "ﾁｪｯｸｻﾑ
";
CM_ SG_ 313 VDC139_7_4_FAIL_PRESSURE_SSR "圧力ｾﾝｻ故障ﾌﾗｸﾞ
";
CM_ SG_ 313 VDC139_7_5_STATUS_EPB "EPB作動状態
";
CM_ SG_ 313 VDC139_6_0_SSR_N_PRESS "負圧ｾﾝｻ値
";
CM_ SG_ 313 VDC139_5_0_PRESSURE_BRAKE "ﾌﾞﾚｰｷ圧力
";
CM_ SG_ 313 VDC139_4_0_HDC_STATUS "HDC状態信号
";
CM_ SG_ 313 VDC139_4_2_BRAKELAMPSW "BLS信号
";
CM_ SG_ 313 VDC139_4_3_FAIL_BRAKELAMPSW "BLS故障信号
";
CM_ SG_ 313 VDC139_4_4_ACTIVATE_ABS "ABS作動ﾌﾗｸﾞ
";
CM_ SG_ 313 VDC139_4_5_ACTIVATE_TCS "TCS作動ﾌﾗｸﾞ
";
CM_ SG_ 313 VDC139_4_6_CONT_OVER_STR "VDCｵｰﾊﾞｰ制御ﾌﾗｸﾞ
";
CM_ SG_ 313 VDC139_4_7_CONT_UNDER_STR "VDCｱﾝﾀﾞｰ制御ﾌﾗｸﾞ
";
CM_ SG_ 313 VDC139_3_5_FAIL_VDC_SSR "VDCｾﾝｻﾌｪｰﾙﾌﾗｸﾞ
";
CM_ SG_ 313 VDC139_3_6_FAIL_SPD_SSR_FHI "ｽﾋﾟｰﾄﾞｾﾝｻﾌｪｰﾙﾌﾗｸﾞ（FHI）
";
CM_ SG_ 313 VDC139_3_7_FAIL_ABS_SYS "ABSｼｽﾃﾑﾌｪｰﾙﾌﾗｸﾞ
";
CM_ SG_ 313 VDC139_2_0_SPD_WHEEL_AVE "駆動輪軸平均車輪速（VSO）
";
CM_ SG_ 313 VDC139_1_0_MSG_COUNTER "ﾒｯｾｰｼﾞｶｳﾝﾀ
";
CM_ SG_ 313 VDC139_1_4_FAIL_HDC_SYS "HDCｼｽﾃﾑﾌｪｰﾙﾌﾗｸﾞ
";
CM_ SG_ 313 VDC139_1_5_VEHICLE_HIGHT "車高情報
";
CM_ SG_ 313 VDC139_1_7_REPROGRAMING "CAN診断・送信停止
";
CM_ SG_ 313 VDC139_0_0_CHECK_SUM "ﾁｪｯｸｻﾑ
";
CM_ SG_ 312 VDC138_7_0_PRESSURE_WC_FTLH "FL W/C実液圧
";
CM_ SG_ 312 VDC138_6_0_PRESSURE_WC_FTRH "FR W/C実液圧
";
CM_ SG_ 312 VDC138_4_0_YAW_RATE "ﾖｰﾚｰﾄ
";
CM_ SG_ 312 VDC138_2_0_STEER_ANGLE "舵角ｾﾝｻ
";
CM_ SG_ 312 VDC138_1_0_MSG_COUNTER "ﾒｯｾｰｼﾞｶｳﾝﾀ
";
CM_ SG_ 312 VDC138_1_4_ACTIVE_LDP "LDP作動ﾌﾗｸﾞ
";
CM_ SG_ 312 VDC138_1_5_PROHIBIT_LDP "LDP禁止ﾌﾗｸﾞ
";
CM_ SG_ 312 VDC138_1_6_VDC_SMALL_MARGIN "VDC介入余裕小ﾌﾗｸﾞ
";
CM_ SG_ 312 VDC138_1_7_DETECT_REAR_SLIP "ﾘｱｽﾘｯﾌﾟ検出ﾌﾗｸﾞ
";
CM_ SG_ 312 VDC138_0_0_CHECK_SUM "ﾁｪｯｸｻﾑ
";
CM_ SG_ 1712 CCU6B0_7_0_AIL_CSTM_PRS_REQ "AIL CUSTOMプリセット要求
";
CM_ SG_ 1712 CCU6B0_7_1_AIL_RENDER_REQ "AIL 演出変更要求
";
CM_ SG_ 1712 CCU6B0_6_0_AIL_FIRST_BRIGHT_REQ "AIL 第1照明_輝度変更要求
";
CM_ SG_ 1712 CCU6B0_6_4_AIL_SECOND_BRIGHT_REQ "AIL 第2照明_輝度変更要求
";
CM_ SG_ 1712 CCU6B0_5_0_AIL_SECOND_COLOR_REQ "AIL 第2照明_カラー変更要求
";
CM_ SG_ 1712 CCU6B0_4_0_AIL_FIRST_COLOR_REQ "AIL 第1照明_カラー変更要求
";
CM_ SG_ 1712 CCU6B0_3_0_AIL_ADAS_VEH_DIS_REQ "AIL ADAS_車間距離連動変更要求
";
CM_ SG_ 1712 CCU6B0_3_1_AIL_ADAS_LANE_DEV_REQ "AIL ADAS_車線逸脱連動変更要求
";
CM_ SG_ 1712 CCU6B0_3_2_AIL_ADAS_FT_CROSS_REQ "AIL ADAS_前側方飛び出し連動変更要求
";
CM_ SG_ 1712 CCU6B0_3_3_AIL_ADAS_HANDS_FR_REQ "AIL ADAS_ハンズフリー切り替え連動変更要求
";
CM_ SG_ 1712 CCU6B0_2_0_AIL_WEL_FOL_REQ "AIL ｳｴﾙｶﾑﾌｫﾛｰﾐｰ連動変更要求
";
CM_ SG_ 1712 CCU6B0_2_1_AIL_ADAS_EXP_REQ "AIL ADAS連動変更要求
";
CM_ SG_ 1712 CCU6B0_2_2_AIL_NOTIFI_EXP_REQ "AILおしらせ連動変更要求
";
CM_ SG_ 1712 CCU6B0_2_3_AIL_AIR_CON_EXP_REQ "AIL 空調連動変更要求
";
CM_ SG_ 1712 CCU6B0_1_0_MSG_COUNTER "メッセージカウンタ
";
CM_ SG_ 1712 CCU6B0_1_4_AIL_CUSTOM_REQ "AIL カスタマイズ変更要求
";
CM_ SG_ 1712 CCU6B0_1_5_AIL_CUSTOM_RESET_REQ "AIL カスタマイズリセット変更要求
";
CM_ SG_ 1712 CCU6B0_1_6_AIL_ON_OFF_REQ "AIL ON/OFF変更要求
";
CM_ SG_ 1712 CCU6B0_0_0_CHECK_SUM "チェックサム
";
CM_ SG_ 1665 CECU681_6_7_DP_CHANGE_SET_REQ "ドライバプロファイル設定変更要求フラグ
";
CM_ SG_ 1665 CECU681_6_4_SMT_LINK "スマート紐づけ
";
CM_ SG_ 1665 CECU681_6_3_IPMS_LINK "IPMS紐づけ
";
CM_ SG_ 1665 CECU681_5_6_DP_DKYMEM_LIST_NO15 "DriverProfileデジキー登録リストNo15
";
CM_ SG_ 1665 CECU681_5_5_DP_DKYMEM_LIST_NO14 "DriverProfileデジキー登録リストNo14
";
CM_ SG_ 1665 CECU681_5_4_DP_DKYMEM_LIST_NO13 "DriverProfileデジキー登録リストNo13
";
CM_ SG_ 1665 CECU681_5_3_DP_DKYMEM_LIST_NO12 "DriverProfileデジキー登録リストNo12
";
CM_ SG_ 1665 CECU681_5_2_DP_DKYMEM_LIST_NO11 "DriverProfileデジキー登録リストNo11
";
CM_ SG_ 1665 CECU681_5_1_DP_DKYMEM_LIST_NO10 "DriverProfileデジキー登録リストNo10
";
CM_ SG_ 1665 CECU681_5_0_DP_DKYMEM_LIST_NO9 "DriverProfileデジキー登録リストNo9
";
CM_ SG_ 1665 CECU681_4_7_DP_DKYMEM_LIST_NO8 "DriverProfileデジキー登録リストNo8
";
CM_ SG_ 1665 CECU681_4_6_DP_DKYMEM_LIST_NO7 "DriverProfileデジキー登録リストNo7
";
CM_ SG_ 1665 CECU681_4_5_DP_DKYMEM_LIST_NO6 "DriverProfileデジキー登録リストNo6
";
CM_ SG_ 1665 CECU681_4_4_DP_DKYMEM_LIST_NO5 "DriverProfileデジキー登録リストNo5
";
CM_ SG_ 1665 CECU681_4_3_DP_DKYMEM_LIST_NO4 "DriverProfileデジキー登録リストNo4
";
CM_ SG_ 1665 CECU681_4_2_DP_DKYMEM_LIST_NO3 "DriverProfileデジキー登録リストNo3
";
CM_ SG_ 1665 CECU681_4_1_DP_DKYMEM_LIST_NO2 "DriverProfileデジキー登録リストNo2
";
CM_ SG_ 1665 CECU681_4_0_DP_DKYMEM_LIST_NO1 "DriverProfileデジキー登録リストNo1
";
CM_ SG_ 1665 CECU681_3_5_RECOG_FACTOR "識別要因信号
";
CM_ SG_ 1665 CECU681_3_4_RECOG_USER_VALIDFRAG "識別ユーザ有効フラグ
";
CM_ SG_ 1665 CECU681_3_0_RESULT_NOTICE_REQ "処理結果表示要求
";
CM_ SG_ 1665 CECU681_2_4_RECOG_USER_NO "識別ユーザNo.
";
CM_ SG_ 1665 CECU681_2_0_POPUP_NOTICE_NO "ポップアップ表示ユーザNo.
";
CM_ SG_ 1665 CECU681_1_7_DP_FAILE_FRAG "DPフェールフラグ
";
CM_ SG_ 1665 CECU681_1_5_DP_PROCESS_RESULT "DP処理結果
";
CM_ SG_ 1665 CECU681_1_4_POPUP_NOTICE_REQ "ポップアップ表示要求
";
CM_ SG_ 1665 CECU681_1_0_MSG_COUNTER "メッセージカウンタ
";
CM_ SG_ 1665 CECU681_0_0_CHECK_SUM "ﾁｪｯｸｻﾑ
";
BA_DEF_ SG_  "Fhi_SignalComment" STRING ;
BA_DEF_ SG_  "GenSigInactiveValue" INT 0 10000;
BA_DEF_ SG_  "GenSigStartValue" FLOAT 0 100000000000;
BA_DEF_ SG_  "GenSigSendType" ENUM  "Cyclic","OnWrite","OnWriteWithRepetition","OnChange","OnChangeWithRepetition","IfActive","IfActiveWithRepetition","NoSigSendType";
BA_DEF_ BO_  "MsgRoutingId" STRING ;
BA_DEF_ BO_  "DiagResponse" ENUM  "No","Yes";
BA_DEF_ BO_  "DiagRequest" ENUM  "No","Yes";
BA_DEF_ BO_  "DiagState" ENUM  "No","Yes";
BA_DEF_ BO_  "GenMsgILSupport" ENUM  "No","Yes";
BA_DEF_ BO_  "GenMsgNrOfRepetition" INT 0 999999;
BA_DEF_ BO_  "GenMsgDelayTime" INT 0 1000;
BA_DEF_ BO_  "GenMsgCycleTimeFast" INT 0 10000;
BA_DEF_ BO_  "GenMsgCycleTime" INT 0 10000;
BA_DEF_ BO_  "GenMsgSendType" ENUM  "Cyclic","NotUsed","NotUsed","NotUsed","NotUsed","Cyclic","NotUsed","IfActive","NoMsgSendType";
BA_DEF_DEF_  "Fhi_SignalComment" "";
BA_DEF_DEF_  "GenSigInactiveValue" 0;
BA_DEF_DEF_  "GenSigStartValue" 0;
BA_DEF_DEF_  "GenSigSendType" "NoSigSendType";
BA_DEF_DEF_  "MsgRoutingId" "";
BA_DEF_DEF_  "DiagResponse" "No";
BA_DEF_DEF_  "DiagRequest" "No";
BA_DEF_DEF_  "DiagState" "No";
BA_DEF_DEF_  "GenMsgILSupport" "Yes";
BA_DEF_DEF_  "GenMsgNrOfRepetition" 0;
BA_DEF_DEF_  "GenMsgDelayTime" 0;
BA_DEF_DEF_  "GenMsgCycleTimeFast" 0;
BA_DEF_DEF_  "GenMsgCycleTime" 0;
BA_DEF_DEF_  "GenMsgSendType" "Cyclic";
BA_ "GenMsgCycleTime" BO_ 937 100;
BA_ "GenMsgDelayTime" BO_ 937 10;
BA_ "GenMsgCycleTimeFast" BO_ 937 50;
BA_ "GenMsgNrOfRepetition" BO_ 937 4;
BA_ "MsgRoutingId" BO_ 937 "102 ";
BA_ "GenMsgILSupport" BO_ 937 0;
BA_ "GenMsgCycleTime" BO_ 1614 1200;
BA_ "GenMsgDelayTime" BO_ 1614 10;
BA_ "GenMsgCycleTimeFast" BO_ 1614 50;
BA_ "MsgRoutingId" BO_ 1614 "96 ";
BA_ "GenMsgILSupport" BO_ 1614 0;
BA_ "GenMsgCycleTime" BO_ 826 120;
BA_ "GenMsgDelayTime" BO_ 826 10;
BA_ "GenMsgCycleTimeFast" BO_ 826 120;
BA_ "GenMsgNrOfRepetition" BO_ 826 50;
BA_ "MsgRoutingId" BO_ 826 "92 ";
BA_ "GenMsgILSupport" BO_ 826 0;
BA_ "GenMsgCycleTime" BO_ 961 120;
BA_ "GenMsgCycleTimeFast" BO_ 961 50;
BA_ "GenMsgNrOfRepetition" BO_ 961 3;
BA_ "MsgRoutingId" BO_ 961 "91 ";
BA_ "GenMsgILSupport" BO_ 961 0;
BA_ "GenMsgCycleTime" BO_ 1651 1200;
BA_ "GenMsgDelayTime" BO_ 1651 10;
BA_ "GenMsgCycleTimeFast" BO_ 1651 20;
BA_ "GenMsgNrOfRepetition" BO_ 1651 3;
BA_ "MsgRoutingId" BO_ 1651 "89 ";
BA_ "GenMsgILSupport" BO_ 1651 0;
BA_ "GenMsgCycleTime" BO_ 1650 1200;
BA_ "GenMsgDelayTime" BO_ 1650 10;
BA_ "GenMsgCycleTimeFast" BO_ 1650 20;
BA_ "GenMsgNrOfRepetition" BO_ 1650 3;
BA_ "MsgRoutingId" BO_ 1650 "88 ";
BA_ "GenMsgILSupport" BO_ 1650 0;
BA_ "GenMsgCycleTime" BO_ 722 30;
BA_ "MsgRoutingId" BO_ 722 "87 ";
BA_ "GenMsgILSupport" BO_ 722 0;
BA_ "GenMsgDelayTime" BO_ 1722 10;
BA_ "GenMsgSendType" BO_ 1722 8;
BA_ "GenMsgCycleTimeFast" BO_ 1722 20;
BA_ "GenMsgNrOfRepetition" BO_ 1722 3;
BA_ "MsgRoutingId" BO_ 1722 "71 ";
BA_ "GenMsgILSupport" BO_ 1722 0;
BA_ "GenMsgCycleTime" BO_ 1019 500;
BA_ "GenMsgDelayTime" BO_ 1019 10;
BA_ "GenMsgCycleTimeFast" BO_ 1019 20;
BA_ "GenMsgNrOfRepetition" BO_ 1019 3;
BA_ "MsgRoutingId" BO_ 1019 "69 ";
BA_ "GenMsgILSupport" BO_ 1019 0;
BA_ "GenMsgCycleTime" BO_ 1366 1000;
BA_ "GenMsgDelayTime" BO_ 1767 10;
BA_ "GenMsgSendType" BO_ 1767 8;
BA_ "GenMsgCycleTimeFast" BO_ 1767 20;
BA_ "GenMsgNrOfRepetition" BO_ 1767 1;
BA_ "MsgRoutingId" BO_ 1767 "68 ";
BA_ "GenMsgCycleTime" BO_ 1765 1200;
BA_ "GenMsgDelayTime" BO_ 1765 10;
BA_ "MsgRoutingId" BO_ 1765 "67 ";
BA_ "GenMsgCycleTime" BO_ 1696 1200;
BA_ "GenMsgDelayTime" BO_ 1696 10;
BA_ "GenMsgCycleTimeFast" BO_ 1696 50;
BA_ "GenMsgNrOfRepetition" BO_ 1696 2;
BA_ "MsgRoutingId" BO_ 1696 "66 ";
BA_ "GenMsgCycleTime" BO_ 1314 1000;
BA_ "GenMsgCycleTime" BO_ 1635 1000;
BA_ "MsgRoutingId" BO_ 1635 "65 ";
BA_ "GenMsgILSupport" BO_ 1635 0;
BA_ "GenMsgCycleTime" BO_ 818 120;
BA_ "GenMsgDelayTime" BO_ 818 10;
BA_ "GenMsgNrOfRepetition" BO_ 818 1;
BA_ "MsgRoutingId" BO_ 818 "61 ";
BA_ "GenMsgILSupport" BO_ 818 0;
BA_ "GenMsgDelayTime" BO_ 1603 10;
BA_ "GenMsgSendType" BO_ 1603 8;
BA_ "GenMsgCycleTimeFast" BO_ 1603 20;
BA_ "GenMsgNrOfRepetition" BO_ 1603 1;
BA_ "MsgRoutingId" BO_ 1603 "60 ";
BA_ "GenMsgILSupport" BO_ 1603 0;
BA_ "GenMsgDelayTime" BO_ 1601 10;
BA_ "GenMsgSendType" BO_ 1601 8;
BA_ "GenMsgCycleTimeFast" BO_ 1601 50;
BA_ "GenMsgNrOfRepetition" BO_ 1601 1;
BA_ "MsgRoutingId" BO_ 1601 "59 ";
BA_ "GenMsgILSupport" BO_ 1601 0;
BA_ "GenMsgCycleTime" BO_ 1600 1200;
BA_ "GenMsgDelayTime" BO_ 1600 10;
BA_ "MsgRoutingId" BO_ 1600 "58 ";
BA_ "GenMsgILSupport" BO_ 1600 0;
BA_ "GenMsgCycleTime" BO_ 816 120;
BA_ "GenMsgDelayTime" BO_ 816 10;
BA_ "MsgRoutingId" BO_ 816 "57 ";
BA_ "GenMsgILSupport" BO_ 816 0;
BA_ "GenMsgCycleTime" BO_ 1622 1000;
BA_ "GenMsgDelayTime" BO_ 1622 10;
BA_ "GenMsgCycleTimeFast" BO_ 1622 20;
BA_ "GenMsgNrOfRepetition" BO_ 1622 10;
BA_ "MsgRoutingId" BO_ 1622 "56 ";
BA_ "GenMsgILSupport" BO_ 1622 0;
BA_ "GenMsgCycleTime" BO_ 1620 1200;
BA_ "GenMsgDelayTime" BO_ 1620 10;
BA_ "MsgRoutingId" BO_ 1620 "54 ";
BA_ "GenMsgILSupport" BO_ 1620 0;
BA_ "GenMsgCycleTime" BO_ 1618 1200;
BA_ "GenMsgDelayTime" BO_ 1618 10;
BA_ "MsgRoutingId" BO_ 1618 "53 ";
BA_ "GenMsgILSupport" BO_ 1618 0;
BA_ "GenMsgCycleTime" BO_ 1617 1200;
BA_ "GenMsgDelayTime" BO_ 1617 10;
BA_ "MsgRoutingId" BO_ 1617 "52 ";
BA_ "GenMsgILSupport" BO_ 1617 0;
BA_ "GenMsgCycleTime" BO_ 940 100;
BA_ "GenMsgDelayTime" BO_ 940 10;
BA_ "GenMsgCycleTimeFast" BO_ 940 20;
BA_ "GenMsgNrOfRepetition" BO_ 940 10;
BA_ "MsgRoutingId" BO_ 940 "49 ";
BA_ "GenMsgILSupport" BO_ 940 0;
BA_ "GenMsgCycleTime" BO_ 1616 1000;
BA_ "GenMsgDelayTime" BO_ 1616 10;
BA_ "GenMsgCycleTimeFast" BO_ 1616 20;
BA_ "GenMsgNrOfRepetition" BO_ 1616 10;
BA_ "MsgRoutingId" BO_ 1616 "47 ";
BA_ "GenMsgILSupport" BO_ 1616 0;
BA_ "GenMsgCycleTime" BO_ 280 20;
BA_ "MsgRoutingId" BO_ 280 "43 ";
BA_ "GenMsgILSupport" BO_ 280 0;
BA_ "GenMsgCycleTime" BO_ 859 100;
BA_ "MsgRoutingId" BO_ 859 "42 ";
BA_ "GenMsgILSupport" BO_ 859 0;
BA_ "GenMsgCycleTime" BO_ 811 100;
BA_ "GenMsgDelayTime" BO_ 811 10;
BA_ "MsgRoutingId" BO_ 811 "40 ";
BA_ "GenMsgILSupport" BO_ 811 0;
BA_ "GenMsgCycleTime" BO_ 313 20;
BA_ "MsgRoutingId" BO_ 313 "33 ";
BA_ "GenMsgILSupport" BO_ 313 0;
BA_ "GenMsgCycleTime" BO_ 312 20;
BA_ "MsgRoutingId" BO_ 312 "32 ";
BA_ "GenMsgILSupport" BO_ 312 0;
BA_ "GenMsgCycleTime" BO_ 1712 1200;
BA_ "GenMsgDelayTime" BO_ 1712 10;
BA_ "GenMsgCycleTimeFast" BO_ 1712 50;
BA_ "GenMsgNrOfRepetition" BO_ 1712 2;
BA_ "MsgRoutingId" BO_ 1712 "28 ";
BA_ "GenMsgILSupport" BO_ 1712 0;
BA_ "GenMsgCycleTime" BO_ 1665 1000;
BA_ "GenSigStartValue" SG_ 826 ABG33A_3_0_BELT_WRNING_PASS 2;
BA_ "GenSigStartValue" SG_ 826 ABG33A_3_4_OCCUPATION_PASS 2;
BA_ "GenSigStartValue" SG_ 826 ABG33A_2_0_IND_WARN_ABG 3;
BA_ "GenSigStartValue" SG_ 961 DMS3C1_6_2_PERMIT_AVN_FLAG 1;
BA_ "GenSigStartValue" SG_ 961 DMS3C1_6_7_NOT_DETECTED_STATUS 1;
BA_ "GenSigStartValue" SG_ 961 DMS3C1_4_0_DMS_IND_REQ_FLAG 7;
BA_ "GenSigStartValue" SG_ 961 DMS3C1_4_3_DMS_RECOG_STATUS 1;
BA_ "GenSigSendType" SG_ 1722 AVN6BA_7_0_GUIDE_LINE_REAR 4;
BA_ "GenSigSendType" SG_ 1722 AVN6BA_7_1_GUIDE_LINE_SIDE 4;
BA_ "GenSigSendType" SG_ 1722 AVN6BA_7_2_GUIDE_LINE_FRONT 4;
BA_ "GenSigSendType" SG_ 1722 AVN6BA_7_3_STEER_ANGLE_INTERLOCK 4;
BA_ "GenSigSendType" SG_ 1722 AVN6BA_7_4_BACK_CAMERA_DELAY 4;
BA_ "GenSigSendType" SG_ 1722 AVN6BA_7_5_REQ_STOP_CAMERA_OUT 4;
BA_ "GenSigSendType" SG_ 1722 AVN6BA_7_6_VIEW_CHANGE_SW 4;
BA_ "GenSigStartValue" SG_ 1722 AVN6BA_6_0_CLIMAITE_PA_TEMP 63;
BA_ "Fhi_SignalComment" SG_ 1722 AVN6BA_6_0_CLIMAITE_PA_TEMP "分解能、ｵﾌｾｯﾄは摂氏時の値。華氏の場合はﾃﾞｰﾀｼｰﾄ参照。

";
BA_ "GenSigSendType" SG_ 1722 AVN6BA_6_0_CLIMAITE_PA_TEMP 4;
BA_ "GenSigSendType" SG_ 1722 AVN6BA_6_6_CLIMATE_SYNC 4;
BA_ "GenSigSendType" SG_ 1722 AVN6BA_6_7_CLIMATE_F_DEF 4;
BA_ "Fhi_SignalComment" SG_ 1722 AVN6BA_5_0_CLIMAITE_DR_TEMP "分解能、ｵﾌｾｯﾄは摂氏時の値。華氏の場合はﾃﾞｰﾀｼｰﾄ参照。

";
BA_ "GenSigSendType" SG_ 1722 AVN6BA_5_0_CLIMAITE_DR_TEMP 4;
BA_ "GenSigSendType" SG_ 1722 AVN6BA_5_6_CLIMAITE_AUTO 4;
BA_ "GenSigSendType" SG_ 1722 AVN6BA_5_7_CLIMAITE_MAX_AC 4;
BA_ "GenSigSendType" SG_ 1722 AVN6BA_4_0_CLIMAITE_VR 4;
BA_ "GenSigSendType" SG_ 1722 AVN6BA_4_3_CLIMATE_AC 4;
BA_ "GenSigSendType" SG_ 1722 AVN6BA_4_4_CLIMAITE_FAN 4;
BA_ "GenSigSendType" SG_ 1722 AVN6BA_3_0_PERSONAL_IC_SH 4;
BA_ "GenSigSendType" SG_ 1722 AVN6BA_3_4_CSTM_SONNER 4;
BA_ "GenSigSendType" SG_ 1722 AVN6BA_3_5_CSTM_RAB 4;
BA_ "GenSigSendType" SG_ 1722 AVN6BA_3_6_REQ_CHG_CSTM_RAB 4;
BA_ "GenSigSendType" SG_ 1722 AVN6BA_3_7_CLIMATE_R_DEF 4;
BA_ "GenSigSendType" SG_ 1722 AVN6BA_2_0_CLIMATE_PTC 4;
BA_ "GenSigSendType" SG_ 1722 AVN6BA_2_1_CLIMATE_MODE 4;
BA_ "GenSigSendType" SG_ 1722 AVN6BA_2_2_CLIMATE_SEAT_C_L 4;
BA_ "GenSigSendType" SG_ 1722 AVN6BA_2_3_CLIMATE_SEAT_C_R 4;
BA_ "GenSigSendType" SG_ 1722 AVN6BA_2_4_CLIMATE_SEAT_H_L 4;
BA_ "GenSigSendType" SG_ 1722 AVN6BA_2_5_CLIMATE_SEAT_H_R 4;
BA_ "GenSigSendType" SG_ 1722 AVN6BA_2_6_CLIMATE_INNER_AIR 4;
BA_ "GenSigSendType" SG_ 1722 AVN6BA_2_7_CLIMATE_ON_OFF 4;
BA_ "GenSigSendType" SG_ 1722 AVN6BA_1_4_CLIMAITE_STATUS 4;
BA_ "GenSigSendType" SG_ 1722 AVN6BA_1_7_CLIMAITE_ON_OFF 4;
BA_ "GenSigStartValue" SG_ 1019 AVN3FB_6_0_ACPANEL_PA_TEMP 63;
BA_ "GenSigStartValue" SG_ 1019 AVN3FB_5_0_ACPANEL_DR_TEMP 63;
BA_ "GenSigSendType" SG_ 1767 RES6E7_2_0_DATA2 4;
BA_ "GenSigSendType" SG_ 1767 RES6E7_1_4_DATA1 4;
BA_ "GenSigSendType" SG_ 1765 RES6E5_6_0_REQ_DOOR_LOCK_ARM 3;
BA_ "GenSigSendType" SG_ 1765 RES6E5_6_3_ON_SIGN 3;
BA_ "GenSigStartValue" SG_ 1635 AHL663_2_0_FAIL_AHL 4;
BA_ "GenSigSendType" SG_ 818 PMN332_7_0_RES_CONTROL_STATUS 3;
BA_ "GenSigSendType" SG_ 818 PMN332_7_2_REQ_RES_P_LOCK 3;
BA_ "GenSigSendType" SG_ 818 PMN332_7_5_IGB_RELAY_REQ 3;
BA_ "GenSigSendType" SG_ 818 PMN332_7_6_IGA_RELAY_REQ 3;
BA_ "GenSigSendType" SG_ 818 PMN332_7_7_REQ_STOP_RES 3;
BA_ "GenSigSendType" SG_ 818 PMN332_6_0_RES_IDLE_TIME 3;
BA_ "GenSigSendType" SG_ 818 PMN332_6_7_CUST 3;
BA_ "GenSigSendType" SG_ 818 PMN332_5_0_PUSHSTART_SW 3;
BA_ "GenSigSendType" SG_ 818 PMN332_5_1_SIG_KEY_PUSHSTART 3;
BA_ "GenSigSendType" SG_ 818 PMN332_5_2_STATE_MODE_POWER 3;
BA_ "GenSigSendType" SG_ 818 PMN332_5_4_BUZ_2SHOT_IN 3;
BA_ "GenSigSendType" SG_ 818 PMN332_5_5_BUZ_INTERMIT1_IN 3;
BA_ "GenSigSendType" SG_ 818 PMN332_5_6_BUZ_INTERMIT2_IN 3;
BA_ "GenSigSendType" SG_ 818 PMN332_5_7_BUZ_CONTINUE_IN 3;
BA_ "GenSigSendType" SG_ 818 PMN332_2_0_WARN_SSP_SIG1 3;
BA_ "GenSigSendType" SG_ 818 PMN332_2_1_WARN_SSP_SIG2 3;
BA_ "GenSigSendType" SG_ 818 PMN332_2_4_SMT_PWR_SIG 3;
BA_ "GenSigSendType" SG_ 818 PMN332_2_7_BUZ_1SHOT_IN 3;
BA_ "GenSigSendType" SG_ 1603 SMT643_2_0_DATA2 4;
BA_ "GenSigSendType" SG_ 1603 SMT643_1_4_DATA1 4;
BA_ "GenSigSendType" SG_ 1601 SMT641_5_0_RKE_BODY_INF_BYTE3 2;
BA_ "GenSigSendType" SG_ 1601 SMT641_4_0_RKE_BODY_INF_BYTE2 2;
BA_ "GenSigSendType" SG_ 1601 SMT641_3_0_RKE_BODY_INF_BYTE1 2;
BA_ "GenSigSendType" SG_ 1601 SMT641_2_0_RKE_BODY_CTL_BYTE 2;
BA_ "GenSigSendType" SG_ 1600 SMT640_7_0_RES_CONTROL_STATUS 3;
BA_ "GenSigSendType" SG_ 1600 SMT640_7_2_REQ_RES_P_LOCK 3;
BA_ "GenSigSendType" SG_ 1600 SMT640_7_4_KEY_STATUS 3;
BA_ "GenSigSendType" SG_ 1600 SMT640_7_5_KEY_SEARCH_RESULT 3;
BA_ "GenSigSendType" SG_ 1600 SMT640_7_7_REQ_STOP_RES 3;
BA_ "GenSigSendType" SG_ 1600 SMT640_6_0_RES_IDLE_TIME 3;
BA_ "GenSigSendType" SG_ 1600 SMT640_5_1_IND_SECURITY 3;
BA_ "GenSigSendType" SG_ 1600 SMT640_5_3_BUZ_WAL_WIUL_PAUSE 3;
BA_ "GenSigSendType" SG_ 1600 SMT640_5_4_BUZ_ALA_MAX 3;
BA_ "GenSigSendType" SG_ 1600 SMT640_5_5_PRG_LOCK_SW_STATE 3;
BA_ "GenSigSendType" SG_ 1600 SMT640_3_0_VERIFY_VALUE_OUT 3;
BA_ "GenSigSendType" SG_ 1600 SMT640_2_0_BUZ_NUM_OUT 1;
BA_ "GenSigSendType" SG_ 1600 SMT640_2_4_BUZ_PAT_OUT 1;
BA_ "GenSigSendType" SG_ 816 SMT330_7_0 3;
BA_ "GenSigSendType" SG_ 816 SMT330_7_1 3;
BA_ "GenSigSendType" SG_ 816 SMT330_7_3_HF_CAPA_ERR_ST 3;
BA_ "GenSigSendType" SG_ 816 SMT330_7_6_HF_RESP_ERR_ST 3;
BA_ "GenSigSendType" SG_ 816 SMT330_6_0_REQ_MESS_PUSHSTART 3;
BA_ "GenSigSendType" SG_ 816 SMT330_6_4_WARN_SSP_SIG1 3;
BA_ "GenSigSendType" SG_ 816 SMT330_5_1_WIUL_CUST 3;
BA_ "GenSigSendType" SG_ 816 SMT330_5_2_WAL_CUST 3;
BA_ "GenSigSendType" SG_ 816 SMT330_5_3_WARN_SSP_SIG2 3;
BA_ "GenSigSendType" SG_ 816 SMT330_5_5_WARN_SSP_SIG3 3;
BA_ "GenSigSendType" SG_ 816 SMT330_4_0_PUSHSTART_SW 3;
BA_ "GenSigSendType" SG_ 816 SMT330_4_1_SIG_KEY_PUSHSTART 3;
BA_ "GenSigSendType" SG_ 816 SMT330_4_2_HF_TOUCH_STATUS 3;
BA_ "GenSigSendType" SG_ 816 SMT330_4_5_HF_KICK_STATUS 3;
BA_ "GenSigSendType" SG_ 816 SMT330_3_0_BUZ_1SHOT_IN 3;
BA_ "GenSigSendType" SG_ 816 SMT330_3_1_BUZ_2SHOT_IN 3;
BA_ "GenSigSendType" SG_ 816 SMT330_3_2_BUZ_INTERMIT1_IN 3;
BA_ "GenSigSendType" SG_ 816 SMT330_3_3_BUZ_INTERMIT2_IN 3;
BA_ "GenSigSendType" SG_ 816 SMT330_3_4_BUZ_CONTINUE_IN 3;
BA_ "GenSigSendType" SG_ 816 SMT330_3_5_BUZ_TRPON_OK_IN 3;
BA_ "GenSigSendType" SG_ 816 SMT330_3_6_STATE_MODE_POWER 3;
BA_ "GenSigSendType" SG_ 1620 BIU654_7_4_KEYSW 3;
BA_ "GenSigSendType" SG_ 1620 BIU654_7_5_ALARM 3;
BA_ "GenSigSendType" SG_ 1620 BIU654_7_6_RES_STOP_JPN 3;
BA_ "GenSigSendType" SG_ 1620 BIU654_6_0_CONT_DATA_FOR_RES 3;
BA_ "GenSigSendType" SG_ 1620 BIU654_2_0_CODE_IMB_FOR_RES 3;
BA_ "GenSigSendType" SG_ 1618 BIU652_7_0_IND_SECURITY_IMB 3;
BA_ "GenSigSendType" SG_ 1618 BIU652_6_0_OCCUPATION_3RDRH 3;
BA_ "GenSigSendType" SG_ 1618 BIU652_6_1_OCCUPATION_3RDCTR 3;
BA_ "GenSigSendType" SG_ 1618 BIU652_6_2_OCCUPATION_3RDLH 3;
BA_ "GenSigSendType" SG_ 1618 BIU652_6_3_OCCUPATION_RRRH 3;
BA_ "GenSigSendType" SG_ 1618 BIU652_6_4_OCCUPATION_RRCTR 3;
BA_ "GenSigSendType" SG_ 1618 BIU652_6_5_OCCUPATION_RRLH 3;
BA_ "GenSigSendType" SG_ 1618 BIU652_6_6_HORNHAZARD_RES_SIG 3;
BA_ "GenSigSendType" SG_ 1618 BIU652_6_7_OCCUPATION_DRVR 3;
BA_ "GenSigSendType" SG_ 1618 BIU652_5_0_STATUS_ROOMLAMP 3;
BA_ "GenSigSendType" SG_ 1618 BIU652_5_3_HEADLAMP_SMALL 3;
BA_ "GenSigSendType" SG_ 1618 BIU652_5_4_ALL_UNLOCK_STATE 3;
BA_ "GenSigSendType" SG_ 1618 BIU652_5_5_DRVR_UNLOCK_STATE 3;
BA_ "GenSigSendType" SG_ 1618 BIU652_5_6_ALL_LOCK_STATE 3;
BA_ "GenSigSendType" SG_ 1618 BIU652_4_0_TRIG_LOCK_UNLOCK 3;
BA_ "GenSigSendType" SG_ 1618 BIU652_3_0_DOOR_DRVR 3;
BA_ "GenSigSendType" SG_ 1618 BIU652_3_1_DOOR_PASS 3;
BA_ "GenSigSendType" SG_ 1618 BIU652_3_2_DOOR_RRRH 3;
BA_ "GenSigSendType" SG_ 1618 BIU652_3_3_DOOR_RRLH 3;
BA_ "GenSigSendType" SG_ 1618 BIU652_3_4_DOOR_RG 3;
BA_ "GenSigSendType" SG_ 1618 BIU652_3_5_DOOR_TR 3;
BA_ "GenSigSendType" SG_ 1618 BIU652_3_7_OPENSW_RG 3;
BA_ "GenSigSendType" SG_ 1618 BIU652_2_0_LOCKSTATUS_DRVR 3;
BA_ "GenSigSendType" SG_ 1618 BIU652_2_1_LOCKSTATUS_PASS 3;
BA_ "GenSigSendType" SG_ 1618 BIU652_2_2_LOCKSTATUS_RRRH 3;
BA_ "GenSigSendType" SG_ 1618 BIU652_2_3_LOCKSTATUS_RRLH 3;
BA_ "GenSigSendType" SG_ 1618 BIU652_2_4_LOCKSTATUS_RG 3;
BA_ "GenSigSendType" SG_ 1618 BIU652_2_6_UNLOCK_DOORKEYSW 3;
BA_ "GenSigSendType" SG_ 1618 BIU652_2_7_LOCK_DOORKEYSW 3;
BA_ "GenSigSendType" SG_ 1617 BIU651_7_0_PWPOS_RL 3;
BA_ "GenSigSendType" SG_ 1617 BIU651_7_2_PWPOS_RR 3;
BA_ "GenSigSendType" SG_ 1617 BIU651_7_4_PWPOS_PASS 3;
BA_ "GenSigSendType" SG_ 1617 BIU651_7_6_PWPOS_DRVR 3;
BA_ "GenSigSendType" SG_ 1617 BIU651_6_0_IND_ACTIVE_HBA 3;
BA_ "GenSigSendType" SG_ 1617 BIU651_6_2_ADB_ACTIVE 3;
BA_ "GenSigSendType" SG_ 1617 BIU651_6_3_JUDGE_ILL 3;
BA_ "GenSigSendType" SG_ 1617 BIU651_6_4_TYPE_LO_BEAM 3;
BA_ "GenSigSendType" SG_ 1617 BIU651_6_6_TYPE_HI_BEAM 3;
BA_ "GenSigSendType" SG_ 1617 BIU651_5_0_SRF_ACTIVE 3;
BA_ "GenSigSendType" SG_ 1617 BIU651_5_1_SRF_IND 3;
BA_ "GenSigSendType" SG_ 1617 BIU651_5_3_SRF_LAMP_LIGHT 3;
BA_ "GenSigSendType" SG_ 1617 BIU651_5_4_SRF_LAMP_LEFT 3;
BA_ "GenSigSendType" SG_ 1617 BIU651_5_5_MSG_STATUS_HBA 3;
BA_ "GenSigSendType" SG_ 1617 BIU651_5_7_IND_FAIL_HBA 3;
BA_ "GenSigSendType" SG_ 1617 BIU651_4_0_BUZ_PATTERN 3;
BA_ "GenSigSendType" SG_ 1617 BIU651_4_4_CSTM_OPE_ALARM 3;
BA_ "GenSigSendType" SG_ 1617 BIU651_4_6_CSTM_HBA 3;
BA_ "GenSigSendType" SG_ 1617 BIU651_3_0_HEADLAMP_PASS_SW 3;
BA_ "GenSigSendType" SG_ 1617 BIU651_3_1_HEADLAMP_AUTO_SW 3;
BA_ "GenSigSendType" SG_ 1617 BIU651_3_2_JUDGE_DOOR_LOCK 3;
BA_ "GenSigSendType" SG_ 1617 BIU651_3_3_JUDGE_DOOR_UNLOCK 3;
BA_ "GenSigSendType" SG_ 1617 BIU651_3_4_HEADLAMP_Lo_SW 3;
BA_ "GenSigSendType" SG_ 1617 BIU651_3_5_HEADLAMP_HI_SW 3;
BA_ "GenSigSendType" SG_ 1617 BIU651_3_6_WIPER_AUTO_SW 3;
BA_ "GenSigSendType" SG_ 1617 BIU651_3_7_PRG_LIN_MEMORY_ON_OFF 3;
BA_ "GenSigSendType" SG_ 1617 BIU651_2_0_CSTM_ILLUMI_SSR 3;
BA_ "GenSigSendType" SG_ 1617 BIU651_2_1_HANDLE 3;
BA_ "GenSigSendType" SG_ 1617 BIU651_2_2_CSTM_SMT 3;
BA_ "GenSigSendType" SG_ 1617 BIU651_2_3_AJARDOOR_STATUS 3;
BA_ "GenSigSendType" SG_ 1617 BIU651_2_4_ONETOUCH_LAMP_OUT 3;
BA_ "GenSigSendType" SG_ 1617 BIU651_2_5_PRG_FAIL_FLAG 3;
BA_ "GenSigSendType" SG_ 1617 BIU651_2_6_CSTM_PSMECU 3;
BA_ "GenSigSendType" SG_ 1617 BIU651_2_7_STATE_REGIST_DEL 3;
BA_ "GenSigSendType" SG_ 1617 BIU651_1_4_SRPOS 3;
BA_ "GenSigSendType" SG_ 1617 BIU651_1_7_WIPER_INT_STATUS 3;
BA_ "Fhi_SignalComment" SG_ 811 EPB32B_6_0_VEHICLE_RUN_STOP_FLG "-

";
BA_ "Fhi_SignalComment" SG_ 811 EPB32B_5_0_FLG_AVH_OILPRES_EPB "-

";
BA_ "Fhi_SignalComment" SG_ 811 EPB32B_5_1_FLG_AVH "-

";
BA_ "Fhi_SignalComment" SG_ 811 EPB32B_5_2_AVH_INTENSIFY_PRES "-

";
BA_ "Fhi_SignalComment" SG_ 811 EPB32B_5_3_BREAK_IND "-

";
BA_ "Fhi_SignalComment" SG_ 811 EPB32B_5_5_AVH_ON_LAMP "-

";
BA_ "Fhi_SignalComment" SG_ 811 EPB32B_4_0_BUZZER "-

";
BA_ "Fhi_SignalComment" SG_ 811 EPB32B_4_2_HILL_HOLD_ON_LAMP "-

";
BA_ "Fhi_SignalComment" SG_ 811 EPB32B_4_3_CLAMP_LAMP "-

";
BA_ "Fhi_SignalComment" SG_ 811 EPB32B_4_5_WARN_LAMP "-

";
BA_ "Fhi_SignalComment" SG_ 811 EPB32B_4_7_WARN_EPB_MET_LCD "-

";
BA_ "Fhi_SignalComment" SG_ 811 EPB32B_3_0_STATUS_EPB "-

";
BA_ "Fhi_SignalComment" SG_ 811 EPB32B_3_3_DYNAMIC_PARKING "-

";
BA_ "Fhi_SignalComment" SG_ 811 EPB32B_3_4_HILL_HOLD_RUN_FLG "-

";
BA_ "Fhi_SignalComment" SG_ 811 EPB32B_3_5_INHIBIT_ISS_DELAY "-

";
BA_ "Fhi_SignalComment" SG_ 811 EPB32B_3_6_INHIBIT_ISS "-

";
BA_ "Fhi_SignalComment" SG_ 811 EPB32B_2_0_ERR_INFO "-

";
BA_ "Fhi_SignalComment" SG_ 811 EPB32B_2_2_EPB_FAIL_FLG1 "-

";
BA_ "Fhi_SignalComment" SG_ 811 EPB32B_2_3_EPB_FAIL_FLG2 "-

";
BA_ "Fhi_SignalComment" SG_ 811 EPB32B_2_4_EPB_FAIL_FLG3 "-

";
BA_ "Fhi_SignalComment" SG_ 811 EPB32B_1_5_REQ_COMM_CONT "-

";
BA_ "GenSigStartValue" SG_ 313 VDC139_7_4_FAIL_PRESSURE_SSR 1;
BA_ "Fhi_SignalComment" SG_ 313 VDC139_7_5_STATUS_EPB "-

";
BA_ "GenSigStartValue" SG_ 313 VDC139_4_3_FAIL_BRAKELAMPSW 1;
BA_ "GenSigStartValue" SG_ 313 VDC139_3_5_FAIL_VDC_SSR 1;
BA_ "GenSigStartValue" SG_ 313 VDC139_3_6_FAIL_SPD_SSR_FHI 1;
BA_ "GenSigStartValue" SG_ 313 VDC139_3_7_FAIL_ABS_SYS 1;
BA_ "Fhi_SignalComment" SG_ 313 VDC139_2_0_SPD_WHEEL_AVE "GW:ID139-B3b4~B2b0→ID270-B5b4~B4b0

";
BA_ "GenSigStartValue" SG_ 313 VDC139_1_4_FAIL_HDC_SYS 1;
BA_ "Fhi_SignalComment" SG_ 313 VDC139_1_5_VEHICLE_HIGHT "XUVは「01:OBK」/北米SPORT_OBKは「10:標準」を送信

";
BA_ "Fhi_SignalComment" SG_ 312 VDC138_7_0_PRESSURE_WC_FTLH "EyeSight対応以外は『0固定』

";
BA_ "Fhi_SignalComment" SG_ 312 VDC138_6_0_PRESSURE_WC_FTRH "EyeSight対応以外は『0固定』

";
BA_ "Fhi_SignalComment" SG_ 312 VDC138_4_0_YAW_RATE "補正値

";
BA_ "Fhi_SignalComment" SG_ 312 VDC138_2_0_STEER_ANGLE "補正値

";
VAL_ 937 MET3A9_3_5_DAY_NIGHT_STATE 1 "Night" 0 "Day" ;
VAL_ 937 MET3A9_3_0_ILL_LEVEL 21 "STEP_21" 20 "STEP_20" 19 "STEP_19" 18 "STEP_18" 17 "STEP_17" 16 "STEP_16" 15 "STEP_15" 14 "STEP_14" 13 "STEP_13" 12 "STEP_12" 11 "STEP_11" 10 "STEP_10" 9 "STEP_9" 8 "STEP_8" 7 "STEP_7" 6 "STEP_6" 5 "STEP_5" 4 "STEP_4" 3 "STEP_3" 2 "STEP_2" 1 "STEP_1" 0 "Not_required" ;
VAL_ 937 MET3A9_1_7_BRIGHT_STATE 1 "ON" 0 "OFF" ;
VAL_ 937 MET3A9_1_6_UI_THEME_STATE 1 "Night" 0 "Day" ;
VAL_ 1614 RKE64E_6_0_BUZ_1SHOT_IN 1 "REQ" 0 "NON_REQ" ;
VAL_ 1614 RKE64E_6_1_BUZ_2SHOT_IN 1 "REQ" 0 "NON_REQ" ;
VAL_ 1614 RKE64E_6_2_REQ_WARNG_BAT_POWER 1 "Battery_Power_Low" 0 "Battery_Power_Normal" ;
VAL_ 1614 RKE64E_4_0_TRANS_ID 4 "Trans ID 4" 3 "Trans ID 3" 2 "Trans ID 2" 1 "Trans ID 1" 0 "NON_REG" ;
VAL_ 1614 RKE64E_4_3_COUNTER 3 "counter value 3" 2 "counter value 2" 1 "counter value 1" 0 "counter value 0" ;
VAL_ 1614 RKE64E_4_5_TIME_ON_SW_KEY_LESS 3 "more than 2.4s" 2 "1.6s-2.4s" 1 "0.8s-1.6s" 0 "under 0.8s" ;
VAL_ 1614 RKE64E_3_0_REQ_NOMAL_KEY_LESS 8 "TRUNK_REQ" 4 "UNLOCK_REQ" 2 "LOCK_REQ" 1 "PANIC_REQ" 0 "NON_REQ" ;
VAL_ 1614 RKE64E_1_4_WAKE_UP_FRAME 1 "WakeUP_FRAME" 0 "Normal_FRAME" ;
VAL_ 1614 RKE64E_1_5_REQ_COMM_CONT 1 "REQ" 0 "NON_REQ" ;
VAL_ 826 ABG33A_5_0_P_SIDE_ABG_DEPLOY 1 "ON" 0 "OFF" ;
VAL_ 826 ABG33A_5_1_D_SIDE_ABG_DEPLOY 1 "ON" 0 "OFF" ;
VAL_ 826 ABG33A_5_2_FRONT_FAR_ABG_DEPLOY 1 "ON" 0 "OFF" ;
VAL_ 826 ABG33A_5_3_REAR_FAR_ABG_DEPLOY 1 "ON" 0 "OFF" ;
VAL_ 826 ABG33A_5_4_REAR_RH_ABG_DEPLOY 1 "ON" 0 "OFF" ;
VAL_ 826 ABG33A_5_5_REAR_LH_ABG_DEPLOY 1 "ON" 0 "OFF" ;
VAL_ 826 ABG33A_5_6_P_CURTAIN_ABG_DEPLOY 1 "ON" 0 "OFF" ;
VAL_ 826 ABG33A_5_7_D_CURTAIN_ABG_DEPLOY 1 "ON" 0 "OFF" ;
VAL_ 826 ABG33A_4_0_D_FRONT_ABG_DEPLOY 1 "ON" 0 "OFF" ;
VAL_ 826 ABG33A_4_1_P_FRONT_ABG_DEPLOY 1 "ON" 0 "OFF" ;
VAL_ 826 ABG33A_4_2_P_ABG_DEPLOY 1 "ON" 0 "OFF" ;
VAL_ 826 ABG33A_4_3_D_ABG_DEPLOY 1 "ON" 0 "OFF" ;
VAL_ 826 ABG33A_4_4_P_BELT_PRETENTION 1 "ON" 0 "OFF" ;
VAL_ 826 ABG33A_4_5_D_BELT_PRETENTION 1 "ON" 0 "OFF" ;
VAL_ 826 ABG33A_4_6_D_KNEE_ABG_DEPLOY 1 "ON" 0 "OFF" ;
VAL_ 826 ABG33A_4_7_P_KNEE_ABG_DEPLOY 1 "ON" 0 "OFF" ;
VAL_ 826 ABG33A_3_0_BELT_WRNING_PASS 3 "SW_FAIL" 2 "UNDECIDED" 1 "UNBUCKLED(PASSENGER OCCUPANT)" 0 "BUCKLE OR UNBUCKLED(PASSENGER EMPTY)" ;
VAL_ 826 ABG33A_3_2_BUCKLESW_DRVR 3 "NOT RECEIVED" 2 "INVALID" 1 "BUCKLE SW OFF" 0 "BUCKLE SW ON" ;
VAL_ 826 ABG33A_3_4_OCCUPATION_PASS 3 "SYS_FAIL" 2 "NON" 1 "ACTIVE" 0 "Non_PASSENGER" ;
VAL_ 826 ABG33A_3_6_IND_ACT_ABG_PASS 3 "NON" 2 "ON_IND" 1 "OFF_IND" 0 "ON_IND and OFF_IND" ;
VAL_ 826 ABG33A_2_0_IND_WARN_ABG 3 "OTHER_FAIL" 2 "RESERVE" 1 "FAIL_Turn_ON" 0 "Turn_OFF" ;
VAL_ 826 ABG33A_2_2_DETECT_CRUSH 7 "RESERVE" 6 "RESERVE" 5 "CRUSH_DETECT" 4 "RESERVE" 3 "RESERVE" 2 "RESERVE" 1 "RESERVE" 0 "NORMAL" ;
VAL_ 826 ABG33A_2_5_STATUS_CRUSH_ECALL 7 "RESERVE" 6 "RESERVE" 5 "REAR COLLISION" 4 "ROLLOVER" 3 "RIGHT SIDE COLLISION" 2 "LEFT SIDE COLLISION" 1 "FRONTAL COLLISION" 0 "NORMAL" ;
VAL_ 826 ABG33A_1_4_FLG_ABGIND_CTRL 1 "ACTIVE_PassengerSeat IND contorol" 0 "NON_PassengerSeat IND contorol" ;
VAL_ 826 ABG33A_1_5_REQ_COMM_CONT 1 "REQ" 0 "NON_REQ" ;
VAL_ 826 ABG33A_1_6_COLLISION_COUNTER 3 "RESERVD" 2 "MORE THAN ONCE" 1 "ONECE" 0 "NORMAL" ;
VAL_ 961 DMS3C1_7_4_SHORT_DIST_DETECT 1 "SHORT_DIST_DETECT" 0 "NO_SHORT_DIST_DETECT" ;
VAL_ 961 DMS3C1_7_5_PRESENCE_DETECT 1 "PRESENCE" 0 "NO_PRESENCE" ;
VAL_ 961 DMS3C1_7_6_RADER_EQUIP 1 "RADAR_EQUIP" 0 "NO_RADAR_EQUIP" ;
VAL_ 961 DMS3C1_7_7_LOSING_POSTURE_DETECT 1 "LOSING_POSTURE" 0 "NO_LOSING_POSTURE" ;
VAL_ 961 DMS3C1_6_0_ID_RECOG_CANCEL 1 "ID_RECOG_CANCEL" 0 "DEFAULT" ;
VAL_ 961 DMS3C1_6_1_ID_ENABLE_FLAG 1 "ID_VALID" 0 "ID_INVALID" ;
VAL_ 961 DMS3C1_6_2_PERMIT_AVN_FLAG 1 "PERMIT" 0 "PROHIBIT" ;
VAL_ 961 DMS3C1_6_4_DISTRACTION_STATUS 1 "DISTRACTION" 0 "DEFAULT" ;
VAL_ 961 DMS3C1_6_5_DROWSINESS_STATUS 1 "DROWSINESS" 0 "DEFAULT" ;
VAL_ 961 DMS3C1_6_6_DROWSINESS_LV2_STATUS 1 "DROWSINESS_LEVEL2" 0 "DEFAULT" ;
VAL_ 961 DMS3C1_6_7_NOT_DETECTED_STATUS 1 "NOT_DETECTED" 0 "DETECTED" ;
VAL_ 961 DMS3C1_5_0_ID_LIST 31 "ID_1_2_3_4_5" 1 "ID_1" 0 "DEFAULT" ;
VAL_ 961 DMS3C1_5_5_ID_EDIT_FLAG 6 "REQ_ID_DEL_ALL" 5 "REQ_CUST_DEL_DELECT" 4 "REQ_ID_DEL_DELECT" 3 "REQ_ID_CUST_EDIT" 2 "REQ_ID_REGIST" 0 "DEFAULT" ;
VAL_ 961 DMS3C1_4_0_DMS_IND_REQ_FLAG 7 "UNDEFINED" 5 "FAULT_IND" 4 "HALT_IND" 3 "OFF_IND" 2 "ID_DEF_IND" 1 "ID_UNDEF_IND" 0 "DEFAULT" ;
VAL_ 961 DMS3C1_4_3_DMS_RECOG_STATUS 1 "IDENTIFING_ON" 0 "IDENTIFING_OFF" ;
VAL_ 961 DMS3C1_4_4_DRIVER_STATUS 3 "DRV_GLASSES" 2 "DRV_MASK" 1 "DRV_NORMAL" 0 "DEFAULT" ;
VAL_ 961 DMS3C1_3_0_DRIVER_REGIST_ID 15 "IDENTIFING" 14 "ALL_ID" 5 "ID_5" 4 "ID_4" 3 "ID_3" 2 "ID_2" 1 "ID_1" 0 "DEFAULT" ;
VAL_ 961 DMS3C1_3_4_CUST_EDIT_FLAG 3 "REQ_CUST_FAIL" 2 "REQ_CUST_COMP" 1 "REQ_CUST_PRESENT" 0 "DEFAULT" ;
VAL_ 961 DMS3C1_3_6_ID_RECOG_FLAG 1 "ID_DEFINED" 0 "ID_UNDIFINED" ;
VAL_ 961 DMS3C1_2_0_LEVEL_DROWS 2 "DROWS_LEVEL2" 1 "DROWS_LEVEL1" 0 "NO_DROWSINESS" ;
VAL_ 961 DMS3C1_2_3_DROWS_DETECT_FLAG 1 "DROWS_DETECT" 0 "NO_DROWS_DETECT" ;
VAL_ 961 DMS3C1_2_7_DIST_DETECT_FLAG 1 "DIST_DETECT" 0 "NO_DIST_DETECT" ;
VAL_ 961 DMS3C1_1_4_WAKE_UP_FRAME 1 "WakeUP_FRAME" 0 "Normal_FRAME" ;
VAL_ 961 DMS3C1_1_5_REQ_COMM_CONT 1 "REQUEST" 0 "NO_REQUEST" ;
VAL_ 961 DMS3C1_1_7_EYE_DIST_FLAG 1 "EYE_DIST_DETECT" 0 "NO_DETECT" ;
VAL_ 1651 ACN673_7_2_REQ_STRG_H 3 "NO_DIFINITION" 2 "LOW" 1 "HIGH" 0 "OFF" ;
VAL_ 1651 ACN673_7_1_SEAT_H_L_AUTOIND 1 "ON" 0 "OFF" ;
VAL_ 1651 ACN673_7_0_SEAT_H_R_AUTOIND 1 "ON" 0 "OFF" ;
VAL_ 1651 ACN673_6_0_RR_FAN_SYMBOL 1 "ON" 0 "OFF" ;
VAL_ 1651 ACN673_6_2_SEAT_H_R 7 "VENT HI" 6 "VENT MI" 5 "VENT LO" 4 "UNDEFINED" 3 "HEATER HI" 2 "HEATER MI" 1 "HEATER LO" 0 "OFF" ;
VAL_ 1651 ACN673_6_5_SEAT_H_L 7 "VENT HI" 6 "VENT MI" 5 "VENT LO" 4 "UNDEFINED" 3 "HEATER HI" 2 "HEATER MI" 1 "HEATER LO" 0 "OFF" ;
VAL_ 1651 ACN673_5_0_DR_ONLY 3 "ALL" 2 "FRONT" 1 "DRIVER" 0 "BLANK" ;
VAL_ 1651 ACN673_5_4_AC_SI_DS_SET 3 "Reserve" 2 "Normal" 1 "Mild" 0 "Invalid" ;
VAL_ 1651 ACN673_5_6_STRG_H_AUTOIND 1 "ON" 0 "OFF" ;
VAL_ 1651 ACN673_5_7_AC_SI_DS_FLG 1 "WITH" 0 "WITHOUT" ;
VAL_ 1651 ACN673_4_0_SEAT_HEATER_DR 3 "3段" 2 "2段" 1 "1段" 0 "OFF" ;
VAL_ 1651 ACN673_4_2_SEAT_HEATER_PA 3 "3段" 2 "2段" 1 "1段" 0 "OFF" ;
VAL_ 1651 ACN673_4_4_SEAT_HEATER 1 "有り" 0 "なし" ;
VAL_ 1651 ACN673_4_5_TEMP_SET_TYPE 3 "不使用" 2 "華氏" 1 "欧州摂氏" 0 "欧州摂氏以外" ;
VAL_ 1651 ACN673_4_7_VENTI_SEAT_EX_HI 1 "ON" 0 "OFF" ;
VAL_ 1651 ACN673_1_6_SYNC_RR 1 "ON" 0 "OFF" ;
VAL_ 1651 ACN673_1_7_RR_LOCK 1 "ON" 0 "OFF" ;
VAL_ 1650 ACN672_6_0_DEF 1 "ON" 0 "OFF" ;
VAL_ 1650 ACN672_6_1_FAN_SYMBOL 1 "ON" 0 "OFF" ;
VAL_ 1650 ACN672_6_2_REAR_MODE 3 "FOOT" 2 "B/L" 1 "VENT" 0 "BLANK" ;
VAL_ 1650 ACN672_6_4_UNIT_TEMP 1 "deg F" 0 "deg C" ;
VAL_ 1650 ACN672_6_5_SPEC_AC_UNIT 3 "DUAL" 2 "SINGLE" 1 "MANU" 0 "LESS" ;
VAL_ 1650 ACN672_6_7_REAR_AC 1 "WITH" 0 "WITHOUT" ;
VAL_ 1650 ACN672_5_0_AC_VR_MODE 3 "No_Definition" 2 "VOICE_MODE_ERROR" 1 "VOICE_MODE_ON" 0 "OFF" ;
VAL_ 1650 ACN672_4_0_AC_INTERRUPT_DISPLAY 1 "ON" 0 "OFF" ;
VAL_ 1650 ACN672_4_1_AC_VR_ACTION 1 "INVALID" 0 "NORMAL" ;
VAL_ 1650 ACN672_3_0_MAX_AC 1 "ON" 0 "OFF" ;
VAL_ 1650 ACN672_3_1_INFO_SYNC_OR_SING 1 "ON" 0 "OFF" ;
VAL_ 1650 ACN672_3_2_INFO_FULL_OR_AUTO 3 "NONE" 2 "FULL_AUTO" 1 "AUTO" 0 "BLANK" ;
VAL_ 1650 ACN672_3_4_INFO_AC_ON 1 "ON" 0 "OFF" ;
VAL_ 1650 ACN672_3_5_INFO_RDEF 1 "ON" 0 "OFF" ;
VAL_ 1650 ACN672_3_6_INFO_CIRCULATION 3 "TURN_ON_ALL" 2 "Outside Air" 1 "Recirculation" 0 "TURN_OFF" ;
VAL_ 1650 ACN672_2_0_INFO_MODE_VENT 15 "ALL" 7 "ALL FLOW" 6 "DEF" 5 "FOOT/DEF" 4 "FOOT" 3 "B/L" 2 "VENTⅡ" 1 "VENT" 0 "BLANK" ;
VAL_ 1650 ACN672_2_5_INFO_LEV_BLOWERFAN 7 "HI" 6 "M5" 5 "M4" 4 "M3" 3 "M2" 2 "M1" 1 "LO" 0 "OFF" ;
VAL_ 1650 ACN672_1_4_LVL_BLOWERFAN_RR 7 "HI" 6 "M5" 5 "M4" 4 "M3" 3 "M2" 2 "M1" 1 "LO" 0 "OFF" ;
VAL_ 1650 ACN672_1_7_REAR_AUTO 1 "AUTO" 0 "BLANK" ;
VAL_ 722 ACN2D2_5_0_REQ_ENG_RPM 6 "HOT_LOLO (ME2-H/BF4)" 5 "HOT_Mi (ME2-H/BF4)" 4 "HOT_LO" 3 "COOL_LO" 2 "HOT_HI" 1 "COOL_HI" 0 "NON_REQ" ;
VAL_ 722 ACN2D2_4_0_LVL_PTC 3 "3RD" 2 "2ND" 1 "1ST" 0 "OFF" ;
VAL_ 722 ACN2D2_4_2_MARGIN_OF_AC 7 "7" 6 "6" 5 "5" 4 "4" 3 "3" 2 "2" 1 "1" 0 "0" ;
VAL_ 722 ACN2D2_4_5_LVL_BLOWER_FAN 7 "HI(AS1)/NONE(Other)" 6 "M5(AS1)/HI(Other)" 5 "M4" 4 "M3" 3 "M2/BLW_ON" 2 "M1" 1 "LO" 0 "OFF" ;
VAL_ 722 ACN2D2_3_0_PERMIT_ISS 3 "INHIBIT" 2 "PERMIT" 1 "PERMIT" 0 "PERMIT" ;
VAL_ 722 ACN2D2_3_2_TRQ_PAT_COMP_ESTM 6 "Pattern6" 5 "Pattern5" 4 "Pattern4" 3 "Pattern3" 2 "Pattern2" 1 "Pattern1" 0 "DEFAULT" ;
VAL_ 722 ACN2D2_3_5_IND_ROOM_TEMP 4 "40≦TR" 3 "30≦TR<40" 2 "20≦TR<30" 1 "10≦TR<20" 0 "<10" ;
VAL_ 722 ACN2D2_2_0_FAIL_TRQ_COMP_ESTM 1 "FAIL" 0 "NORMAL" ;
VAL_ 722 ACN2D2_2_1_FAIL_AC 1 "FAIL" 0 "NORMAL" ;
VAL_ 722 ACN2D2_2_2_REQ_INHIBIT_LOCKUP 1 "INHIBIT" 0 "PERMIT" ;
VAL_ 722 ACN2D2_2_3_AC_ON 1 "ON" 0 "OFF" ;
VAL_ 722 ACN2D2_2_4_RDEFOGSW 1 "ON" 0 "OFF" ;
VAL_ 722 ACN2D2_2_5_WARM_UP 1 "WARM_UP" 0 "WARM_UP_OUT" ;
VAL_ 722 ACN2D2_2_6_AC_AUTO_MANUAL 1 "Auto" 0 "Manu" ;
VAL_ 722 ACN2D2_2_7_COMP_TYPE 1 "VAR_COMP" 0 "FIX_COMP" ;
VAL_ 722 ACN2D2_1_7_WARM_POWER_CONT 1 "ON" 0 "OFF" ;
VAL_ 1722 AVN6BA_7_0_GUIDE_LINE_REAR 1 "ON" 0 "OFF" ;
VAL_ 1722 AVN6BA_7_1_GUIDE_LINE_SIDE 1 "ON" 0 "OFF" ;
VAL_ 1722 AVN6BA_7_2_GUIDE_LINE_FRONT 1 "ON" 0 "OFF" ;
VAL_ 1722 AVN6BA_7_3_STEER_ANGLE_INTERLOCK 1 "ON" 0 "OFF" ;
VAL_ 1722 AVN6BA_7_4_BACK_CAMERA_DELAY 1 "ON" 0 "OFF" ;
VAL_ 1722 AVN6BA_7_5_REQ_STOP_CAMERA_OUT 1 "REQ" 0 "NON_REQ" ;
VAL_ 1722 AVN6BA_7_6_VIEW_CHANGE_SW 3 "NO_DEFINITION" 2 "LONG_PUSH" 1 "SHORT_PUSH" 0 "INVALID" ;
VAL_ 1722 AVN6BA_6_6_CLIMATE_SYNC 1 "ON/OFF Change" 0 "invalid" ;
VAL_ 1722 AVN6BA_6_7_CLIMATE_F_DEF 1 "ON/OFF Change" 0 "invalid" ;
VAL_ 1722 AVN6BA_5_6_CLIMAITE_AUTO 1 "FULL AUTO ON" 0 "invalid" ;
VAL_ 1722 AVN6BA_5_7_CLIMAITE_MAX_AC 1 "ON/OFF Change" 0 "invalid" ;
VAL_ 1722 AVN6BA_4_0_CLIMAITE_VR 4 "Voice recognition" 0 "No voice recognition" ;
VAL_ 1722 AVN6BA_4_3_CLIMATE_AC 1 "ON/OFF Change" 0 "invalid" ;
VAL_ 1722 AVN6BA_4_4_CLIMAITE_FAN 15 "No change" 14 "Reserve" 13 "Reserve" 12 "Reserve" 11 "Reserve" 10 "Reserve" 9 "Reserve" 8 "Reserve" 7 "HI" 6 "M5" 5 "M4" 4 "M3" 3 "M2" 2 "M1" 1 "LO" 0 "invalid" ;
VAL_ 1722 AVN6BA_3_0_PERSONAL_IC_SH 7 "Reserve" 6 "Reserve" 5 "Reserve" 4 "Reserve" 3 "type C" 2 "type B" 1 "type A" 0 "No information" ;
VAL_ 1722 AVN6BA_3_4_CSTM_SONNER 1 "ON" 0 "OFF" ;
VAL_ 1722 AVN6BA_3_5_CSTM_RAB 1 "ON" 0 "OFF" ;
VAL_ 1722 AVN6BA_3_6_REQ_CHG_CSTM_RAB 1 "request" 0 "no request" ;
VAL_ 1722 AVN6BA_3_7_CLIMATE_R_DEF 1 "ON/OFF Change" 0 "invalid" ;
VAL_ 1722 AVN6BA_2_0_CLIMATE_PTC 1 "ON/OFF Change" 0 "invalid" ;
VAL_ 1722 AVN6BA_2_1_CLIMATE_MODE 1 "ON/OFF Change" 0 "invalid" ;
VAL_ 1722 AVN6BA_2_2_CLIMATE_SEAT_C_L 1 "ON/OFF Change" 0 "invalid" ;
VAL_ 1722 AVN6BA_2_3_CLIMATE_SEAT_C_R 1 "ON/OFF Change" 0 "invalid" ;
VAL_ 1722 AVN6BA_2_4_CLIMATE_SEAT_H_L 1 "ON/OFF Change" 0 "invalid" ;
VAL_ 1722 AVN6BA_2_5_CLIMATE_SEAT_H_R 1 "ON/OFF Change" 0 "invalid" ;
VAL_ 1722 AVN6BA_2_6_CLIMATE_INNER_AIR 1 "ON/OFF Change" 0 "invalid" ;
VAL_ 1722 AVN6BA_2_7_CLIMATE_ON_OFF 1 "ON/OFF Change" 0 "invalid" ;
VAL_ 1722 AVN6BA_1_4_CLIMAITE_STATUS 7 "Not Found" 6 "Detected" 5 "Replay" 4 "Loading" 3 "Accepting" 2 "Ready" 1 "Standby" 0 "Start up" ;
VAL_ 1722 AVN6BA_1_7_CLIMAITE_ON_OFF 1 "ON" 0 "OFF" ;
VAL_ 1019 AVN3FB_7_0_SMT_TIM_RESET_REQ 1 "required" 0 "NOT required" ;
VAL_ 1019 AVN3FB_7_1_SMT_EG_CSTM_REQ 1 "required" 0 "NOT required" ;
VAL_ 1019 AVN3FB_7_2_EYE_YEILD_CSTM 1 "ON" 0 "OFF" ;
VAL_ 1019 AVN3FB_7_3_EYE_STOP_CSTM 1 "ON" 0 "OFF" ;
VAL_ 1019 AVN3FB_7_4_EYE_NO_ENTRY_CSTM 1 "ON" 0 "OFF" ;
VAL_ 1019 AVN3FB_7_5_MVS_CAMERA_SELECT_SW 1 "SW Push Event" 0 "No Operation(SW Release Event)" ;
VAL_ 1019 AVN3FB_7_7_ACPANEL_DR_ONLY 1 "SW Push Event" 0 "invalid" ;
VAL_ 1019 AVN3FB_6_6_ACPANEL_MODE_DOWN 1 "SW Push Event" 0 "invalid" ;
VAL_ 1019 AVN3FB_6_7_ACPANEL_MODE_UP 1 "SW Push Event" 0 "invalid" ;
VAL_ 1019 AVN3FB_5_6_ACPANEL_FAN_DOWN 1 "SW Push Event" 0 "invalid" ;
VAL_ 1019 AVN3FB_5_7_ACPANEL_FAN_UP 1 "SW Push Event" 0 "invalid" ;
VAL_ 1019 AVN3FB_4_0_ACPANEL_FAN_LEVEL 15 "No change" 14 "Reserve" 13 "Reserve" 12 "Reserve" 11 "Reserve" 10 "Reserve" 9 "Reserve" 8 "Reserve" 7 "HI" 6 "M5" 5 "M4" 4 "M3" 3 "M2" 2 "M1" 1 "LO" 0 "invalid" ;
VAL_ 1019 AVN3FB_4_4_ACPANEL_MODE_VENT 15 "Invalid" 6 "DEF" 5 "FOOT/DEF" 4 "FOOT" 3 "B/L" 2 "VENTⅡ" 1 "VENT" 0 "Invalid" ;
VAL_ 1019 AVN3FB_3_0_ACPANEL_PA_TEMP_DOWN 1 "SW Push Event" 0 "invalid" ;
VAL_ 1019 AVN3FB_3_1_ACPANEL_PA_TEMP_UP 1 "SW Push Event" 0 "invalid" ;
VAL_ 1019 AVN3FB_3_2_ACPANEL_DR_TEMP_DOWN 1 "SW Push Event" 0 "invalid" ;
VAL_ 1019 AVN3FB_3_3_ACPANEL_DR_TEMP_UP 1 "SW Push Event" 0 "invalid" ;
VAL_ 1019 AVN3FB_3_4_ACPANEL_SYNC 1 "SW Push Event" 0 "invalid" ;
VAL_ 1019 AVN3FB_3_5_ACPANEL_AC 1 "SW Push Event" 0 "invalid" ;
VAL_ 1019 AVN3FB_3_6_F_DEF_SW 1 "SW Push Event" 0 "invalid" ;
VAL_ 1019 AVN3FB_3_7_R_DEF_SW 1 "SW Push Event" 0 "invalid" ;
VAL_ 1019 AVN3FB_2_0_ACPANEL_AUTO 1 "SW Push Event" 0 "invalid" ;
VAL_ 1019 AVN3FB_2_1_ACPANEL_MAX_AC 1 "SW Push Event" 0 "invalid" ;
VAL_ 1019 AVN3FB_2_2_ACPANEL_SEAT_C_P 1 "SW Push Event" 0 "invalid" ;
VAL_ 1019 AVN3FB_2_3_ACPANEL_SEAT_C_D 1 "SW Push Event" 0 "invalid" ;
VAL_ 1019 AVN3FB_2_4_ACPANEL_SEAT_H_P 1 "SW Push Event" 0 "invalid" ;
VAL_ 1019 AVN3FB_2_5_ACPANEL_SEAT_H_D 1 "SW Push Event" 0 "invalid" ;
VAL_ 1019 AVN3FB_2_6_ACPANEL_INNER_AIR 1 "SW Push Event" 0 "invalid" ;
VAL_ 1019 AVN3FB_2_7_ACPANEL_AC_ON_OFF 1 "SW Push Event" 0 "invalid" ;
VAL_ 1019 AVN3FB_1_4_EYE_CSTM_REQ_3FB 1 "required" 0 "NOT required" ;
VAL_ 1019 AVN3FB_1_5_DDAW_WARNING_CSTM 1 "ON" 0 "OFF" ;
VAL_ 1019 AVN3FB_1_6_SIGN_SWITCH_SND 1 "ON" 0 "OFF" ;
VAL_ 1019 AVN3FB_1_7_SLWF_CSTM 1 "ON" 0 "OFF" ;
VAL_ 1765 RES6E5_6_0_REQ_DOOR_LOCK_ARM 1 "REQ" 0 "NON_REQ" ;
VAL_ 1765 RES6E5_6_1_REQ_ST_ON 1 "ON" 0 "OFF" ;
VAL_ 1765 RES6E5_6_2_REQ_POWER_ON 1 "ON" 0 "OFF" ;
VAL_ 1765 RES6E5_6_3_ON_SIGN 1 "RES_ON" 0 "NON" ;
VAL_ 1765 RES6E5_5_5_REQ_PARKLIGHT_HORN 4 "ParkLightON_HORN_OFF" 3 "ParkLight&HORN_3times" 2 "ParkLight&HORN_2times" 1 "ParkLight&HORN_1time" 0 "NON_REQ" ;
VAL_ 1765 RES6E5_1_4_WAKE_UP_FRAME 1 "WakeUP_FRAME" 0 "Normal_FRAME" ;
VAL_ 1765 RES6E5_1_5_REQ_COMM_CONT 1 "REQ" 0 "NON_REQ" ;
VAL_ 1696 AIL6A0_7_0_AIL_RENDER_STA 7 "undefined" 6 "undefined" 5 "CUSTOM" 4 "DR_MD_Linkage" 3 "PAT_D" 2 "PAT_C" 1 "PAT_B" 0 "PAT_A" ;
VAL_ 1696 AIL6A0_7_3_AIL_RENDER_PAT_A_DIS 1 "ON" 0 "OFF" ;
VAL_ 1696 AIL6A0_7_4_AIL_RENDER_PAT_B_DIS 1 "ON" 0 "OFF" ;
VAL_ 1696 AIL6A0_7_5_AIL_RENDER_PAT_C_DIS 1 "ON" 0 "OFF" ;
VAL_ 1696 AIL6A0_7_6_AIL_RENDER_PAT_D_DIS 1 "ON" 0 "OFF" ;
VAL_ 1696 AIL6A0_7_7_AIL_RENDER_DR_MD_DIS 1 "ON" 0 "OFF" ;
VAL_ 1696 AIL6A0_5_6_AIL_CSTM_PRS_DIS_REQ 1 "Display" 0 "tone down" ;
VAL_ 1696 AIL6A0_5_7_AIL_RENDER_CSTM_DIS 1 "ON" 0 "OFF" ;
VAL_ 1696 AIL6A0_4_6_AIL_SECOND_COLOR_DIS 1 "ON" 0 "OFF" ;
VAL_ 1696 AIL6A0_4_7_AIL_SECOND_BRIGHT_DIS 1 "ON" 0 "OFF" ;
VAL_ 1696 AIL6A0_3_0_AIL_ADAS_VEH_DIS_STA 1 "ON" 0 "OFF" ;
VAL_ 1696 AIL6A0_3_1_AIL_ADAS_VEH_DIS__DIS 1 "ON" 0 "OFF" ;
VAL_ 1696 AIL6A0_3_2_AIL_ADAS_LANE_DEV_STA 1 "ON" 0 "OFF" ;
VAL_ 1696 AIL6A0_3_3_AIL_ADAS_LANE_DEV_DIS 1 "ON" 0 "OFF" ;
VAL_ 1696 AIL6A0_3_4_AIL_ADAS_FT_CROSS_STA 1 "ON" 0 "OFF" ;
VAL_ 1696 AIL6A0_3_5_AIL_ADAS_FT_CROSS_DIS 1 "ON" 0 "OFF" ;
VAL_ 1696 AIL6A0_3_6_AIL_ADAS_HANDS_FR_STA 1 "ON" 0 "OFF" ;
VAL_ 1696 AIL6A0_3_7_AIL_ADAS_HANDS_FR_DIS 1 "ON" 0 "OFF" ;
VAL_ 1696 AIL6A0_2_0_AIL_ADAS_EXP_STA 1 "ON" 0 "OFF" ;
VAL_ 1696 AIL6A0_2_1_AIL_ADAS_EXP_DIS 1 "ON" 0 "OFF" ;
VAL_ 1696 AIL6A0_2_2_AIL_NOTIFI_EXP_STA 1 "ON" 0 "OFF" ;
VAL_ 1696 AIL6A0_2_3_AIL_NOTIFI_EXP_DIS 1 "ON" 0 "OFF" ;
VAL_ 1696 AIL6A0_2_4_AIL_AIR_CON_EXP_STA 1 "ON" 0 "OFF" ;
VAL_ 1696 AIL6A0_2_5_AIL_AIR_CON_EXP_DIS 1 "ON" 0 "OFF" ;
VAL_ 1696 AIL6A0_1_4_AIL_ON_OFF_STA 1 "ON" 0 "OFF" ;
VAL_ 1696 AIL6A0_1_6_AIL_WEL_FOL_STA 1 "ON" 0 "OFF" ;
VAL_ 1696 AIL6A0_1_7_AIL_WEL_FOL_DIS 1 "ON" 0 "OFF" ;
VAL_ 1314 AIL522_1_4_ActiveWakeUpBit 1 "active wakeup" 0 "passive wakeup" ;
VAL_ 1635 AHL663_3_0_FAIL_ADB 3 "NONE" 2 "BULB_CHECK" 1 "ON" 0 "OFF" ;
VAL_ 1635 AHL663_3_2_HEADLAMP_HI_IND 1 "ON" 0 "OFF" ;
VAL_ 1635 AHL663_3_3_ADB_ACTIVE_IND 1 "ON" 0 "OFF" ;
VAL_ 1635 AHL663_3_4_CSTM_SRH_OFF 1 "ON" 0 "OFF" ;
VAL_ 1635 AHL663_2_0_FAIL_AHL 7 "3_BLINK_ALARM(Only_MS2)" 6 "2_BLINK_ALARM(Only_MS2)" 5 "6_BLINK_ALARM(Only_MS2)" 4 "BULB_CHECK" 3 "2_BLINK_ALARM" 2 "3_BLINK_ALARM" 1 "ON" 0 "OFF" ;
VAL_ 1635 AHL663_2_3_FAIL_LED_HEADLAMP 3 "NONE" 2 "BULB_CHECK" 1 "ON" 0 "OFF" ;
VAL_ 1635 AHL663_2_5_IND_AFS 7 "NONE" 6 "NONE" 5 "NONE" 4 "BULB_CHECK" 3 "2_BLINK_ALARM" 2 "3_BLINK_ALARM" 1 "ON" 0 "OFF" ;
VAL_ 818 PMN332_7_0_RES_CONTROL_STATUS 3 "Termination for Remote engine start control (Termination sequence for Remote engine start control)" 2 "Remote engine start heating operation (During Remote engine start running)" 1 "Remote engine start starting control (Before engine starts)" 0 "OFF (Remote engine start uncontrolled)" ;
VAL_ 818 PMN332_7_2_REQ_RES_P_LOCK 1 "REQ_RES_P_LOCK" 0 "NON_REQ" ;
VAL_ 818 PMN332_7_7_REQ_STOP_RES 1 "REQ_STOP_RES" 0 "NON_REQ" ;
VAL_ 818 PMN332_6_7_CUST 1 "ON" 0 "OFF" ;
VAL_ 818 PMN332_5_0_PUSHSTART_SW 1 "ON" 0 "OFF" ;
VAL_ 818 PMN332_5_1_SIG_KEY_PUSHSTART 1 "Key_DEFINED" 0 "Key_NOT_DEFINED" ;
VAL_ 818 PMN332_5_2_STATE_MODE_POWER 2 "RES_Start_MODE" 1 "Pre_Air_Cond_MODE" 0 "Normal_MODE" ;
VAL_ 818 PMN332_5_4_BUZ_2SHOT_IN 1 "REQ" 0 "NON_REQ" ;
VAL_ 818 PMN332_5_5_BUZ_INTERMIT1_IN 1 "REQ" 0 "NON_REQ" ;
VAL_ 818 PMN332_5_6_BUZ_INTERMIT2_IN 1 "REQ" 0 "NON_REQ" ;
VAL_ 818 PMN332_5_7_BUZ_CONTINUE_IN 1 "REQ" 0 "NON_REQ" ;
VAL_ 818 PMN332_2_0_WARN_SSP_SIG1 1 "SMART_FAIL_WARN" 0 "NON_REQ" ;
VAL_ 818 PMN332_2_1_WARN_SSP_SIG2 4 "TIMER_RESET_DISPLAY" 3 "30S_BEFORE_ENGINE_STOP" 2 "SMART_EMERGENCY_STOP_OPERATION" 1 "SMART_FAIL_WARN" 0 "NON_REQ" ;
VAL_ 818 PMN332_2_4_SMT_PWR_SIG 2 "IGNITION_ON_IND" 1 "ACCESSORY_IND" 0 "NON_REQ" ;
VAL_ 818 PMN332_2_7_BUZ_1SHOT_IN 1 "REQ" 0 "NON_REQ" ;
VAL_ 1600 SMT640_7_0_RES_CONTROL_STATUS 3 "Termination for Remote engine start control" 2 "Remote engine start heating operation" 1 "Remote engine start starting control" 0 "OFF" ;
VAL_ 1600 SMT640_7_2_REQ_RES_P_LOCK 1 "REQ_RES_P_LOCK" 0 "NON_REQ" ;
VAL_ 1600 SMT640_7_4_KEY_STATUS 1 "OK" 0 "NG or Checking" ;
VAL_ 1600 SMT640_7_5_KEY_SEARCH_RESULT 3 "Undefined(unused)" 2 "presence of access key" 1 "absence of access key" 0 "uncontrolled or being confirmed" ;
VAL_ 1600 SMT640_7_7_REQ_STOP_RES 1 "REQ_STOP_RES" 0 "NON_REQ" ;
VAL_ 1600 SMT640_5_1_IND_SECURITY 3 "IMB_IND_TurnOFF_PRIORITY" 2 "IMB_IND_BLINK" 1 "IMB_IND_TurnON" 0 "IMB_IND_TurnOFF" ;
VAL_ 1600 SMT640_5_3_BUZ_WAL_WIUL_PAUSE 1 "ON" 0 "OFF" ;
VAL_ 1600 SMT640_5_4_BUZ_ALA_MAX 1 "BUZZER_MAX_ON" 0 "BUZZER_MAX_OFF" ;
VAL_ 1600 SMT640_5_5_PRG_LOCK_SW_STATE 1 "PRG_LOCK_SW_ON" 0 "PRG_LOCK_SW_OFF" ;
VAL_ 1600 SMT640_2_4_BUZ_PAT_OUT 15 "BUZZER_STOP" 14 "BUZZER_Pattern_14" 6 "BUZZER_Pattern6" 0 "BUZZER_HOLD" ;
VAL_ 816 SMT330_7_3_HF_CAPA_ERR_ST 1 "error" 0 "normal" ;
VAL_ 816 SMT330_7_6_HF_RESP_ERR_ST 1 "error" 0 "normal" ;
VAL_ 816 SMT330_6_0_REQ_MESS_PUSHSTART 8 "Power_OFF_REQ_INDI" 7 "SHIFT_P_REQ_INDI" 6 "Power_OFF_by_Battery_Protect_INDI" 4 "(Reseved)" 3 "MT_EG_Start_Support_INDI" 2 "AT_EG_Start_Support2_INDI" 1 "AT_EG_Start_Support1_INDI" 0 "NON_REQ" ;
VAL_ 816 SMT330_6_4_WARN_SSP_SIG1 14 "EV_Get_Off_Safety2_INDI" 13 "EV_Get_Off_Safety1_INDI" 12 "AT_EG_Start_Support4_INDI" 11 "(Reserved)AT_EG_Start_Support3_INDI" 10 "KEY_Battery_LOW_WARN" 9 "(AS1 series only)EG_Start_OK_INDI" 8 "(AS1 series only)POWER_ON_INDI" 7 "NO_KEY_WARN" 6 "EG_Start_OK_INDI（MT）" 5 "Emergency_OPERATE_INDI_(MT)" 4 "Emergency_OPERATE_INDI_(AT)" 3 "EG_Start_OK_INDI（AT）" 2 "Steering_Lock_NON_Release_WARN" 1 "SMART_FAIL_WARN" 0 "NON_REQ" ;
VAL_ 816 SMT330_5_2_WAL_CUST 1 "SW_FAIL" 0 "Normal" ;
VAL_ 816 SMT330_5_3_WARN_SSP_SIG2 2 "SHIFT_POS_WARN" 1 "POWER_OFF_OPERATE_REQ" 0 "NON_REQ" ;
VAL_ 816 SMT330_5_5_WARN_SSP_SIG3 4 "KEY_Leaved_WARN" 3 "(Reserved)" 2 "EG_Start_OPERATE_INDI_MT" 1 "EG_Start_OPERATE_INDI_AT" 0 "NON_REQ" ;
VAL_ 816 SMT330_4_0_PUSHSTART_SW 1 "ON" 0 "OFF" ;
VAL_ 816 SMT330_4_1_SIG_KEY_PUSHSTART 1 "Key_DEFINED" 0 "Key_NOT_DEFINED" ;
VAL_ 816 SMT330_4_2_HF_TOUCH_STATUS 7 "initialize" 6 "(rezerved)" 5 "stop" 4 "stay" 3 "release" 2 "hold" 1 "approach" 0 "absence" ;
VAL_ 816 SMT330_4_5_HF_KICK_STATUS 17 "hand sensor" 16 "(reserved)" 1 "detection" 0 "undetected" ;
VAL_ 816 SMT330_3_0_BUZ_1SHOT_IN 1 "REQ" 0 "NON_REQ" ;
VAL_ 816 SMT330_3_1_BUZ_2SHOT_IN 1 "REQ" 0 "NON_REQ" ;
VAL_ 816 SMT330_3_2_BUZ_INTERMIT1_IN 1 "REQ" 0 "NON_REQ" ;
VAL_ 816 SMT330_3_3_BUZ_INTERMIT2_IN 1 "REQ" 0 "NON_REQ" ;
VAL_ 816 SMT330_3_4_BUZ_CONTINUE_IN 1 "REQ" 0 "NON_REQ" ;
VAL_ 816 SMT330_3_5_BUZ_TRPON_OK_IN 1 "REQ" 0 "NON_REQ" ;
VAL_ 816 SMT330_3_6_STATE_MODE_POWER 2 "RES_Start_MODE" 1 "Pre_Air_Cond_MODE" 0 "Normal_MODE" ;
VAL_ 816 SMT330_1_4_WAKE_UP_FRAME 1 "WakeUP_FRAME" 0 "Normal_FRAME" ;
VAL_ 816 SMT330_1_5_REQ_COMM_CONT 1 "REQ" 0 "NON_REQ" ;
VAL_ 1622 BIU656_6_0_KICK_OPEN_REQ_PRG 1 "ACTIVE" 0 "NON_ACTIVE" ;
VAL_ 1622 BIU656_6_1_KICK_CLOSE_REQ_PRG 1 "ACTIVE" 0 "NON_ACTIVE" ;
VAL_ 1622 BIU656_6_6_CARGO_LAMP_OUT 1 "Turn_ON" 0 "Turn_OFF" ;
VAL_ 1622 BIU656_6_7_PERMITT_KEY_RG_UNL 1 "PERMIT" 0 "INHIBIT" ;
VAL_ 1622 BIU656_5_0_PRG_DRVR_OPENERSW 1 "ON" 0 "OFF" ;
VAL_ 1622 BIU656_5_1_HF_PRG_OFF_SW 1 "ON" 0 "OFF" ;
VAL_ 1622 BIU656_5_2_PERMIT_OPEN_RG 1 "PERMIT" 0 "INHIBIT" ;
VAL_ 1622 BIU656_5_3_BUZ_ON_OFF 1 "ON" 0 "OFF" ;
VAL_ 1622 BIU656_5_4_PRG_DRVR_SW_PERMIT 1 "PERMIT" 0 "INHIBIT" ;
VAL_ 1622 BIU656_5_5_CSTM_HF_PRG_LOCK 1 "ACTIVE" 0 "NON_ACTIVE" ;
VAL_ 1622 BIU656_5_6_CSTM_KICK_SENSOR 1 "ACTIVE" 0 "NON_ACTIVE" ;
VAL_ 1622 BIU656_5_7_KICK_REQ_PRG 1 "ACTIVE" 0 "NON_ACTIVE" ;
VAL_ 1622 BIU656_4_0_NOT_SMT_KEY_RG_SW 3 "No_definition" 2 "Long_Key_Press" 1 "Short_Key_Press" 0 "OFF" ;
VAL_ 1622 BIU656_4_2_SMT_KEY_RG_SW 3 "No_definition" 2 "Long_Key_Press" 1 "Short_Key_Press" 0 "OFF" ;
VAL_ 1622 BIU656_4_4_OPEN_RG_OPENER_SW 3 "No_definition" 2 "Long_Key_Press" 1 "Short_Key_Press" 0 "OFF" ;
VAL_ 1622 BIU656_3_4_CHECKED_KEYNO 7 "SMT_KEY_7" 6 "SMT_KEY_6" 5 "SMT_KEY_5" 4 "SMT_KEY_4" 3 "SMT_KEY_3" 2 "SMT_KEY_2" 1 "SMT_KEY_1" 0 "Unregistered" ;
VAL_ 1622 BIU656_3_7_LOCKSTATUS_DRVR 1 "UNLOCK" 0 "LOCK" ;
VAL_ 1620 BIU654_7_4_KEYSW 1 "ON" 0 "OFF" ;
VAL_ 1620 BIU654_7_5_ALARM 1 "FAIL" 0 "NORMAL" ;
VAL_ 1620 BIU654_7_6_RES_STOP_JPN 1 "REQ" 0 "NON_REQ" ;
VAL_ 1618 BIU652_7_0_IND_SECURITY_IMB 6 "WARNING by the supersonic wave sensor" 5 "WARNING by the impact sensor" 4 "ALARM by the supersonic wave sensor" 3 "ALARM by the impact sensor" 7 "ALARM by open the hood" 2 "ALARM by open the trunk" 1 "ALARM by open the door" 240 "Four flashing with the immobilize" 224 "Three flashing by the immobilizer" 208 "Two flashing by the immobilizer" 192 "One flashing by the immobilizer" 144 "Flashing by the immobilizer" 128 "Lighting by the immobilizer" 112 "Lighting by the panic mode" 96 "Wait flashing by ALARM" 80 "Flashing by ALARM" 64 "Lighting by ALARM" 0 "OFF" ;
VAL_ 1618 BIU652_6_0_OCCUPATION_3RDRH 1 "ON" 0 "OFF" ;
VAL_ 1618 BIU652_6_1_OCCUPATION_3RDCTR 1 "ON" 0 "OFF" ;
VAL_ 1618 BIU652_6_2_OCCUPATION_3RDLH 1 "ON" 0 "OFF" ;
VAL_ 1618 BIU652_6_3_OCCUPATION_RRRH 1 "ON" 0 "OFF" ;
VAL_ 1618 BIU652_6_4_OCCUPATION_RRCTR 1 "ON" 0 "OFF" ;
VAL_ 1618 BIU652_6_5_OCCUPATION_RRLH 1 "ON" 0 "OFF" ;
VAL_ 1618 BIU652_6_6_HORNHAZARD_RES_SIG 1 "ON" 0 "OFF" ;
VAL_ 1618 BIU652_6_7_OCCUPATION_DRVR 1 "ON" 0 "OFF" ;
VAL_ 1618 BIU652_5_0_STATUS_ROOMLAMP 7 "TURN_ON_α_S4" 6 "TURN_ON_α_S3A" 5 "TURN_ON_α_S3" 4 "TURN_ON_Pattern2_S2A" 3 "TURN_ON_Pattern1_S2" 2 "TURN_OFF_Pattern2_S1A" 1 "TURN_OFF_Pattern1_S1" 0 "TURN_OFF_S0" ;
VAL_ 1618 BIU652_5_3_HEADLAMP_SMALL 1 "Turn_ON" 0 "Turn_OFF" ;
VAL_ 1618 BIU652_5_4_ALL_UNLOCK_STATE 1 "ON" 0 "OFF" ;
VAL_ 1618 BIU652_5_5_DRVR_UNLOCK_STATE 1 "ON" 0 "OFF" ;
VAL_ 1618 BIU652_5_6_ALL_LOCK_STATE 1 "ON" 0 "OFF" ;
VAL_ 1618 BIU652_3_0_DOOR_DRVR 1 "OPEN" 0 "CLOSE" ;
VAL_ 1618 BIU652_3_1_DOOR_PASS 1 "OPEN" 0 "CLOSE" ;
VAL_ 1618 BIU652_3_2_DOOR_RRRH 1 "OPEN" 0 "CLOSE" ;
VAL_ 1618 BIU652_3_3_DOOR_RRLH 1 "OPEN" 0 "CLOSE" ;
VAL_ 1618 BIU652_3_4_DOOR_RG 1 "OPEN" 0 "CLOSE" ;
VAL_ 1618 BIU652_3_5_DOOR_TR 1 "OPEN" 0 "CLOSE" ;
VAL_ 1618 BIU652_3_7_OPENSW_RG 1 "ON" 0 "OFF" ;
VAL_ 1618 BIU652_2_0_LOCKSTATUS_DRVR 1 "UNLOCK" 0 "LOCK" ;
VAL_ 1618 BIU652_2_1_LOCKSTATUS_PASS 1 "UNLOCK" 0 "LOCK" ;
VAL_ 1618 BIU652_2_2_LOCKSTATUS_RRRH 1 "UNLOCK" 0 "LOCK" ;
VAL_ 1618 BIU652_2_3_LOCKSTATUS_RRLH 1 "UNLOCK" 0 "LOCK" ;
VAL_ 1618 BIU652_2_4_LOCKSTATUS_RG 1 "UNLOCK OR PERMIT_UNLOCK" 0 "LOCK OR PROHIBIT_UNLOOK" ;
VAL_ 1618 BIU652_2_6_UNLOCK_DOORKEYSW 1 "ON" 0 "OFF" ;
VAL_ 1618 BIU652_2_7_LOCK_DOORKEYSW 1 "ON" 0 "OFF" ;
VAL_ 1617 BIU651_7_0_PWPOS_RL 3 "other" 2 "ALL CLOSE" 1 "ALL OPEN" 0 "INDEFINITE" ;
VAL_ 1617 BIU651_7_2_PWPOS_RR 3 "other" 2 "ALL CLOSE" 1 "ALL OPEN" 0 "INDEFINITE" ;
VAL_ 1617 BIU651_7_4_PWPOS_PASS 3 "other" 2 "ALL CLOSE" 1 "ALL OPEN" 0 "INDEFINITE" ;
VAL_ 1617 BIU651_7_6_PWPOS_DRVR 3 "other" 2 "ALL CLOSE" 1 "ALL OPEN" 0 "INDEFINITE" ;
VAL_ 1617 BIU651_6_0_IND_ACTIVE_HBA 3 "NONE" 2 "BLINK" 1 "Turn_ON" 0 "Turn_OFF" ;
VAL_ 1617 BIU651_6_2_ADB_ACTIVE 1 "ACTIVE" 0 "NON_ACTIVE" ;
VAL_ 1617 BIU651_6_3_JUDGE_ILL 1 "ACTIVE" 0 "NON_ACTIVE" ;
VAL_ 1617 BIU651_6_4_TYPE_LO_BEAM 3 "NONE" 2 "LED" 1 "HID" 0 "HALOGEN" ;
VAL_ 1617 BIU651_6_6_TYPE_HI_BEAM 3 "NONE" 2 "LED" 1 "HID" 0 "HALOGEN" ;
VAL_ 1617 BIU651_5_0_SRF_ACTIVE 1 "ACTIVE" 0 "NON_ACTIVE" ;
VAL_ 1617 BIU651_5_1_SRF_IND 3 "NONE" 2 "BLINK" 1 "Turn_ON" 0 "Turn_OFF" ;
VAL_ 1617 BIU651_5_3_SRF_LAMP_LIGHT 1 "Turn_ON" 0 "Turn_OFF" ;
VAL_ 1617 BIU651_5_4_SRF_LAMP_LEFT 1 "Turn_ON" 0 "Turn_OFF" ;
VAL_ 1617 BIU651_5_5_MSG_STATUS_HBA 3 "NONE" 2 "FAIL" 1 "HALT" 0 "OFF" ;
VAL_ 1617 BIU651_5_7_IND_FAIL_HBA 1 "Turn_ON" 0 "Turn_OFF" ;
VAL_ 1617 BIU651_4_0_BUZ_PATTERN 8 "NON" 7 "Customize_2" 6 "Customize_1" 5 "NON" 4 "NON" 3 "Light_Warning" 2 "Key_Warning" 1 "Reverse_BUZZ" 0 "BUZZ_STOP" ;
VAL_ 1617 BIU651_4_4_CSTM_OPE_ALARM 3 "NON" 2 "OFF" 1 "ON" 0 "BLINK" ;
VAL_ 1617 BIU651_4_6_CSTM_HBA 3 "BLANK" 2 "MIRROR_HBA" 1 "EYESIGHT_HBA" 0 "NON_ACTIVE" ;
VAL_ 1617 BIU651_3_0_HEADLAMP_PASS_SW 1 "ON" 0 "OFF" ;
VAL_ 1617 BIU651_3_1_HEADLAMP_AUTO_SW 1 "ON" 0 "OFF" ;
VAL_ 1617 BIU651_3_2_JUDGE_DOOR_LOCK 1 "REQ" 0 "NON_REQ" ;
VAL_ 1617 BIU651_3_3_JUDGE_DOOR_UNLOCK 1 "CONNECT" 0 "NON_CONNECT" ;
VAL_ 1617 BIU651_3_4_HEADLAMP_Lo_SW 1 "ON" 0 "OFF" ;
VAL_ 1617 BIU651_3_5_HEADLAMP_HI_SW 1 "ON" 0 "OFF" ;
VAL_ 1617 BIU651_3_6_WIPER_AUTO_SW 1 "ON" 0 "OFF" ;
VAL_ 1617 BIU651_3_7_PRG_LIN_MEMORY_ON_OFF 1 "ON" 0 "OFF" ;
VAL_ 1617 BIU651_2_0_CSTM_ILLUMI_SSR 1 "ACTIVE" 0 "NON_ACTIVE" ;
VAL_ 1617 BIU651_2_1_HANDLE 1 "RHD" 0 "LHD" ;
VAL_ 1617 BIU651_2_2_CSTM_SMT 1 "SMART" 0 "NOT SMART" ;
VAL_ 1617 BIU651_2_3_AJARDOOR_STATUS 1 "AJAR_DOOR" 0 "NOT_AJAR_DOOR" ;
VAL_ 1617 BIU651_2_4_ONETOUCH_LAMP_OUT 1 "ON" 0 "OFF" ;
VAL_ 1617 BIU651_2_5_PRG_FAIL_FLAG 1 "ON" 0 "OFF" ;
VAL_ 1617 BIU651_2_6_CSTM_PSMECU 1 "ACTIVE" 0 "NON_ACTIVE" ;
VAL_ 1617 BIU651_2_7_STATE_REGIST_DEL 1 "FINISIED" 0 "NOT_FINISIED" ;
VAL_ 1617 BIU651_1_4_SRPOS 7 "未使用" 6 "未使用" 5 "チルト区間で開" 4 "スライド区間で開" 3 "全閉" 2 "チルト全開" 1 "スライド全開" 0 "不定" ;
VAL_ 1617 BIU651_1_7_WIPER_INT_STATUS 1 "INT_ON" 0 "INT_OFF" ;
VAL_ 940 BIU3AC_7_0_HEADLAMP_SMALL 1 "Turn_ON" 0 "Turn_OFF" ;
VAL_ 940 BIU3AC_7_1_HEADLAMP_LO_REQ 1 "Turn_ON" 0 "Turn_OFF" ;
VAL_ 940 BIU3AC_7_2_HEADLAMP_HI_REQ 1 "Turn_ON" 0 "Turn_OFF" ;
VAL_ 940 BIU3AC_7_3_FT_FOG_RELAY_REQ 1 "Turn_ON" 0 "Turn_OFF" ;
VAL_ 940 BIU3AC_7_4_FOGLAMP_RR 1 "Turn_ON" 0 "Turn_OFF" ;
VAL_ 940 BIU3AC_7_5_DRL 1 "Turn_ON" 0 "Turn_OFF" ;
VAL_ 940 BIU3AC_7_6_WIPER_FRONT 1 "ON" 0 "OFF" ;
VAL_ 940 BIU3AC_7_7_RDEF_RELAY_REQ 1 "ON" 0 "OFF" ;
VAL_ 940 BIU3AC_6_0_RDEFOGSW 1 "ON" 0 "OFF" ;
VAL_ 940 BIU3AC_6_1_CSTM_PRG 1 "PRG" 0 "NOT_PRG" ;
VAL_ 940 BIU3AC_6_2_FAIL_SHIFTLOCKSOL 1 "FAIL" 0 "NORMAL" ;
VAL_ 940 BIU3AC_6_3_REQ_CANCEL_ISS 1 "CANCEL" 0 "NON_CANCEL" ;
VAL_ 940 BIU3AC_6_4_REVERSE_MT 1 "REVERSE_ON" 0 "OFF" ;
VAL_ 940 BIU3AC_6_5_HANDBRAKE 1 "ON" 0 "OFF" ;
VAL_ 940 BIU3AC_6_6_BRAKELAMPSW 1 "ON" 0 "OFF" ;
VAL_ 940 BIU3AC_6_7_TOWING_SW 1 "ON" 0 "OFF" ;
VAL_ 940 BIU3AC_5_0_LANE_OFF_SW 3 "NONE" 2 "BREAKING_OF_WIRE" 1 "P-CR-OFF-SW_ON" 0 "OFF" ;
VAL_ 940 BIU3AC_5_2_PCR_OFF_SW 3 "NONE" 2 "BREAKING_OF_WIRE" 1 "P-CR-OFF-SW_ON" 0 "OFF" ;
VAL_ 940 BIU3AC_5_4_DIMMER_CANCEL 1 "ACTIVE" 0 "NON_ACTIVE" ;
VAL_ 940 BIU3AC_5_5_KEYSW 1 "ON" 0 "OFF" ;
VAL_ 940 BIU3AC_5_6_IND_ND_SHIFTLOCK 1 "表示" 0 "非表示" ;
VAL_ 940 BIU3AC_4_0_DOOR_DRVR 1 "OPEN" 0 "CLOSE" ;
VAL_ 940 BIU3AC_4_1_DOOR_PASS 1 "OPEN" 0 "CLOSE" ;
VAL_ 940 BIU3AC_4_2_DOOR_RRRH 1 "OPEN" 0 "CLOSE" ;
VAL_ 940 BIU3AC_4_3_DOOR_RRLH 1 "OPEN" 0 "CLOSE" ;
VAL_ 940 BIU3AC_4_4_DOOR_RG 1 "OPEN" 0 "CLOSE" ;
VAL_ 940 BIU3AC_4_5_DOOR_TR 1 "OPEN" 0 "CLOSE" ;
VAL_ 940 BIU3AC_4_6_HOOD_CLOSE 1 "ON" 0 "OFF" ;
VAL_ 940 BIU3AC_4_7_HOOD_OPEN 1 "ON" 0 "OFF" ;
VAL_ 940 BIU3AC_3_0_GW_STSW_RES 1 "REQ_RES_EGStart" 0 "NON_REQ_RES_EGStart" ;
VAL_ 940 BIU3AC_3_1_GW_POWER_RES 2 "RES_Start_MODE" 1 "Pre_Air_Cond_MODE" 0 "Normal_MODE" ;
VAL_ 940 BIU3AC_3_3_ST1 1 "ST" 0 "NORMAL" ;
VAL_ 940 BIU3AC_3_4_ST2 1 "ST" 0 "NORMAL" ;
VAL_ 940 BIU3AC_3_5_ACC 1 "ON" 0 "OFF" ;
VAL_ 940 BIU3AC_3_6_IGA 1 "ON" 0 "OFF" ;
VAL_ 940 BIU3AC_3_7_BAT_BACKUP 1 "ON" 0 "OFF" ;
VAL_ 940 BIU3AC_2_0_CSTM_AC 1 "ACTIVE" 0 "NON_ACTIVE" ;
VAL_ 940 BIU3AC_2_1_IMB_SMT 3 "Push&SMT" 2 "IMB_NO" 1 "IMB_YES" 0 "NON" ;
VAL_ 940 BIU3AC_2_3_CSTM_WGN_SDN 1 "WGN" 0 "SDN" ;
VAL_ 940 BIU3AC_2_4_VAL_SEAT_BACK_CTSM 1 "SEAT_BACK_ON" 0 "SEAT_BACK_OFF" ;
VAL_ 940 BIU3AC_2_5_VAL_MIR_AFOLD_CTSM 1 "MIR_AFOLD_ON" 0 "MIR_AFOLD_OFF" ;
VAL_ 940 BIU3AC_2_6_VAL_MIR_RTILT_CTSM 1 "MIR_RTILT_ON" 0 "MIR_RTILT_OFF" ;
VAL_ 940 BIU3AC_2_7_WIPER_REAR 1 "ON" 0 "OFF" ;
VAL_ 940 BIU3AC_1_4_PADDLESHIFT_DOWN_SW 1 "ON" 0 "OFF" ;
VAL_ 940 BIU3AC_1_5_PADDLESHIFT_UP_SW 1 "ON" 0 "OFF" ;
VAL_ 940 BIU3AC_1_6_MANUALMODE_SW 1 "ON" 0 "OFF" ;
VAL_ 1616 BIU650_7_3_DOOR_LINK_SW_STS 1 "ON" 0 "OFF" ;
VAL_ 1616 BIU650_6_3_RR_WIPER_STATUS 3 "Undefined" 2 "Hi" 1 "Lo" 0 "OFF" ;
VAL_ 1616 BIU650_6_5_WIPER_SENSITIVITY_CTM 3 "4" 2 "3" 1 "2" 0 "1" ;
VAL_ 1616 BIU650_5_2_FMH_DOOR_LOCK 3 "Undefined" 2 "Unlock" 1 "Lock" 0 "No request" ;
VAL_ 1616 BIU650_5_4_LMH_DOOR_LOCK 3 "Undefined" 2 "Unlock" 1 "Lock" 0 "No request" ;
VAL_ 1616 BIU650_4_0_REQ_OPE_AUTOLIGHT 3 "Undefined" 2 "Lo" 1 "Small" 0 "OFF" ;
VAL_ 1616 BIU650_4_2_STATE_SHINSSR 3 "Normal Mode" 2 "Diagnostic Mode" 1 "Shipping Inspection Mode" 0 "Initialization Mode" ;
VAL_ 1616 BIU650_4_4_STATE_RLS_FAIL 3 "Undefined" 2 "Recovering" 1 "Abnormal" 0 "Normal" ;
VAL_ 1616 BIU650_3_0_REQ_FWASHER_ITLOCK 1 "ON" 0 "OFF" ;
VAL_ 1616 BIU650_3_1_FWIPER_RTN 1 "ON" 0 "OFF" ;
VAL_ 1616 BIU650_3_2_TURN_LAMP_STATE_LEFT 1 "Blink" 0 "OFF" ;
VAL_ 1616 BIU650_3_3_TURN_LAMP_STATE_RIGHT 1 "Blink" 0 "OFF" ;
VAL_ 1616 BIU650_2_0_HEADLAMP_SMALL_SW 1 "ON" 0 "OFF" ;
VAL_ 1616 BIU650_2_1_HEADLAMP_LO_SW 1 "ON" 0 "OFF" ;
VAL_ 1616 BIU650_2_2_HEADLAMP_OFF_SW 1 "ON" 0 "OFF" ;
VAL_ 1616 BIU650_2_3_HEADLAMP_Hi_SW 1 "ON" 0 "OFF" ;
VAL_ 1616 BIU650_2_4_HEAD_LAMP_PASS_SW 1 "ON" 0 "OFF" ;
VAL_ 1616 BIU650_2_5_FFOG_SW 1 "ON" 0 "OFF" ;
VAL_ 1616 BIU650_2_6_RFOG_SW 1 "ON" 0 "OFF" ;
VAL_ 280 EPS118_7_0_IND_FAIL_MULTI 6 "Turn_ON_and_BUZZ_ON(Voltage_Drop/ENG_Stall)" 5 "Turn_ON_SSR_Calib" 4 "Turn_ON(3s_After_IGN_ON)" 3 "Turn_ON_and_BUZZ_ON(FAIL)" 2 "BLINK_4Hz(TEST_MODE)" 1 "TC-ON(Turn_OFF)" 0 "Turn_OFF(Normal)" ;
VAL_ 280 EPS118_7_3_UNDER_BACKUP_CTRL 1 "BACKUP" 0 "NORMAL" ;
VAL_ 280 EPS118_7_4_HANDSFREE_PERMIT_FLAG 1 "Permit" 0 "Non Permit" ;
VAL_ 280 EPS118_7_5_PROHIBIT_CONT_ISS 1 "PROHIBIT" 0 "PERMIT" ;
VAL_ 280 EPS118_7_6_LVL_ASSIST 2 "ASSIST_LIMIT" 1 "ASSIST_STOP" 0 "NORMAL" ;
VAL_ 280 EPS118_1_4_FAIL_EPS 1 "FAIL" 0 "NORMAL" ;
VAL_ 859 DAM35B_4_0_EYE_CONTROL_FLAG 3 "undefine" 2 "undefine" 1 "Operation" 0 "No Operation" ;
VAL_ 859 DAM35B_3_0_WARNING_LAMP 3 "undefine" 2 "undefine" 1 "ON(fail)" 0 "OFF(normal)" ;
VAL_ 859 DAM35B_3_2_DAMPER_MODE 7 "undefine" 6 "undefine" 5 "undefine" 4 "undefine" 3 "Sport" 2 "Normal" 1 "Comfort" 0 "Default" ;
VAL_ 859 DAM35B_3_5_FAIL_FLAG_FOR_CCU 1 "FAIL" 0 "NORMAL" ;
VAL_ 859 DAM35B_3_6_FAIL_FLAG_DAMPER 3 "FAIL_STEP3" 2 "FAIL_STEP2" 1 "FAIL_STEP1" 0 "NORMAL" ;
VAL_ 811 EPB32B_6_0_VEHICLE_RUN_STOP_FLG 3 "reserve" 2 "ERROR" 1 "DRIVING" 0 "STOPPING" ;
VAL_ 811 EPB32B_6_2_REQ_HILL_P_CAUTION 1 "Turn_ON" 0 "Turn_OFF" ;
VAL_ 811 EPB32B_5_0_FLG_AVH_OILPRES_EPB 0 "NOT_OPERATE" 1 "OPERATE" ;
VAL_ 811 EPB32B_5_1_FLG_AVH 1 "AVH_OPERATE" 0 "AVH_NOT_OPERATE" ;
VAL_ 811 EPB32B_5_2_AVH_INTENSIFY_PRES 0 "OTHER" 1 "AVH_INTENSIFY_PRESSURE_DURING_ISS" ;
VAL_ 811 EPB32B_5_3_BREAK_IND 3 "UNDEFINED(TURN_OFF/DISPLAY OFF)" 2 "BLINK(Segment LC) or DISPLAY ON(Color LC)" 1 "TURN_ON(Segment LC) or DISPLAY ON(Color LC)" 0 "TURN_OFF(Segment LC) or DISPLAY OFF(Color LC)" ;
VAL_ 811 EPB32B_5_5_AVH_ON_LAMP 1 "ON" 0 "OFF" ;
VAL_ 811 EPB32B_5_6_AVH_FUNC_ON_LUMP 1 "ON" 0 "OFF" ;
VAL_ 811 EPB32B_5_7_AVH_ACTIVE 1 "WITH_AVH" 0 "WIITHOUT_AVH" ;
VAL_ 811 EPB32B_4_0_BUZZER 3 "CANCEL_Pi-X1" 2 "SHIFT_DISABLE_PiX2" 1 "DRIVER_BRAKE_CUE_Pi-" 0 "NO_BUZZER" ;
VAL_ 811 EPB32B_4_2_HILL_HOLD_ON_LAMP 1 "ON" 0 "OFF" ;
VAL_ 811 EPB32B_4_3_CLAMP_LAMP 3 "No_difinition" 2 "LAMP_BLINK" 1 "LAMP_ON" 0 "LAMP_OFF" ;
VAL_ 811 EPB32B_4_5_WARN_LAMP 3 "No_difinition" 2 "LAMP_BLINK" 1 "LAMP_ON" 0 "LAMP_OFF" ;
VAL_ 811 EPB32B_4_7_WARN_EPB_MET_LCD 1 "INDICATE" 0 "NOT_IINDICATE" ;
VAL_ 811 EPB32B_3_0_STATUS_EPB 7 "No_difinition" 6 "No_difinition" 5 "DYNAMIC PARKING" 4 "RELEASING" 3 "OPERATING" 2 "OPERATE" 1 "RELEASE" 0 "ERROR" ;
VAL_ 811 EPB32B_3_3_DYNAMIC_PARKING 1 "ON" 0 "OFF" ;
VAL_ 811 EPB32B_3_4_HILL_HOLD_RUN_FLG 1 "OPERATE" 0 "NOT_OPERATE" ;
VAL_ 811 EPB32B_3_5_INHIBIT_ISS_DELAY 1 "INHIBIT" 0 "PERMIT" ;
VAL_ 811 EPB32B_3_6_INHIBIT_ISS 1 "INHIBIT" 0 "PERMIT" ;
VAL_ 811 EPB32B_3_7_AVH_PERMIT_CONT_ACC 1 "PERMISSION" 0 "PROHIBITION" ;
VAL_ 811 EPB32B_2_0_ERR_INFO 3 "PULL_FORCE_FAIL" 2 "EMERGENCY_RELEASE" 1 "STROKE_SHORT" 0 "NORMAL" ;
VAL_ 811 EPB32B_2_2_EPB_FAIL_FLG1 1 "PERMIT" 0 "INHIBIT" ;
VAL_ 811 EPB32B_2_3_EPB_FAIL_FLG2 1 "PERMIT" 0 "INHIBIT" ;
VAL_ 811 EPB32B_2_4_EPB_FAIL_FLG3 1 "PERMIT" 0 "INHIBIT" ;
VAL_ 811 EPB32B_1_4_WAKE_UP_FRAME 1 "WakeUP_FRAME" 0 "Normal_FRAME" ;
VAL_ 811 EPB32B_1_5_REQ_COMM_CONT 1 "REQUEST" 0 "NO_REQUEST" ;
VAL_ 313 VDC139_7_4_FAIL_PRESSURE_SSR 1 "NORMAL" 0 "FAIL" ;
VAL_ 313 VDC139_7_5_STATUS_EPB 7 "No_difinition" 6 "AVH_OPERATE" 5 "DYNAMIC PARKING" 4 "RELEASING" 3 "OPERATING" 2 "OPERATE" 1 "RELEASE" 0 "ERROR" ;
VAL_ 313 VDC139_4_0_HDC_STATUS 3 "Uncertain(SYS_OFF)" 2 "SYS_ACTIVE" 1 "SYS_WAIT" 0 "SYS_OFF" ;
VAL_ 313 VDC139_4_2_BRAKELAMPSW 1 "ON" 0 "OFF" ;
VAL_ 313 VDC139_4_3_FAIL_BRAKELAMPSW 1 "NORMAL" 0 "FAIL" ;
VAL_ 313 VDC139_4_4_ACTIVATE_ABS 1 "ACTIVE" 0 "NON_ACTIVE" ;
VAL_ 313 VDC139_4_5_ACTIVATE_TCS 1 "ACTIVE" 0 "NON_ACTIVE" ;
VAL_ 313 VDC139_4_6_CONT_OVER_STR 1 "control" 0 "NON_Control" ;
VAL_ 313 VDC139_4_7_CONT_UNDER_STR 1 "control" 0 "NON_Control" ;
VAL_ 313 VDC139_3_5_FAIL_VDC_SSR 1 "NORMAL" 0 "FAIL" ;
VAL_ 313 VDC139_3_6_FAIL_SPD_SSR_FHI 1 "NORMAL" 0 "FAIL" ;
VAL_ 313 VDC139_3_7_FAIL_ABS_SYS 1 "NORMAL" 0 "FAIL" ;
VAL_ 313 VDC139_1_4_FAIL_HDC_SYS 1 "NORMAL" 0 "FAIL" ;
VAL_ 313 VDC139_1_5_VEHICLE_HIGHT 2 "STANDARD" 1 "OBK" 0 "NON" ;
VAL_ 313 VDC139_1_7_REPROGRAMING 1 "STOP_Diag&COMM" 0 "NORMAL" ;
VAL_ 312 VDC138_1_4_ACTIVE_LDP 1 "ACTIVE" 0 "NON_ACTIVE" ;
VAL_ 312 VDC138_1_5_PROHIBIT_LDP 1 "PROHIBIT" 0 "PERMIT" ;
VAL_ 312 VDC138_1_6_VDC_SMALL_MARGIN 1 "SMALL MARGIN" 0 "NOMAL" ;
VAL_ 312 VDC138_1_7_DETECT_REAR_SLIP 1 "CONTROL" 0 "NOT_CONTROL" ;
VAL_ 1712 CCU6B0_7_0_AIL_CSTM_PRS_REQ 1 "required" 0 "NOT_required" ;
VAL_ 1712 CCU6B0_7_1_AIL_RENDER_REQ 5 "CUSTOM" 4 "DR_MD_Linkage" 3 "PAT_D" 2 "PAT_C" 1 "PAT_B" 0 "PAT_A" ;
VAL_ 1712 CCU6B0_3_0_AIL_ADAS_VEH_DIS_REQ 1 "ON" 0 "OFF" ;
VAL_ 1712 CCU6B0_3_1_AIL_ADAS_LANE_DEV_REQ 1 "ON" 0 "OFF" ;
VAL_ 1712 CCU6B0_3_2_AIL_ADAS_FT_CROSS_REQ 1 "ON" 0 "OFF" ;
VAL_ 1712 CCU6B0_3_3_AIL_ADAS_HANDS_FR_REQ 1 "ON" 0 "OFF" ;
VAL_ 1712 CCU6B0_2_0_AIL_WEL_FOL_REQ 1 "ON" 0 "OFF" ;
VAL_ 1712 CCU6B0_2_1_AIL_ADAS_EXP_REQ 1 "ON" 0 "OFF" ;
VAL_ 1712 CCU6B0_2_2_AIL_NOTIFI_EXP_REQ 1 "ON" 0 "OFF" ;
VAL_ 1712 CCU6B0_2_3_AIL_AIR_CON_EXP_REQ 1 "ON" 0 "OFF" ;
VAL_ 1712 CCU6B0_1_4_AIL_CUSTOM_REQ 1 "required" 0 "NOT_required" ;
VAL_ 1712 CCU6B0_1_5_AIL_CUSTOM_RESET_REQ 1 "required" 0 "NOT_required" ;
VAL_ 1712 CCU6B0_1_6_AIL_ON_OFF_REQ 1 "ON" 0 "OFF" ;
